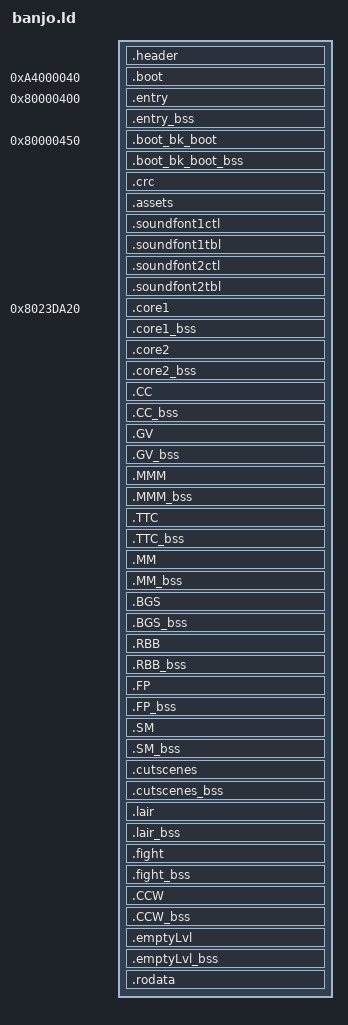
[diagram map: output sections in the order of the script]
SECTIONS
{
    __romPos = 0;
    _gp = 0x0;
    header_ROM_START = __romPos;
    header_VRAM = ADDR(.header);
    .header : AT(header_ROM_START) SUBALIGN(16)
    {
        header_DATA_START = .;
        header_s = .;
        build/us.v10/asm/header.s.o(.data);
        header_DATA_END = .;
        header_DATA_SIZE = ABSOLUTE(header_DATA_END - header_DATA_START);
    }
    __romPos += SIZEOF(.header);
    header_ROM_END = __romPos;
    header_VRAM_END = .;

    boot_ROM_START = __romPos;
    boot_VRAM = ADDR(.boot);
    .boot 0xA4000040 : AT(boot_ROM_START) SUBALIGN(16)
    {
        boot_DATA_START = .;
        ipl3_bin = .;
        build/us.v10/bin/ipl3.bin.o(.data);
        ipl3font_bin = .;
        build/us.v10/bin/ipl3font.bin.o(.data);
        boot_DATA_END = .;
        boot_DATA_SIZE = ABSOLUTE(boot_DATA_END - boot_DATA_START);
    }
    __romPos += SIZEOF(.boot);
    __romPos = ALIGN(__romPos, 16);
    boot_ROM_END = __romPos;
    boot_VRAM_END = .;

    entry_ROM_START = __romPos;
    entry_VRAM = ADDR(.entry);
    .entry 0x80000400 : AT(entry_ROM_START) SUBALIGN(16)
    {
        entry_TEXT_START = .;
        build/us.v10/asm/entry.s.o(.text);
        entry_TEXT_END = .;
        entry_TEXT_SIZE = ABSOLUTE(entry_TEXT_END - entry_TEXT_START);
        entry_DATA_START = .;
        entry_s = .;
        build/us.v10/asm/entry.s.o(.data);
        entry_DATA_END = .;
        entry_DATA_SIZE = ABSOLUTE(entry_DATA_END - entry_DATA_START);
        entry_RODATA_START = .;
        build/us.v10/asm/entry.s.o(.rodata);
        entry_RODATA_END = .;
        entry_RODATA_SIZE = ABSOLUTE(entry_RODATA_END - entry_RODATA_START);
    }
    entry_bss_VRAM = ADDR(.entry_bss);
    .entry_bss (NOLOAD) : SUBALIGN(16)
    {
        entry_BSS_START = .;
        build/us.v10/asm/entry.s.o(.bss);
        entry_BSS_END = .;
        entry_BSS_SIZE = ABSOLUTE(entry_BSS_END - entry_BSS_START);
    }
    __romPos += SIZEOF(.entry);
    __romPos = ALIGN(__romPos, 16);
    entry_ROM_END = __romPos;
    entry_VRAM_END = .;

    boot_bk_boot_ROM_START = __romPos;
    boot_bk_boot_VRAM = ADDR(.boot_bk_boot);
    .boot_bk_boot 0x80000450 : AT(boot_bk_boot_ROM_START) SUBALIGN(16)
    {
        boot_bk_boot_TEXT_START = .;
        build/us.v10/src/done/bk_boot_1050.c.o(.text);
        build/us.v10/src/done/rarezip.c.o(.text);
        build/us.v10/src/done/inflate.c.o(.text);
        build/us.v10/src/done/overlays.c.o(.text);
        build/us.v10/src/done/initialize.c.o(.text);
        build/us.v10/src/done/pirawdma.c.o(.text);
        build/us.v10/src/done/pigetstat.c.o(.text);
        build/us.v10/asm/bzero.s.o(.text);
        build/us.v10/asm/setsr.s.o(.text);
        build/us.v10/asm/getsr.s.o(.text);
        build/us.v10/asm/setfpccsr.s.o(.text);
        build/us.v10/src/done/sirawread.c.o(.text);
        build/us.v10/src/done/sirawwrite.c.o(.text);
        build/us.v10/asm/ultra/exceptasm.s.o(.text);
        build/us.v10/asm/writebackdcache.s.o(.text);
        build/us.v10/asm/invalicache.s.o(.text);
        build/us.v10/asm/maptlbrdb.s.o(.text);
        build/us.v10/src/done/pirawread.c.o(.text);
     
        build/us.v10/asm/ultra/parameters.s.o(.text);
        build/us.v10/src/done/virtualtophysical.c.o(.text);
        build/us.v10/src/done/si.c.o(.text);
        build/us.v10/src/done/thread.c.o(.text);
        build/us.v10/src/done/leointerrupt.c.o(.text);
        build/us.v10/src/done/seteventmesg.c.o(.text);
        build/us.v10/asm/ultra/setintmask.s.o(.text);
        build/us.v10/src/done/destroythread.c.o(.text);
        build/us.v10/asm/probetlb.s.o(.text);
        build/us.v10/src/done/leodiskinit.c.o(.text);
        build/us.v10/src/done/epirawdma.c.o(.text);
        build/us.v10/asm/interrupt.s.o(.text);
        build/us.v10/src/done/pimgr.c.o(.text);
        build/us.v10/src/done/cartrominit.c.o(.text);
        build/us.v10/src/done/createmesgqueue.c.o(.text);
        build/us.v10/src/done/piacs.c.o(.text);
        build/us.v10/src/done/getthreadpri.c.o(.text);
        build/us.v10/src/done/setthreadpri.c.o(.text);
        build/us.v10/src/done/createthread.c.o(.text);
        build/us.v10/src/done/devmgr.c.o(.text);
        build/us.v10/src/done/startthread.c.o(.text);
        build/us.v10/src/done/sendmesg.c.o(.text);
        build/us.v10/src/done/recvmesg.c.o(.text);
        build/us.v10/src/done/resetglobalintmask.c.o(.text);
        build/us.v10/src/done/epirawwrite.c.o(.text);
        build/us.v10/src/done/epirawread.c.o(.text);
        build/us.v10/src/done/setglobalintmask.c.o(.text);
        build/us.v10/src/done/yieldthread.c.o(.text);
        build/us.v10/src/done/kdebugserver.c.o(.text);
        boot_bk_boot_TEXT_END = .;
        boot_bk_boot_TEXT_SIZE = ABSOLUTE(boot_bk_boot_TEXT_END - boot_bk_boot_TEXT_START);
        boot_bk_boot_DATA_START = .;
        done_inflate_c = .;
        build/us.v10/src/done/inflate.c.o(.data);
        done_initialize_c = .;
        build/us.v10/src/done/initialize.c.o(.data);
        ultra_exceptasm_s = .;
        build/us.v10/asm/ultra/exceptasm.s.o(.data);
        done_thread_c = .;
        build/us.v10/src/done/thread.c.o(.data);
        done_pimgr_c = .;
        build/us.v10/src/done/pimgr.c.o(.data);
        done_piacs_c = .;
        build/us.v10/src/done/piacs.c.o(.data);
        boot_bk_boot_DATA_END = .;
        boot_bk_boot_DATA_SIZE = ABSOLUTE(boot_bk_boot_DATA_END - boot_bk_boot_DATA_START);
        boot_bk_boot_RODATA_START = .;
        build/us.v10/asm/ultra/exceptasm.s.o(.rodata);
        build/us.v10/asm/ultra/setintmask.s.o(.rodata);
        build/us.v10/src/done/devmgr.c.o(.rodata);
        boot_bk_boot_RODATA_END = .;
        boot_bk_boot_RODATA_SIZE = ABSOLUTE(boot_bk_boot_RODATA_END - boot_bk_boot_RODATA_START);
    }
    boot_bk_boot_bss_VRAM = ADDR(.boot_bk_boot_bss);
    .boot_bk_boot_bss (NOLOAD) : SUBALIGN(16)
    {
        boot_bk_boot_BSS_START = .;
        build/us.v10/src/done/bk_boot_1050.c.o(.bss);
        build/us.v10/src/done/rarezip.c.o(.bss);
        build/us.v10/src/done/inflate.c.o(.bss);
        build/us.v10/src/done/initialize.c.o(.bss);
        build/us.v10/src/done/kdebugserver.c.o(.bss);
        build/us.v10/src/done/leointerrupt.c.o(.bss);
        build/us.v10/src/done/seteventmesg.c.o(.bss);
        build/us.v10/src/done/leodiskinit.c.o(.bss);
        build/us.v10/src/done/pimgr.c.o(.bss);
        build/us.v10/src/done/cartrominit.c.o(.bss);
        build/us.v10/src/done/piacs.c.o(.bss);
        boot_bk_boot_BSS_END = .;
        boot_bk_boot_BSS_SIZE = ABSOLUTE(boot_bk_boot_BSS_END - boot_bk_boot_BSS_START);
    }
    __romPos += SIZEOF(.boot_bk_boot);
    __romPos = ALIGN(__romPos, 16);
    boot_bk_boot_ROM_END = __romPos;
    boot_bk_boot_VRAM_END = .;

    crc_ROM_START = __romPos;
    crc_VRAM = ADDR(.crc);
    .crc : AT(crc_ROM_START) SUBALIGN(16)
    {
        crc_DATA_START = .;
        crc_bin = .;
        build/us.v10/bin/crc.bin.o(.data);
        crc_DATA_END = .;
        crc_DATA_SIZE = ABSOLUTE(crc_DATA_END - crc_DATA_START);
    }
    __romPos += SIZEOF(.crc);
    __romPos = ALIGN(__romPos, 16);
    crc_ROM_END = __romPos;
    crc_VRAM_END = .;

    assets_ROM_START = __romPos;
    assets_VRAM = ADDR(.assets);
    .assets : AT(assets_ROM_START) SUBALIGN(16)
    {
        assets_DATA_START = .;
        assets_bin = .;
        build/us.v10/bin/assets.bin.o(.data);
        assets_DATA_END = .;
        assets_DATA_SIZE = ABSOLUTE(assets_DATA_END - assets_DATA_START);
    }
    __romPos += SIZEOF(.assets);
    assets_ROM_END = __romPos;
    assets_VRAM_END = .;

    soundfont1ctl_ROM_START = __romPos;
    soundfont1ctl_VRAM = ADDR(.soundfont1ctl);
    .soundfont1ctl : AT(soundfont1ctl_ROM_START) SUBALIGN(16)
    {
        soundfont1ctl_DATA_START = .;
        soundfont1ctl_bin = .;
        build/us.v10/bin/soundfont1ctl.bin.o(.data);
        soundfont1ctl_DATA_END = .;
        soundfont1ctl_DATA_SIZE = ABSOLUTE(soundfont1ctl_DATA_END - soundfont1ctl_DATA_START);
    }
    __romPos += SIZEOF(.soundfont1ctl);
    soundfont1ctl_ROM_END = __romPos;
    soundfont1ctl_VRAM_END = .;

    soundfont1tbl_ROM_START = __romPos;
    soundfont1tbl_VRAM = ADDR(.soundfont1tbl);
    .soundfont1tbl : AT(soundfont1tbl_ROM_START) SUBALIGN(16)
    {
        soundfont1tbl_DATA_START = .;
        soundfont1tbl_bin = .;
        build/us.v10/bin/soundfont1tbl.bin.o(.data);
        soundfont1tbl_DATA_END = .;
        soundfont1tbl_DATA_SIZE = ABSOLUTE(soundfont1tbl_DATA_END - soundfont1tbl_DATA_START);
    }
    __romPos += SIZEOF(.soundfont1tbl);
    soundfont1tbl_ROM_END = __romPos;
    soundfont1tbl_VRAM_END = .;

    soundfont2ctl_ROM_START = __romPos;
    soundfont2ctl_VRAM = ADDR(.soundfont2ctl);
    .soundfont2ctl : AT(soundfont2ctl_ROM_START) SUBALIGN(16)
    {
        soundfont2ctl_DATA_START = .;
        soundfont2ctl_bin = .;
        build/us.v10/bin/soundfont2ctl.bin.o(.data);
        soundfont2ctl_DATA_END = .;
        soundfont2ctl_DATA_SIZE = ABSOLUTE(soundfont2ctl_DATA_END - soundfont2ctl_DATA_START);
    }
    __romPos += SIZEOF(.soundfont2ctl);
    soundfont2ctl_ROM_END = __romPos;
    soundfont2ctl_VRAM_END = .;

    soundfont2tbl_ROM_START = __romPos;
    soundfont2tbl_VRAM = ADDR(.soundfont2tbl);
    .soundfont2tbl : AT(soundfont2tbl_ROM_START) SUBALIGN(16)
    {
        soundfont2tbl_DATA_START = .;
        soundfont2tbl_bin = .;
        build/us.v10/bin/soundfont2tbl.bin.o(.data);
        soundfont2tbl_DATA_END = .;
        soundfont2tbl_DATA_SIZE = ABSOLUTE(soundfont2tbl_DATA_END - soundfont2tbl_DATA_START);
    }
    __romPos += SIZEOF(.soundfont2tbl);
    soundfont2tbl_ROM_END = __romPos;
    soundfont2tbl_VRAM_END = .;

    core1_ROM_START = __romPos;
    core1_VRAM = ADDR(.core1);
    .core1 0x8023DA20 : AT(core1_ROM_START) SUBALIGN(4)
    {
        core1_TEXT_START = .;
        build/us.v10/src/core1/code_0.c.o(.text);
        build/us.v10/src/core1/code_660.c.o(.text);
        build/us.v10/src/core1/inflate.c.o(.text);
        build/us.v10/src/core1/code_1D00.c.o(.text);
        build/us.v10/src/core1/code_2BD0.c.o(.text);
        build/us.v10/src/core1/defragmanager.c.o(.text);
        build/us.v10/src/core1/code_2FA0.c.o(.text);
        build/us.v10/src/core1/code_31C0.c.o(.text);
        build/us.v10/src/core1/code_3250.c.o(.text);
        build/us.v10/src/core1/code_3A70.c.o(.text);
        build/us.v10/src/core1/code_5650.c.o(.text);
        build/us.v10/src/core1/code_7090.c.o(.text);
        build/us.v10/src/core1/code_72B0.c.o(.text);
        build/us.v10/src/core1/code_7F60.c.o(.text);
        build/us.v10/src/core1/code_8C50.c.o(.text);
        build/us.v10/src/core1/code_9D30.c.o(.text);
        build/us.v10/src/core1/code_ABB0.c.o(.text);
        build/us.v10/src/core1/code_CE60.c.o(.text);
        build/us.v10/src/core1/code_E360.c.o(.text);
        build/us.v10/src/core1/code_EAF0.c.o(.text);
        build/us.v10/src/core1/code_10A00.c.o(.text);
        build/us.v10/src/core1/code_11AC0.c.o(.text);
        build/us.v10/src/core1/rumblemanager.c.o(.text);
        build/us.v10/src/core1/code_13640.c.o(.text);
        build/us.v10/src/core1/code_13680.c.o(.text);
        build/us.v10/src/core1/overlaymanager.c.o(.text);
        build/us.v10/src/core1/code_13990.c.o(.text);
        build/us.v10/asm/core1/code_155F0.s.o(.text);
        build/us.v10/src/core1/overlay.c.o(.text);
        build/us.v10/src/core1/code_15770.c.o(.text);
        build/us.v10/src/core1/code_15B30.c.o(.text);
        build/us.v10/src/core1/memory.c.o(.text);
        build/us.v10/src/core1/code_18110.c.o(.text);
        build/us.v10/src/core1/code_18210.c.o(.text);
        build/us.v10/src/core1/code_18310.c.o(.text);
        build/us.v10/src/core1/code_18350.c.o(.text);
        build/us.v10/src/core1/code_1BE90.c.o(.text);
        build/us.v10/src/core1/code_1D590.c.o(.text);
        build/us.v10/asm/core1/code_1D5C0.s.o(.text);
        build/us.v10/src/core1/code_1D5D0.c.o(.text);
        build/us.v10/src/core1/code_1E360.c.o(.text);
        build/us.v10/src/core1/code_1E6E0.c.o(.text);
        build/us.v10/asm/core1/code_1E820.s.o(.text);
        build/us.v10/src/core1/audio/n_sl.c.o(.text);
        build/us.v10/src/core1/audio/n_synthesizer.c.o(.text);
        build/us.v10/src/core1/audio/event.c.o(.text);
        build/us.v10/src/core1/audio/n_synaddplayer.c.o(.text);
        build/us.v10/src/core1/audio/n_synallocvoice.c.o(.text);
        build/us.v10/src/core1/audio/n_synsetvol.c.o(.text);
        build/us.v10/src/core1/audio/n_synstartvoice.c.o(.text);
        build/us.v10/src/core1/audio/n_synsetpan.c.o(.text);
        build/us.v10/src/core1/audio/n_synsetpitch.c.o(.text);
        build/us.v10/src/core1/audio/n_synsetfxmix.c.o(.text);
        build/us.v10/src/core1/audio/n_synstopvoice.c.o(.text);
        build/us.v10/src/core1/audio/n_synfreevoice.c.o(.text);
        build/us.v10/src/core1/audio/n_csplayer.c.o(.text);
        build/us.v10/src/core1/audio/cspsetbank.c.o(.text);
        build/us.v10/src/core1/audio/cspstop.c.o(.text);
        build/us.v10/src/core1/audio/n_csq.c.o(.text);
        build/us.v10/src/core1/audio/cspsetseq.c.o(.text);
        build/us.v10/src/core1/audio/cspplay.c.o(.text);
        build/us.v10/src/core1/audio/cspsetvol.c.o(.text);
        build/us.v10/src/core1/audio/code_219D0.c.o(.text);
        build/us.v10/src/core1/audio/cspsettempo.c.o(.text);
        build/us.v10/src/core1/audio/code_21A80.c.o(.text);
        build/us.v10/src/core1/audio/cspgettempo.c.o(.text);
        build/us.v10/src/core1/audio/code_21AF0.c.o(.text);
        build/us.v10/src/core1/audio/code_21B50.c.o(.text);
        build/us.v10/src/core1/audio/n_syndelete.c.o(.text);
        build/us.v10/src/core1/audio/n_synallocfx.c.o(.text);
        build/us.v10/src/core1/audio/n_reverb.c.o(.text);
        build/us.v10/src/core1/audio/n_auxbus.c.o(.text);
        build/us.v10/src/core1/audio/n_drvrNew.c.o(.text);
        build/us.v10/src/core1/audio/n_save.c.o(.text);
        build/us.v10/src/core1/audio/n_envresample.c.o(.text);
        build/us.v10/src/core1/audio/n_env.c.o(.text);
        build/us.v10/src/core1/audio/n_seqplayer.c.o(.text);
        build/us.v10/src/core1/audio/n_synstartvoiceparam.c.o(.text);
        build/us.v10/src/core1/audio/n_mainbus.c.o(.text);
        build/us.v10/src/core1/audio/n_load.c.o(.text);
        build/us.v10/src/core1/audio/n_adpcm.c.o(.text);
        build/us.v10/src/core1/audio/n_resample.c.o(.text);
        build/us.v10/src/core1/audio/n_seq.c.o(.text);
        build/us.v10/src/core1/audio/n_synsetpriority.c.o(.text);
        build/us.v10/asm/core1/os/invaldcache.s.o(.text);
        build/us.v10/asm/core1/os/writebackdcacheall.s.o(.text);
        build/us.v10/src/core1/os/initialize.c.o(.text);
        build/us.v10/src/core1/os/createthread.c.o(.text);
        build/us.v10/src/core1/gu/sinf.c.o(.text);
        build/us.v10/src/core1/audio/cents2ratio.c.o(.text);
        build/us.v10/src/core1/audio/heapinit.c.o(.text);
        build/us.v10/asm/core1/ultra/parameters.s.o(.text);
        build/us.v10/src/core1/os/createmesgqueue.c.o(.text);
        build/us.v10/src/core1/io/aisetfreq.c.o(.text);
        build/us.v10/src/core1/audio/sl.c.o(.text);
        build/us.v10/src/core1/audio/heapalloc.c.o(.text);
        build/us.v10/src/core1/os/recvmesg.c.o(.text);
        build/us.v10/src/core1/io/aigetlen.c.o(.text);
        build/us.v10/src/core1/os/virtualtophysical.c.o(.text);
        build/us.v10/src/core1/io/aisetnextbuf.c.o(.text);
        build/us.v10/src/core1/os/pidma.c.o(.text);
        build/us.v10/src/core1/os/stopthread.c.o(.text);
        build/us.v10/src/core1/os/startthread.c.o(.text);
        build/us.v10/asm/core1/os/writebackdcache.s.o(.text);
        build/us.v10/asm/core1/invaldcache.s.o(.text);
        build/us.v10/src/core1/io/pimgr.c.o(.text);
        build/us.v10/src/core1/os/destroythread.c.o(.text);
        build/us.v10/src/core1/os/sendmesg.c.o(.text);
        build/us.v10/src/core1/os/settreadpri.c.o(.text);
        build/us.v10/src/core1/gu/mtxutil.c.o(.text);
        build/us.v10/src/core1/gu/sqrtf.c.o(.text);
        build/us.v10/src/core1/gu/cosf.c.o(.text);
        build/us.v10/asm/core1/ultra/setintmask.s.o(.text);
        build/us.v10/src/core1/io/dpsetstat.c.o(.text);
        build/us.v10/src/core1/io/sptask.c.o(.text);
        build/us.v10/src/core1/io/dpgetstat.c.o(.text);
        build/us.v10/src/core1/io/vigetcurrframebuf.c.o(.text);
        build/us.v10/src/core1/os/stoptimer.c.o(.text);
        build/us.v10/src/core1/os/settimer.c.o(.text);
        build/us.v10/src/gcc_fix/gcc_fix.c.o(.text)
        build/us.v10/src/core1/ll.c.o(.text); 
        build/us.v10/src/core1/io/sptaskyielded.c.o(.text);
        build/us.v10/src/core1/io/sptaskyield.c.o(.text);
        build/us.v10/src/core1/io/visetmode.c.o(.text);
        build/us.v10/src/core1/os/seteventmesg.c.o(.text);
        build/us.v10/src/core1/io/vimgr.c.o(.text);
        build/us.v10/src/core1/io/visetspecial.c.o(.text);
        build/us.v10/src/core1/io/viswapbuf.c.o(.text);
        build/us.v10/src/core1/io/visetevent.c.o(.text);
        build/us.v10/src/core1/io/vigetnextframebuf.c.o(.text);
        build/us.v10/src/core1/io/viblack.c.o(.text);
        build/us.v10/src/core1/gu/ortho.c.o(.text);
        build/us.v10/src/core1/gu/translate.c.o(.text);
        build/us.v10/src/core1/gu/rotate.c.o(.text);
        build/us.v10/src/core1/io/contreaddata.c.o(.text);
        build/us.v10/src/core1/io/controller.c.o(.text);
        build/us.v10/src/core1/io/contsetch.c.o(.text);
        build/us.v10/src/core1/audio/bnkf.c.o(.text);
        build/us.v10/src/core1/os/gettime.c.o(.text);
        build/us.v10/src/core1/audio/cseq.c.o(.text);
        build/us.v10/src/core1/io/motor.c.o(.text);
        build/us.v10/src/core1/io/pfsinit.c.o(.text);
        build/us.v10/asm/core1/invalicache.s.o(.text);
        build/us.v10/src/core1/io/conteeplongwrite.c.o(.text);
        build/us.v10/src/core1/io/conteeplongread.c.o(.text);
        build/us.v10/src/core1/io/piread.c.o(.text);
        build/us.v10/src/core1/audio/copy.c.o(.text);
        build/us.v10/src/core1/audio/drvrNew.c.o(.text);
        build/us.v10/src/core1/audio/reverb.c.o(.text);
        build/us.v10/src/core1/syncprintf.c.o(.text);
        build/us.v10/src/core1/audio/seq.c.o(.text);
        build/us.v10/asm/core1/setsr.s.o(.text);
        build/us.v10/asm/core1/getsr.s.o(.text);
        build/us.v10/asm/core1/setfpccsr.s.o(.text);
        build/us.v10/src/core1/io/sirawread.c.o(.text);
        build/us.v10/src/core1/io/sirawwrite.c.o(.text);
        build/us.v10/asm/core1/ultra/exceptasm.s.o(.text);
        build/us.v10/src/core1/io/pirawread.c.o(.text);
        build/us.v10/asm/core1/interrupt.s.o(.text);
        build/us.v10/src/core1/os/thread.c.o(.text);
        build/us.v10/src/core1/audio/synthesizer.c.o(.text);
        build/us.v10/src/core1/audio/syndelete.c.o(.text);
        build/us.v10/asm/core1/probetlb.s.o(.text);
        build/us.v10/src/core1/io/ai.c.o(.text);
        build/us.v10/src/core1/os/jammesg.c.o(.text);
        build/us.v10/src/core1/io/pigetcmdq.c.o(.text);
        build/us.v10/src/core1/io/cartrominit.c.o(.text);
        build/us.v10/src/core1/io/leodiskinit.c.o(.text);
        build/us.v10/src/core1/io/piacs.c.o(.text);
        build/us.v10/src/core1/os/getthreadpri.c.o(.text);
        build/us.v10/src/core1/io/pirawdma.c.o(.text);
        build/us.v10/src/core1/io/epirawdma.c.o(.text);
        build/us.v10/src/core1/io/devmgr.c.o(.text);
        build/us.v10/asm/core1/bcopy.s.o(.text);
        build/us.v10/src/core1/io/spsetstat.c.o(.text);
        build/us.v10/src/core1/io/spsetpc.c.o(.text);
        build/us.v10/src/core1/io/sprawdma.c.o(.text);
        build/us.v10/src/core1/io/sp.c.o(.text);
        build/us.v10/src/core1/io/vi.c.o(.text);
        build/us.v10/src/core1/os/timerintr.c.o(.text);
        build/us.v10/asm/core1/setcompare.s.o(.text);
        build/us.v10/src/core1/io/spgetstat.c.o(.text);
        build/us.v10/src/core1/io/vigetcurrcontext.c.o(.text);
        build/us.v10/src/core1/io/viswapcontext.c.o(.text);
        build/us.v10/asm/core1/getcount.s.o(.text);
        build/us.v10/src/core1/gu/normalize.c.o(.text);
        build/us.v10/src/core1/io/siacs.c.o(.text);
        build/us.v10/src/core1/io/sirawdma.c.o(.text);
        build/us.v10/src/core1/io/pfsisplug.c.o(.text);
        build/us.v10/src/core1/io/crc.c.o(.text);
        build/us.v10/src/core1/io/contramwrite.c.o(.text);
        build/us.v10/src/core1/io/contramread.c.o(.text);
        build/us.v10/src/core1/io/pfsgetstatus.c.o(.text);
        build/us.v10/src/core1/io/contpfs.c.o(.text);
        build/us.v10/src/core1/io/pfschecker.c.o(.text);
        build/us.v10/src/core1/io/conteepwrite.c.o(.text);
        build/us.v10/src/core1/io/conteepread.c.o(.text);
        build/us.v10/src/core1/audio/filter.c.o(.text);
        build/us.v10/src/core1/audio/env.c.o(.text);
        build/us.v10/src/core1/audio/load.c.o(.text);
        build/us.v10/src/core1/audio/resample.c.o(.text);
        build/us.v10/src/core1/audio/auxbus.c.o(.text);
        build/us.v10/src/core1/audio/mainbus.c.o(.text);
        build/us.v10/src/core1/audio/save.c.o(.text);
        build/us.v10/src/core1/io/si.c.o(.text);
        build/us.v10/src/core1/io/leointerrupt.c.o(.text);
        build/us.v10/src/core1/audio/synallocfx.c.o(.text);
        build/us.v10/src/core1/os/resetglobalintmask.c.o(.text);
        build/us.v10/src/core1/io/epirawwrite.c.o(.text);
        build/us.v10/src/core1/io/epirawread.c.o(.text);
        build/us.v10/src/core1/os/setglobalintmask.c.o(.text);
        build/us.v10/src/core1/os/yieldthread.c.o(.text);
        core1_DATA_START = .;
        
        core1_n_aspMain_text_bin = .;
        build/us.v10/bin/core1/n_aspMain_text.bin.o(.data);
        core1_gSPF3DEX_fifo_text_bin = .;
        build/us.v10/bin/core1/gSPF3DEX_fifo_text.bin.o(.data);
        core1_gSPL3DEX_fifo_text_bin = .;
        build/us.v10/bin/core1/gSPL3DEX_fifo_text.bin.o(.data);
        core1_DATA_START_OFFSET = .;
        core1_code_0_c = .;
        build/us.v10/src/core1/code_0.c.o(.data);
        core1_code_660_c = .;
        build/us.v10/src/core1/code_660.c.o(.data);
        core1_code_1D00_c = .;
        build/us.v10/src/core1/code_1D00.c.o(.data);
        core1_data_37E30_bin = .;
        build/us.v10/bin/core1/data_37E30.bin.o(.data);
        core1_code_2FA0_c = .;
        build/us.v10/src/core1/code_2FA0.c.o(.data);
        core1_code_3250_c = .;
        build/us.v10/src/core1/code_3250.c.o(.data);
        core1_code_3A70_c = .;
        build/us.v10/src/core1/code_3A70.c.o(.data);
        core1_code_5650_c = .;
        build/us.v10/src/core1/code_5650.c.o(.data);
        core1_code_7090_c = .;
        build/us.v10/src/core1/code_7090.c.o(.data);
        core1_data_37ED0_bin = .;
        build/us.v10/bin/core1/data_37ED0.bin.o(.data);
        core1_code_7F60_c = .;
        build/us.v10/src/core1/code_7F60.c.o(.data);
        core1_code_8C50_c = .;
        build/us.v10/src/core1/code_8C50.c.o(.data);
        core1_code_9D30_c = .;
        build/us.v10/src/core1/code_9D30.c.o(.data);
        core1_code_ABB0_c = .;
        build/us.v10/src/core1/code_ABB0.c.o(.data);
        core1_code_CE60_c = .;
        build/us.v10/src/core1/code_CE60.c.o(.data);
        core1_code_E360_c = .;
        build/us.v10/src/core1/code_E360.c.o(.data);
        core1_code_EAF0_c = .;
        build/us.v10/src/core1/code_EAF0.c.o(.data);
        core1_code_10A00_c = .;
        build/us.v10/src/core1/code_10A00.c.o(.data);
        core1_code_11AC0_c = .;
        build/us.v10/src/core1/code_11AC0.c.o(.data);
        core1_overlaymanager_c = .;
        build/us.v10/src/core1/overlaymanager.c.o(.data);
        core1_code_13990_c = .;
        build/us.v10/src/core1/code_13990.c.o(.data);
        core1_code_15B30_c = .;
        build/us.v10/src/core1/code_15B30.c.o(.data);
        core1_memory_c = .;
        build/us.v10/src/core1/memory.c.o(.data);
        core1_code_18310_c = .;
        build/us.v10/src/core1/code_18310.c.o(.data);
        core1_code_18350_c = .;
        build/us.v10/src/core1/code_18350.c.o(.data);
        core1_code_1BE90_c = .;
        build/us.v10/src/core1/code_1BE90.c.o(.data);
        core1_code_1D5D0_c = .;
        build/us.v10/src/core1/code_1D5D0.c.o(.data);
        core1_code_1E360_c = .;
        build/us.v10/src/core1/code_1E360.c.o(.data);
        core1_data_1E820_c = .;
        build/us.v10/src/core1/data_1E820.c.o(.data);
        core1_audio_n_sl_c = .;
        build/us.v10/src/core1/audio/n_sl.c.o(.data);
        core1_audio_n_drvrNew_c = .;
        build/us.v10/src/core1/audio/n_drvrNew.c.o(.data);
        core1_audio_n_env_c = .;
        build/us.v10/src/core1/audio/n_env.c.o(.data);
        core1_os_initialize_c = .;
        build/us.v10/src/core1/os/initialize.c.o(.data);
        core1_audio_sl_c = .;
        build/us.v10/src/core1/audio/sl.c.o(.data);
        core1_io_aisetnextbuf_c = .;
        build/us.v10/src/core1/io/aisetnextbuf.c.o(.data);
        core1_io_pimgr_c = .;
        build/us.v10/src/core1/io/pimgr.c.o(.data);
        core1_io_vimgr_c = .;
        build/us.v10/src/core1/io/vimgr.c.o(.data);
        core1_io_controller_c = .;
        build/us.v10/src/core1/io/controller.c.o(.data);
        core1_audio_drvrNew_c = .;
        build/us.v10/src/core1/audio/drvrNew.c.o(.data);
        core1_ultra_exceptasm_s = .;
        build/us.v10/asm/core1/ultra/exceptasm.s.o(.data);
        core1_os_thread_c = .;
        build/us.v10/src/core1/os/thread.c.o(.data);
        core1_io_piacs_c = .;
        build/us.v10/src/core1/io/piacs.c.o(.data);
        core1_io_vi_c = .;
        build/us.v10/src/core1/io/vi.c.o(.data);
        core1_os_timerintr_c = .;
        build/us.v10/src/core1/os/timerintr.c.o(.data);
        core1_io_siacs_c = .;
        build/us.v10/src/core1/io/siacs.c.o(.data);
        core1_audio_env_c = .;
        build/us.v10/src/core1/audio/env.c.o(.data);
        core1_io_vimodepallan1_c = .;
        build/us.v10/src/core1/io/vimodepallan1.c.o(.data);
        core1_io_vimodempallan1_c = .;
        build/us.v10/src/core1/io/vimodempallan1.c.o(.data);
        core1_io_vimodentsclan1_c = .;
        build/us.v10/src/core1/io/vimodentsclan1.c.o(.data);
         build/us.v10/src/core1/gu/rotate.c.o(.data);
        core1_RODATA_START = .;

        build/us.v10/src/core1/io/aisetfreq.c.o(.rodata);
        build/us.v10/src/core1/io/viswapcontext.c.o(.rodata);
        build/us.v10/src/core1/io/devmgr.c.o(.rodata);
        build/us.v10/src/core1/code_1D00.c.o(.rodata);
        build/us.v10/src/core1/code_3250.c.o(.rodata);
        build/us.v10/src/core1/gu/mtxutil.c.o(.rodata);
        build/us.v10/src/core1/code_3A70.c.o(.rodata);
        build/us.v10/src/core1/code_5650.c.o(.rodata);
        build/us.v10/src/core1/code_72B0.c.o(.rodata);
        build/us.v10/src/core1/code_7F60.c.o(.rodata);
        build/us.v10/src/core1/code_9D30.c.o(.rodata);
        build/us.v10/src/core1/code_CE60.c.o(.rodata);
        build/us.v10/src/core1/code_EAF0.c.o(.rodata);
        build/us.v10/src/core1/code_10A00.c.o(.rodata);
        build/us.v10/src/core1/code_11AC0.c.o(.rodata);
        build/us.v10/src/core1/rumblemanager.c.o(.rodata);
        build/us.v10/src/core1/overlaymanager.c.o(.rodata);
        build/us.v10/src/core1/code_13990.c.o(.rodata);
        build/us.v10/src/core1/code_18350.c.o(.rodata);
        build/us.v10/src/core1/code_1BE90.c.o(.rodata);
        build/us.v10/src/core1/code_1D5D0.c.o(.rodata);
        build/us.v10/src/core1/audio/n_synthesizer.c.o(.rodata);
        build/us.v10/src/core1/audio/n_csplayer.c.o(.rodata);
        build/us.v10/src/core1/audio/n_reverb.c.o(.rodata);
        build/us.v10/src/core1/audio/n_drvrNew.c.o(.rodata);
        build/us.v10/src/core1/audio/n_env.c.o(.rodata);
        build/us.v10/src/core1/audio/n_seqplayer.c.o(.rodata);
        build/us.v10/src/core1/audio/n_resample.c.o(.rodata);
        build/us.v10/src/core1/gu/sinf.c.o(.rodata);
        build/us.v10/src/core1/audio/cents2ratio.c.o(.rodata);
        build/us.v10/src/core1/gu/cosf.c.o(.rodata);
        build/us.v10/asm/core1/ultra/setintmask.s.o(.rodata);
        build/us.v10/src/core1/gu/rotate.c.o(.rodata);
        build/us.v10/src/core1/gu/ortho.c.o(.rodata);
        build/us.v10/src/core1/gu/normalize.c.o(.rodata);
        build/us.v10/src/core1/gu/translate.c.o(.rodata);
        build/us.v10/src/core1/audio/cseq.c.o(.rodata);
        build/us.v10/src/core1/audio/drvrNew.c.o(.rodata);
        build/us.v10/src/core1/audio/reverb.c.o(.rodata);
        build/us.v10/src/core1/audio/seq.c.o(.rodata);
        build/us.v10/asm/core1/ultra/exceptasm.s.o(.rodata);
        build/us.v10/src/core1/audio/n_csq.c.o(.rodata);
        build/us.v10/src/core1/code_2FA0.c.o(.rodata);
        build/us.v10/src/core1/code_ABB0.c.o(.rodata);
        build/us.v10/src/core1/code_15B30.c.o(.rodata);
        build/us.v10/src/core1/code_660.c.o(.rodata)
        build/us.v10/src/gcc_fix/gcc_fix.c.o(.rodata)
        build/us.v10/asm/core1/ultra/libm_vals.s.o(.text);
        core1_TEXT_END = .;
        core1_TEXT_SIZE = ABSOLUTE(core1_TEXT_END - core1_TEXT_START);
        build/us.v10/asm/core1/ultra/libm_vals.s.o(.rodata);
        build/us.v10/src/core1/audio/synthesizer.c.o(.rodata);
        build/us.v10/src/core1/io/devmgr.c.o(.rodata);
        build/us.v10/src/core1/audio/env.c.o(.rodata);
        build/us.v10/src/core1/audio/resample.c.o(.rodata);
        core1_RODATA_END = .;
        core1_RODATA_SIZE = ABSOLUTE(core1_RODATA_END - core1_RODATA_START);
        core1_n_aspMain_data_bin = .;
        build/us.v10/bin/core1/n_aspMain_data.bin.o(.data);
        core1_gSPF3DEX_fifo_data_bin = .;
        build/us.v10/bin/core1/gSPF3DEX_fifo_data.bin.o(.data);
        core1_gSPL3DEX_fifo_data_bin = .;
        build/us.v10/bin/core1/gSPL3DEX_fifo_data.bin.o(.data);
        core1_DATA_END = .;
        
        core1_DATA_SIZE = ABSOLUTE(core1_DATA_END - core1_DATA_START);
    }
    core1_bss_VRAM = ADDR(.core1_bss);
    .core1_bss (NOLOAD) : SUBALIGN(4)
    {
        core1_BSS_START = .;
        build/us.v10/src/core1/code_0.c.o(.bss);
        build/us.v10/src/core1/code_660.c.o(.bss);
        build/us.v10/src/core1/inflate.c.o(.bss);
        build/us.v10/src/core1/code_1D00.c.o(.bss);
        build/us.v10/src/core1/code_2BD0.c.o(.bss);
        build/us.v10/src/core1/defragmanager.c.o(.bss);
        build/us.v10/src/core1/code_31C0.c.o(.bss);
        build/us.v10/src/core1/code_5650.c.o(.bss);
        build/us.v10/src/core1/code_7090.c.o(.bss);
        build/us.v10/src/core1/code_72B0.c.o(.bss);
        build/us.v10/src/core1/code_8C50.c.o(.bss);
        build/us.v10/src/core1/code_ABB0.c.o(.bss);
        build/us.v10/src/core1/code_CE60.c.o(.bss);
        build/us.v10/src/core1/code_E360.c.o(.bss);
        build/us.v10/src/core1/code_EAF0.c.o(.bss);
        build/us.v10/src/core1/code_10A00.c.o(.bss);
        build/us.v10/src/core1/code_11AC0.c.o(.bss);
        build/us.v10/src/core1/rumblemanager.c.o(.bss);
        build/us.v10/src/core1/code_13640.c.o(.bss);
        build/us.v10/src/core1/overlaymanager.c.o(.bss);
        build/us.v10/src/core1/code_13990.c.o(.bss);
        build/us.v10/src/core1/code_15770.c.o(.bss);
        build/us.v10/src/core1/code_15B30.c.o(.bss);
        build/us.v10/src/core1/memory.c.o(.bss);
        build/us.v10/src/core1/code_18210.c.o(.bss);
        build/us.v10/src/core1/code_1D5D0.c.o(.bss);
        build/us.v10/src/core1/code_1E360.c.o(.bss);
        build/us.v10/src/core1/os/initialize.c.o(.bss);
        build/us.v10/src/core1/io/pimgr.c.o(.bss);
        build/us.v10/src/core1/io/sptask.c.o(.bss);
        build/us.v10/src/core1/os/seteventmesg.c.o(.bss);
        build/us.v10/src/core1/io/vimgr.c.o(.bss);
        build/us.v10/src/core1/gu/rotate.c.o(.bss);
        build/us.v10/src/core1/io/controller.c.o(.bss);
        build/us.v10/src/core1/io/motor.c.o(.bss);
        build/us.v10/src/core1/io/cartrominit.c.o(.bss);
        build/us.v10/src/core1/io/leodiskinit.c.o(.bss);
        build/us.v10/src/core1/io/piacs.c.o(.bss);
        build/us.v10/src/core1/os/timerintr.c.o(.bss);
        build/us.v10/src/core1/io/siacs.c.o(.bss);
        build/us.v10/src/core1/io/pfsisplug.c.o(.bss);
        build/us.v10/src/core1/io/conteepread.c.o(.bss);
        build/us.v10/src/core1/os/kdebugserver.c.o(.bss);
        build/us.v10/src/core1/io/leointerrupt.c.o(.bss);
        core1_BSS_END = .;
        core1_BSS_SIZE = ABSOLUTE(core1_BSS_END - core1_BSS_START);
    }
    __romPos += SIZEOF(.core1);
    __romPos = ALIGN(__romPos, 16);
    core1_ROM_END = __romPos;
    core1_VRAM_END = .;

    core2_ROM_START = __romPos;
    core2_VRAM = ADDR(.core2);
    .core2 core1_VRAM_END : AT(core2_ROM_START) SUBALIGN(16)
    {
        core2_TEXT_START = .;
        build/us.v10/src/core2/animctrl.c.o(.text);
        build/us.v10/src/core2/anim/sprite.c.o(.text);
        build/us.v10/src/core2/animcache.c.o(.text);
        build/us.v10/src/core2/code_1550.c.o(.text);
        build/us.v10/src/core2/code_1930.c.o(.text);
        build/us.v10/src/core2/code_2240.c.o(.text);
        build/us.v10/src/core2/ba/anim.c.o(.text);
        build/us.v10/src/core2/snackerctl.c.o(.text);
        build/us.v10/src/core2/code_39D0.c.o(.text);
        build/us.v10/src/core2/ba/marker.c.o(.text);
        build/us.v10/src/core2/code_6B30.c.o(.text);
        build/us.v10/src/core2/code_7060.c.o(.text);
        build/us.v10/src/core2/code_8DA0.c.o(.text);
        build/us.v10/src/core2/code_90E0.c.o(.text);
        build/us.v10/src/core2/code_9290.c.o(.text);
        build/us.v10/src/core2/code_9450.c.o(.text);
        build/us.v10/src/core2/code_9900.c.o(.text);
        build/us.v10/src/core2/code_9BD0.c.o(.text);
        build/us.v10/src/core2/code_A600.c.o(.text);
        build/us.v10/src/core2/statetimer.c.o(.text);
        build/us.v10/src/core2/code_A960.c.o(.text);
        build/us.v10/src/core2/ba/model.c.o(.text);
        build/us.v10/src/core2/ba/drone.c.o(.text);
        build/us.v10/src/core2/code_B850.c.o(.text);
        build/us.v10/src/core2/eggshatter.c.o(.text);
        build/us.v10/src/core2/code_BD20.c.o(.text);
        build/us.v10/src/core2/ba/falldamage.c.o(.text);
        build/us.v10/src/core2/code_C3F0.c.o(.text);
        build/us.v10/src/core2/code_C4B0.c.o(.text);
        build/us.v10/src/core2/ba/carry.c.o(.text);
        build/us.v10/src/core2/code_D9B0.c.o(.text);
        build/us.v10/src/core2/code_DF70.c.o(.text);
        build/us.v10/src/core2/code_E410.c.o(.text);
        build/us.v10/src/core2/abilityprogress.c.o(.text);
        build/us.v10/src/core2/code_E910.c.o(.text);
        build/us.v10/src/core2/code_EE40.c.o(.text);
        build/us.v10/src/core2/code_EF50.c.o(.text);
        build/us.v10/src/core2/ba/physics.c.o(.text);
        build/us.v10/src/core2/code_10CD0.c.o(.text);
        build/us.v10/src/core2/pitch.c.o(.text);
        build/us.v10/src/core2/code_11040.c.o(.text);
        build/us.v10/src/core2/climb.c.o(.text);
        build/us.v10/src/core2/code_11460.c.o(.text);
        build/us.v10/src/core2/code_11660.c.o(.text);
        build/us.v10/src/core2/code_117D0.c.o(.text);
        build/us.v10/src/core2/code_11870.c.o(.text);
        build/us.v10/src/core2/roll.c.o(.text);
        build/us.v10/src/core2/yaw.c.o(.text);
        build/us.v10/src/core2/code_12360.c.o(.text);
        build/us.v10/src/core2/code_126C0.c.o(.text);
        build/us.v10/src/core2/code_12F30.c.o(.text);
        build/us.v10/src/core2/bsList.c.o(.text);
        build/us.v10/src/core2/code_13780.c.o(.text);
        build/us.v10/src/core2/bsStoredState.c.o(.text);
        build/us.v10/src/core2/code_13A00.c.o(.text);
        build/us.v10/src/core2/code_13FC0.c.o(.text);
        build/us.v10/src/core2/code_14420.c.o(.text);
        build/us.v10/src/core2/code_15F20.c.o(.text);
        build/us.v10/src/core2/code_16010.c.o(.text);
        build/us.v10/src/core2/code_16C60.c.o(.text);
        build/us.v10/src/core2/code_171F0.c.o(.text);
        build/us.v10/src/core2/bs/ant.c.o(.text);
        build/us.v10/src/core2/bs/bBarge.c.o(.text);
        build/us.v10/src/core2/bs/bbuster.c.o(.text);
        build/us.v10/src/core2/bs/bee.c.o(.text);
        build/us.v10/src/core2/bs/beeFly.c.o(.text);
        build/us.v10/src/core2/bs/beeMain.c.o(.text);
        build/us.v10/src/core2/bs/bEggAss.c.o(.text);
        build/us.v10/src/core2/bs/bEggHead.c.o(.text);
        build/us.v10/src/core2/bs/bFlap.c.o(.text);
        build/us.v10/src/core2/bs/bFlip.c.o(.text);
        build/us.v10/src/core2/bs/bFly.c.o(.text);
        build/us.v10/src/core2/bs/bLongLeg.c.o(.text);
        build/us.v10/src/core2/bs/bPeck.c.o(.text);
        build/us.v10/src/core2/bs/bShock.c.o(.text);
        build/us.v10/src/core2/bs/bSwim.c.o(.text);
        build/us.v10/src/core2/bs/bTrot.c.o(.text);
        build/us.v10/src/core2/bs/bWhirl.c.o(.text);
        build/us.v10/src/core2/bs/carry.c.o(.text);
        build/us.v10/src/core2/bs/claw.c.o(.text);
        build/us.v10/src/core2/bs/climb.c.o(.text);
        build/us.v10/src/core2/bs/croc.c.o(.text);
        build/us.v10/src/core2/bs/crouch.c.o(.text);
        build/us.v10/src/core2/bs/die.c.o(.text);
        build/us.v10/src/core2/bs/drone.c.o(.text);
        build/us.v10/src/core2/bs/droneenter.c.o(.text);
        build/us.v10/src/core2/bs/dronegoto.c.o(.text);
        build/us.v10/src/core2/bs/dronelook.c.o(.text);
        build/us.v10/src/core2/bs/dronevanish.c.o(.text);
        build/us.v10/src/core2/bs/dronexform.c.o(.text);
        build/us.v10/src/core2/bs/jig.c.o(.text);
        build/us.v10/src/core2/bs/jump.c.o(.text);
        build/us.v10/src/core2/bs/ow.c.o(.text);
        build/us.v10/src/core2/bs/pumpkin.c.o(.text);
        build/us.v10/src/core2/bs/rebound.c.o(.text);
        build/us.v10/src/core2/bs/rest.c.o(.text);
        build/us.v10/src/core2/bs/sled.c.o(.text);
        build/us.v10/src/core2/bs/slide.c.o(.text);
        build/us.v10/src/core2/bs/splat.c.o(.text);
        build/us.v10/src/core2/bs/stand.c.o(.text);
        build/us.v10/src/core2/bs/swim.c.o(.text);
        build/us.v10/src/core2/bs/surf.c.o(.text);
        build/us.v10/src/core2/bs/talk.c.o(.text);
        build/us.v10/src/core2/bs/timeout.c.o(.text);
        build/us.v10/src/core2/bs/throw.c.o(.text);
        build/us.v10/src/core2/bs/turn.c.o(.text);
        build/us.v10/src/core2/bs/twirl.c.o(.text);
        build/us.v10/src/core2/bs/walk.c.o(.text);
        build/us.v10/src/core2/bs/walrus.c.o(.text);
        build/us.v10/src/core2/bs/washy.c.o(.text);
        build/us.v10/src/core2/nc/cameranodelist.c.o(.text);
        build/us.v10/src/core2/code_33250.c.o(.text);
        build/us.v10/src/core2/code_33310.c.o(.text);
        build/us.v10/src/core2/code_336F0.c.o(.text);
        build/us.v10/src/core2/code_33AB0.c.o(.text);
        build/us.v10/src/core2/code_33C30.c.o(.text);
        build/us.v10/src/core2/nc/staticCamera.c.o(.text);
        build/us.v10/src/core2/code_33F90.c.o(.text);
        build/us.v10/src/core2/code_34310.c.o(.text);
        build/us.v10/src/core2/code_34790.c.o(.text);
        build/us.v10/src/core2/code_35520.c.o(.text);
        build/us.v10/src/core2/nc/dynamicCamera.c.o(.text);
        build/us.v10/src/core2/code_379B0.c.o(.text);
        build/us.v10/src/core2/nc/randomCamera.c.o(.text);
        build/us.v10/src/core2/code_37E50.c.o(.text);
        build/us.v10/src/core2/nc/dynamicCam10.c.o(.text);
        build/us.v10/src/core2/nc/dynamicCamD.c.o(.text);
        build/us.v10/src/core2/nc/dynamicCam5.c.o(.text);
        build/us.v10/src/core2/nc/dynamicCam11.c.o(.text);
        build/us.v10/src/core2/nc/dynamicCam8.c.o(.text);
        build/us.v10/src/core2/nc/dynamicCam4.c.o(.text);
        build/us.v10/src/core2/nc/dynamicCamC.c.o(.text);
        build/us.v10/src/core2/code_F8EAF0.c.o(.text);
        build/us.v10/src/core2/nc/dynamicCamB.c.o(.text);
        build/us.v10/src/core2/nc/dynamicCam13.c.o(.text);
        build/us.v10/src/core2/nc/dynamicCam9.c.o(.text);
        build/us.v10/src/core2/nc/dynamicCam12.c.o(.text);
        build/us.v10/src/core2/nc/dynamicCam1.c.o(.text);
        build/us.v10/src/core2/nc/dynamicCam3.c.o(.text);
        build/us.v10/src/core2/nc/dynamicCamA.c.o(.text);
        build/us.v10/src/core2/code_3B2C0.c.o(.text);
        build/us.v10/src/core2/nc/dynamicCamF.c.o(.text);
        build/us.v10/src/core2/nc/firstpersoncamera.c.o(.text);
        build/us.v10/src/core2/spawnqueue.c.o(.text);
        build/us.v10/src/core2/ch/gameSelect.c.o(.text);
        build/us.v10/src/core2/code_3EAD0.c.o(.text);
        build/us.v10/src/core2/code_3EC30.c.o(.text);
        build/us.v10/src/core2/ch/bubble.c.o(.text);
        build/us.v10/src/core2/ch/bigbutt.c.o(.text);
        build/us.v10/src/core2/code_400F0.c.o(.text);
        build/us.v10/src/core2/ch/jiggy.c.o(.text);
        build/us.v10/src/core2/ch/jigsawdance.c.o(.text);
        build/us.v10/src/core2/code_41460.c.o(.text);
        build/us.v10/src/core2/code_41F30.c.o(.text);
        build/us.v10/src/core2/code_41FB0.c.o(.text);
        build/us.v10/src/core2/ch/musicnote.c.o(.text);
        build/us.v10/src/core2/code_42CB0.c.o(.text);
        build/us.v10/src/core2/code_43250.c.o(.text);
        build/us.v10/src/core2/ch/trainers.c.o(.text);
        build/us.v10/src/core2/code_43800.c.o(.text);
        build/us.v10/src/core2/code_43A40.c.o(.text);
        build/us.v10/src/core2/mapspecificflags.c.o(.text);
        build/us.v10/src/core2/ch/crab.c.o(.text);
        build/us.v10/src/core2/code_45310.c.o(.text);
        build/us.v10/src/core2/ch/code_468E0.c.o(.text);
        build/us.v10/src/core2/ch/jinjo.c.o(.text);
        build/us.v10/src/core2/ch/beehive.c.o(.text);
        build/us.v10/src/core2/code_47BD0.c.o(.text);
        build/us.v10/src/core2/ch/soundsource.c.o(.text);
        build/us.v10/src/core2/ch/shrapnel.c.o(.text);
        build/us.v10/src/core2/ch/gloop.c.o(.text);
        build/us.v10/src/core2/code_4A6F0.c.o(.text);
        build/us.v10/src/core2/code_4BD70.c.o(.text);
        build/us.v10/src/core2/code_4BE10.c.o(.text);
        build/us.v10/src/core2/code_4C020.c.o(.text);
        build/us.v10/src/core2/ch/wadingboots.c.o(.text);
        build/us.v10/src/core2/ch/badShad.c.o(.text);
        build/us.v10/src/core2/code_50490.c.o(.text);
        build/us.v10/src/core2/ch/climbBase.c.o(.text);
        build/us.v10/src/core2/code_509D0.c.o(.text);
        build/us.v10/src/core2/code_517A0.c.o(.text);
        build/us.v10/src/core2/code_51950.c.o(.text);
        build/us.v10/src/core2/ch/collectible.c.o(.text);
        build/us.v10/src/core2/ch/mole.c.o(.text);
        build/us.v10/src/core2/ch/molehill.c.o(.text);
        build/us.v10/src/core2/code_53A10.c.o(.text);
        build/us.v10/src/core2/code_53C10.c.o(.text);
        build/us.v10/src/core2/code_54D50.c.o(.text);
        build/us.v10/src/core2/code_55180.c.o(.text);
        build/us.v10/src/core2/code_55390.c.o(.text);
        build/us.v10/src/core2/code_556C0.c.o(.text);
        build/us.v10/src/core2/code_55850.c.o(.text);
        build/us.v10/src/core2/ch/overlaycopyright.c.o(.text);
        build/us.v10/src/core2/ch/overlaypressstart.c.o(.text);
        build/us.v10/src/core2/ch/overlaynocontroller.c.o(.text);
        build/us.v10/src/core2/ch/bottlesbonus.c.o(.text);
        build/us.v10/src/core2/code_57C70.c.o(.text);
        build/us.v10/src/core2/code_581D0.c.o(.text);
        build/us.v10/src/core2/ch/bottlesbonuscursor.c.o(.text);
        build/us.v10/src/core2/code_59780.c.o(.text);
        build/us.v10/src/core2/code_599E0.c.o(.text);
        build/us.v10/src/core2/code_59A80.c.o(.text);
        build/us.v10/src/core2/ch/snacker.c.o(.text);
        build/us.v10/src/core2/ch/snowman.c.o(.text);
        build/us.v10/src/core2/ch/snowball.c.o(.text);
        build/us.v10/src/core2/ch/snowmanhat.c.o(.text);
        build/us.v10/src/core2/code_5BEB0.c.o(.text);
        build/us.v10/src/core2/code_5C240.c.o(.text);
        build/us.v10/src/core2/code_5C870.c.o(.text);
        build/us.v10/src/core2/code_5DBC0.c.o(.text);
        build/us.v10/src/core2/code_5FB00.c.o(.text);
        build/us.v10/src/core2/code_5FD80.c.o(.text);
        build/us.v10/src/core2/code_5FD90.c.o(.text);
        build/us.v10/src/core2/code_62FD0.c.o(.text);
        build/us.v10/src/core2/code_630D0.c.o(.text);
        build/us.v10/src/core2/code_63410.c.o(.text);
        build/us.v10/src/core2/code_63690.c.o(.text);
        build/us.v10/src/core2/code_637D0.c.o(.text);
        build/us.v10/src/core2/code_654C0.c.o(.text);
        build/us.v10/src/core2/code_66490.c.o(.text);
        build/us.v10/src/core2/vla.c.o(.text);
        build/us.v10/src/core2/fla.c.o(.text);
        build/us.v10/src/core2/code_66D90.c.o(.text);
        build/us.v10/src/core2/code_66FB0.c.o(.text);
        build/us.v10/src/core2/gc/bound.c.o(.text);
        build/us.v10/src/core2/code_67650.c.o(.text);
        build/us.v10/src/core2/particle.c.o(.text);
        build/us.v10/src/core2/code_69F60.c.o(.text);
        build/us.v10/src/core2/code_6A4B0.c.o(.text);
        build/us.v10/src/core2/code_6AEF0.c.o(.text);
        build/us.v10/src/core2/code_6B030.c.o(.text);
        build/us.v10/src/core2/fx/ripple.c.o(.text);
        build/us.v10/src/core2/fx/sparkle.c.o(.text);
        build/us.v10/src/core2/code_6CD20.c.o(.text);
        build/us.v10/src/core2/code_6CEC0.c.o(.text);
        build/us.v10/src/core2/code_6D030.c.o(.text);
        build/us.v10/src/core2/code_6D270.c.o(.text);
        build/us.v10/src/core2/code_6D490.c.o(.text);
        build/us.v10/src/core2/code_6DA30.c.o(.text);
        build/us.v10/src/core2/code_70C30.c.o(.text);
        build/us.v10/src/core2/code_70F20.c.o(.text);
        build/us.v10/src/core2/code_71820.c.o(.text);
        build/us.v10/src/core2/code_72060.c.o(.text);
        build/us.v10/src/core2/code_72B10.c.o(.text);
        build/us.v10/src/core2/code_73640.c.o(.text);
        build/us.v10/src/core2/code_74090.c.o(.text);
        build/us.v10/src/core2/code_74290.c.o(.text);
        build/us.v10/src/core2/code_74420.c.o(.text);
        build/us.v10/src/core2/code_74910.c.o(.text);
        build/us.v10/src/core2/code_74ED0.c.o(.text);
        build/us.v10/src/core2/code_75480.c.o(.text);
        build/us.v10/src/core2/code_75930.c.o(.text);
        build/us.v10/src/core2/code_75E90.c.o(.text);
        build/us.v10/src/core2/fx/common1score.c.o(.text);
        build/us.v10/src/core2/fx/common2score.c.o(.text);
        build/us.v10/src/core2/fx/honeycarrierscore.c.o(.text);
        build/us.v10/src/core2/code_77E50.c.o(.text);
        build/us.v10/src/core2/fx/jinjoscore.c.o(.text);
        build/us.v10/src/core2/fx/lifescore.c.o(.text);
        build/us.v10/src/core2/fx/common3score.c.o(.text);
        build/us.v10/src/core2/fx/healthscore.c.o(.text);
        build/us.v10/src/core2/fx/airscore.c.o(.text);
        build/us.v10/src/core2/code_7AF80.c.o(.text);
        build/us.v10/src/core2/mapModel.c.o(.text);
        build/us.v10/src/core2/code_83340.c.o(.text);
        build/us.v10/src/core2/gc/section.c.o(.text);
        build/us.v10/src/core2/gc/sky.c.o(.text);
        build/us.v10/src/core2/gc/transition.c.o(.text);
        build/us.v10/src/core2/code_851D0.c.o(.text);
        build/us.v10/src/core2/code_857B0.c.o(.text);
        build/us.v10/src/core2/code_85800.c.o(.text);
        build/us.v10/src/core2/gc/dialog.c.o(.text);
        build/us.v10/src/core2/gc/pauseMenu.c.o(.text);
        build/us.v10/src/core2/code_8DC20.c.o(.text);
        build/us.v10/src/core2/gc/zoombox.c.o(.text);
        build/us.v10/src/core2/code_91E10.c.o(.text);
        build/us.v10/src/core2/code_935F0.c.o(.text);
        build/us.v10/src/core2/gc/parade.c.o(.text);
        build/us.v10/src/core2/code_94620.c.o(.text);
        build/us.v10/src/core2/code_94780.c.o(.text);
        build/us.v10/src/core2/code_94A20.c.o(.text);
        build/us.v10/src/core2/code_956B0.c.o(.text);
        build/us.v10/src/core2/code_98CB0.c.o(.text);
        build/us.v10/src/core2/quizquestionaskedbitfield.c.o(.text);
        build/us.v10/src/core2/code_999A0.c.o(.text);
        build/us.v10/src/core2/jiggyscore.c.o(.text);
        build/us.v10/src/core2/honeycombscore.c.o(.text);
        build/us.v10/src/core2/mumboscore.c.o(.text);
        build/us.v10/src/core2/code_9A740.c.o(.text);
        build/us.v10/src/core2/code_9A9D0.c.o(.text);
        build/us.v10/src/core2/levelspecificflags.c.o(.text);
        build/us.v10/src/core2/code_9B180.c.o(.text);
        build/us.v10/src/core2/code_9B650.c.o(.text);
        build/us.v10/src/core2/code_9B990.c.o(.text);
        build/us.v10/src/core2/code_9C170.c.o(.text);
        build/us.v10/src/core2/code_9D640.c.o(.text);
        build/us.v10/src/core2/code_9D760.c.o(.text);
        build/us.v10/src/core2/timedfuncqueue.c.o(.text);
        build/us.v10/src/core2/code_9E370.c.o(.text);
        build/us.v10/src/core2/code_A4D00.c.o(.text);
        build/us.v10/src/core2/code_A5BC0.c.o(.text);
        build/us.v10/src/core2/code_ABC00.c.o(.text);
        build/us.v10/src/core2/code_AC520.c.o(.text);
        build/us.v10/src/core2/code_AD110.c.o(.text);
        build/us.v10/src/core2/code_AD5B0.c.o(.text);
        build/us.v10/src/core2/code_AE290.c.o(.text);
        build/us.v10/src/core2/skeletalanim.c.o(.text);
        build/us.v10/src/core2/code_AEDA0.c.o(.text);
        build/us.v10/src/core2/modelRender.c.o(.text);
        build/us.v10/src/core2/code_B3580.c.o(.text);
        build/us.v10/src/core2/code_B3A80.c.o(.text);
        build/us.v10/src/core2/code_B5040.c.o(.text);
        build/us.v10/src/core2/code_B5E00.c.o(.text);
        build/us.v10/src/core2/code_B62B0.c.o(.text);
        build/us.v10/src/core2/code_B6640.c.o(.text);
        build/us.v10/src/core2/string.c.o(.text);
        build/us.v10/src/core2/code_B6C60.c.o(.text);
        build/us.v10/src/core2/code_B6CE0.c.o(.text);
        build/us.v10/src/core2/code_B6EA0.c.o(.text);
        build/us.v10/src/core2/code_B7B20.c.o(.text);
        build/us.v10/src/core2/code_B7F40.c.o(.text);
        build/us.v10/src/core2/code_B8020.c.o(.text);
        build/us.v10/src/core2/code_B8070.c.o(.text);
        build/us.v10/src/core2/code_B8080.c.o(.text);
        build/us.v10/src/core2/code_B8860.c.o(.text);
        build/us.v10/src/core2/code_B9090.c.o(.text);
        build/us.v10/src/core2/code_B9770.c.o(.text);
        build/us.v10/src/core2/code_BD100.c.o(.text);
        build/us.v10/src/core2/code_BDCC0.c.o(.text);
        build/us.v10/src/core2/code_BE2C0.c.o(.text);
        build/us.v10/src/core2/code_BEF20.c.o(.text);
        build/us.v10/src/core2/code_C0B80.c.o(.text);
        build/us.v10/src/core2/code_C0CF0.c.o(.text);
        build/us.v10/src/core2/code_C0E60.c.o(.text);
        build/us.v10/src/core2/animtexturecache.c.o(.text);
        build/us.v10/src/core2/code_C2F30.c.o(.text);
        build/us.v10/src/core2/code_C31A0.c.o(.text);
        build/us.v10/src/core2/rand.c.o(.text);
        build/us.v10/src/core2/code_C3A40.c.o(.text);
        build/us.v10/src/core2/file.c.o(.text);
        build/us.v10/src/core2/code_C4320.c.o(.text);
        build/us.v10/src/core2/code_C4F40.c.o(.text);
        build/us.v10/src/core2/code_C5440.c.o(.text);
        build/us.v10/src/core2/code_C5AF0.c.o(.text);
        build/us.v10/src/core2/code_C5CC0.c.o(.text);
        build/us.v10/src/core2/code_C5F00.c.o(.text);
        build/us.v10/src/core2/code_C61C0.c.o(.text);
        build/us.v10/src/core2/code_C62B0.c.o(.text);
        build/us.v10/src/core2/code_C76D0.c.o(.text);
        build/us.v10/src/core2/code_C7CC0.c.o(.text);
        build/us.v10/src/core2/code_C8230.c.o(.text);
        build/us.v10/src/core2/code_C8360.c.o(.text);
        build/us.v10/src/core2/code_C8490.c.o(.text);
        build/us.v10/src/core2/code_C8760.c.o(.text);
        build/us.v10/src/core2/code_C89C0.c.o(.text);
        build/us.v10/src/core2/code_C97F0.c.o(.text);
        build/us.v10/src/core2/code_C9E70.c.o(.text);
        build/us.v10/src/core2/code_C9F00.c.o(.text);
        build/us.v10/src/core2/code_CB050.c.o(.text);
        build/us.v10/src/core2/code_CB610.c.o(.text);
        build/us.v10/src/core2/code_CB8A0.c.o(.text);
        build/us.v10/src/core2/code_CBBF0.c.o(.text);
        build/us.v10/src/core2/code_CBD10.c.o(.text);
        build/us.v10/src/core2/code_CC1E0.c.o(.text);
        build/us.v10/src/core2/code_CD0A0.c.o(.text);
        build/us.v10/src/core2/code_CD3F0.c.o(.text);
        build/us.v10/src/core2/code_CD6E0.c.o(.text);
        build/us.v10/src/core2/code_CECD0.c.o(.text);
        build/us.v10/src/core2/code_CF090.c.o(.text);
        build/us.v10/src/core2/code_CF3E0.c.o(.text);
        build/us.v10/src/core2/code_CF5F0.c.o(.text);
        build/us.v10/src/core2/ch/clankerwhipcrack.c.o(.text);
        build/us.v10/src/core2/ch/code_CFA60.c.o(.text);
        build/us.v10/src/core2/ch/clucker.c.o(.text);
        build/us.v10/src/core2/code_D0CA0.c.o(.text);
        build/us.v10/src/core2/code_D2180.c.o(.text);
        build/us.v10/src/core2/ch/firefx.c.o(.text);
        build/us.v10/src/core2/ch/drips.c.o(.text);
        build/us.v10/src/core2/ch/icecube.c.o(.text);
        build/us.v10/src/core2/ch/ghost.c.o(.text);
        build/us.v10/src/core2/ch/flotsam.c.o(.text);
        build/us.v10/src/core2/code_D5D10.c.o(.text);
        build/us.v10/src/core2/code_D5FD0.c.o(.text);
        build/us.v10/src/core2/code_D6180.c.o(.text);
        build/us.v10/src/core2/code_D6600.c.o(.text);
        build/us.v10/src/core2/ch/termite.c.o(.text);
        build/us.v10/src/core2/ch/gravestone.c.o(.text);
        build/us.v10/src/core2/code_D89E0.c.o(.text);
        build/us.v10/src/core2/ch/whipcrack.c.o(.text);
        build/us.v10/src/core2/code_DA3A0.c.o(.text);
        build/us.v10/src/core2/code_DA760.c.o(.text);
        build/us.v10/src/core2/code_DAAA0.c.o(.text);
        build/us.v10/src/core2/code_DB010.c.o(.text);
        build/us.v10/src/core2/code_DC4B0.c.o(.text);
        core2_TEXT_END = .;
        core2_TEXT_SIZE = ABSOLUTE(core2_TEXT_END - core2_TEXT_START);
        core2_DATA_START = .;
        core2_data_DC600_bin = .;
        build/us.v10/bin/core2/data_DC600.bin.o(.data);
        core2_code_1550_c = .;
        build/us.v10/src/core2/code_1550.c.o(.data);
        core2_ba_anim_c = .;
        build/us.v10/src/core2/ba/anim.c.o(.data);
        core2_snackerctl_c = .;
        build/us.v10/src/core2/snackerctl.c.o(.data);
        core2_ba_marker_c = .;
        build/us.v10/src/core2/ba/marker.c.o(.data);
        core2_code_7060_c = .;
        build/us.v10/src/core2/code_7060.c.o(.data);
        core2_code_90E0_c = .;
        build/us.v10/src/core2/code_90E0.c.o(.data);
        core2_ba_model_c = .;
        build/us.v10/src/core2/ba/model.c.o(.data);
        core2_code_B850_c = .;
        build/us.v10/src/core2/code_B850.c.o(.data);
        core2_eggshatter_c = .;
        build/us.v10/src/core2/eggshatter.c.o(.data);
        core2_ba_falldamage_c = .;
        build/us.v10/src/core2/ba/falldamage.c.o(.data);
        core2_code_E910_c = .;
        build/us.v10/src/core2/code_E910.c.o(.data);
        core2_ba_physics_c = .;
        build/us.v10/src/core2/ba/physics.c.o(.data);
        core2_code_117D0_c = .;
        build/us.v10/src/core2/code_117D0.c.o(.data);
        core2_code_126C0_c = .;
        build/us.v10/src/core2/code_126C0.c.o(.data);
        core2_code_12F30_c = .;
        build/us.v10/src/core2/code_12F30.c.o(.data);
        core2_code_14420_c = .;
        build/us.v10/src/core2/code_14420.c.o(.data);
        core2_bs_ant_c = .;
        build/us.v10/src/core2/bs/ant.c.o(.data);
        core2_bs_bbuster_c = .;
        build/us.v10/src/core2/bs/bbuster.c.o(.data);
        core2_bs_beeFly_c = .;
        build/us.v10/src/core2/bs/beeFly.c.o(.data);
        core2_bs_beeMain_c = .;
        build/us.v10/src/core2/bs/beeMain.c.o(.data);
        core2_bs_bFlap_c = .;
        build/us.v10/src/core2/bs/bFlap.c.o(.data);
        core2_bs_bFlip_c = .;
        build/us.v10/src/core2/bs/bFlip.c.o(.data);
        core2_bs_bLongLeg_c = .;
        build/us.v10/src/core2/bs/bLongLeg.c.o(.data);
        core2_bs_bPeck_c = .;
        build/us.v10/src/core2/bs/bPeck.c.o(.data);
        core2_bs_bShock_c = .;
        build/us.v10/src/core2/bs/bShock.c.o(.data);
        core2_data_DDAF0_bin = .;
        build/us.v10/bin/core2/data_DDAF0.bin.o(.data);
        core2_bs_bTrot_c = .;
        build/us.v10/src/core2/bs/bTrot.c.o(.data);
        core2_bs_bWhirl_c = .;
        build/us.v10/src/core2/bs/bWhirl.c.o(.data);
        core2_bs_carry_c = .;
        build/us.v10/src/core2/bs/carry.c.o(.data);
        core2_bs_croc_c = .;
        build/us.v10/src/core2/bs/croc.c.o(.data);
        core2_bs_drone_c = .;
        build/us.v10/src/core2/bs/drone.c.o(.data);
        core2_bs_dronexform_c = .;
        build/us.v10/src/core2/bs/dronexform.c.o(.data);
        core2_bs_jump_c = .;
        build/us.v10/src/core2/bs/jump.c.o(.data);
        core2_bs_pumpkin_c = .;
        build/us.v10/src/core2/bs/pumpkin.c.o(.data);
        core2_bs_stand_c = .;
        build/us.v10/src/core2/bs/stand.c.o(.data);
        core2_bs_swim_c = .;
        build/us.v10/src/core2/bs/swim.c.o(.data);
        core2_bs_walk_c = .;
        build/us.v10/src/core2/bs/walk.c.o(.data);
        core2_bs_walrus_c = .;
        build/us.v10/src/core2/bs/walrus.c.o(.data);
        core2_code_33F90_c = .;
        build/us.v10/src/core2/code_33F90.c.o(.data);
        core2_code_34310_c = .;
        build/us.v10/src/core2/code_34310.c.o(.data);
        core2_code_34790_c = .;
        build/us.v10/src/core2/code_34790.c.o(.data);
        core2_code_35520_c = .;
        build/us.v10/src/core2/code_35520.c.o(.data);
        core2_nc_dynamicCamera_c = .;
        build/us.v10/src/core2/nc/dynamicCamera.c.o(.data);
        core2_code_37E50_c = .;
        build/us.v10/src/core2/code_37E50.c.o(.data);
        core2_nc_dynamicCamD_c = .;
        build/us.v10/src/core2/nc/dynamicCamD.c.o(.data);
        core2_nc_dynamicCamA_c = .;
        build/us.v10/src/core2/nc/dynamicCamA.c.o(.data);
        core2_spawnqueue_c = .;
        build/us.v10/src/core2/spawnqueue.c.o(.data);
        core2_ch_gameSelect_c = .;
        build/us.v10/src/core2/ch/gameSelect.c.o(.data);
        core2_code_3EAD0_c = .;
        build/us.v10/src/core2/code_3EAD0.c.o(.data);
        core2_code_3EC30_c = .;
        build/us.v10/src/core2/code_3EC30.c.o(.data);
        core2_ch_bubble_c = .;
        build/us.v10/src/core2/ch/bubble.c.o(.data);
        core2_ch_bigbutt_c = .;
        build/us.v10/src/core2/ch/bigbutt.c.o(.data);
        core2_code_400F0_c = .;
        build/us.v10/src/core2/code_400F0.c.o(.data);
        core2_ch_jiggy_c = .;
        build/us.v10/src/core2/ch/jiggy.c.o(.data);
        core2_ch_jigsawdance_c = .;
        build/us.v10/src/core2/ch/jigsawdance.c.o(.data);
        core2_code_41460_c = .;
        build/us.v10/src/core2/code_41460.c.o(.data);
        core2_code_41F30_c = .;
        build/us.v10/src/core2/code_41F30.c.o(.data);
        core2_code_41FB0_c = .;
        build/us.v10/src/core2/code_41FB0.c.o(.data);
        core2_ch_musicnote_c = .;
        build/us.v10/src/core2/ch/musicnote.c.o(.data);
        core2_code_42CB0_c = .;
        build/us.v10/src/core2/code_42CB0.c.o(.data);
        core2_code_43250_c = .;
        build/us.v10/src/core2/code_43250.c.o(.data);
        core2_ch_trainers_c = .;
        build/us.v10/src/core2/ch/trainers.c.o(.data);
        core2_code_43800_c = .;
        build/us.v10/src/core2/code_43800.c.o(.data);
        core2_code_43A40_c = .;
        build/us.v10/src/core2/code_43A40.c.o(.data);
        core2_mapspecificflags_c = .;
        build/us.v10/src/core2/mapspecificflags.c.o(.data);
        core2_ch_crab_c = .;
        build/us.v10/src/core2/ch/crab.c.o(.data);
        core2_code_45310_c = .;
        build/us.v10/src/core2/code_45310.c.o(.data);
        core2_ch_code_468E0_c = .;
        build/us.v10/src/core2/ch/code_468E0.c.o(.data);
        core2_ch_jinjo_c = .;
        build/us.v10/src/core2/ch/jinjo.c.o(.data);
        core2_ch_beehive_c = .;
        build/us.v10/src/core2/ch/beehive.c.o(.data);
        core2_code_47BD0_c = .;
        build/us.v10/src/core2/code_47BD0.c.o(.data);
        core2_ch_soundsource_c = .;
        build/us.v10/src/core2/ch/soundsource.c.o(.data);
        core2_ch_shrapnel_c = .;
        build/us.v10/src/core2/ch/shrapnel.c.o(.data);
        core2_ch_gloop_c = .;
        build/us.v10/src/core2/ch/gloop.c.o(.data);
        core2_code_4A6F0_c = .;
        build/us.v10/src/core2/code_4A6F0.c.o(.data);
        core2_code_4BD70_c = .;
        build/us.v10/src/core2/code_4BD70.c.o(.data);
        core2_code_4BE10_c = .;
        build/us.v10/src/core2/code_4BE10.c.o(.data);
        core2_code_4C020_c = .;
        build/us.v10/src/core2/code_4C020.c.o(.data);
        core2_ch_wadingboots_c = .;
        build/us.v10/src/core2/ch/wadingboots.c.o(.data);
        core2_ch_badShad_c = .;
        build/us.v10/src/core2/ch/badShad.c.o(.data);
        core2_code_50490_c = .;
        build/us.v10/src/core2/code_50490.c.o(.data);
        core2_ch_climbBase_c = .;
        build/us.v10/src/core2/ch/climbBase.c.o(.data);
        core2_code_509D0_c = .;
        build/us.v10/src/core2/code_509D0.c.o(.data);
        core2_code_517A0_c = .;
        build/us.v10/src/core2/code_517A0.c.o(.data);
        core2_code_51950_c = .;
        build/us.v10/src/core2/code_51950.c.o(.data);
        core2_ch_collectible_c = .;
        build/us.v10/src/core2/ch/collectible.c.o(.data);
        core2_ch_mole_c = .;
        build/us.v10/src/core2/ch/mole.c.o(.data);
        core2_ch_molehill_c = .;
        build/us.v10/src/core2/ch/molehill.c.o(.data);
        core2_code_53A10_c = .;
        build/us.v10/src/core2/code_53A10.c.o(.data);
        core2_code_53C10_c = .;
        build/us.v10/src/core2/code_53C10.c.o(.data);
        core2_code_54D50_c = .;
        build/us.v10/src/core2/code_54D50.c.o(.data);
        core2_code_55180_c = .;
        build/us.v10/src/core2/code_55180.c.o(.data);
        core2_code_55390_c = .;
        build/us.v10/src/core2/code_55390.c.o(.data);
        core2_code_556C0_c = .;
        build/us.v10/src/core2/code_556C0.c.o(.data);
        core2_code_55850_c = .;
        build/us.v10/src/core2/code_55850.c.o(.data);
        core2_ch_overlaycopyright_c = .;
        build/us.v10/src/core2/ch/overlaycopyright.c.o(.data);
        core2_ch_overlaypressstart_c = .;
        build/us.v10/src/core2/ch/overlaypressstart.c.o(.data);
        core2_ch_overlaynocontroller_c = .;
        build/us.v10/src/core2/ch/overlaynocontroller.c.o(.data);
        core2_ch_bottlesbonus_c = .;
        build/us.v10/src/core2/ch/bottlesbonus.c.o(.data);
        core2_code_57C70_c = .;
        build/us.v10/src/core2/code_57C70.c.o(.data);
        core2_code_581D0_c = .;
        build/us.v10/src/core2/code_581D0.c.o(.data);
        core2_ch_bottlesbonuscursor_c = .;
        build/us.v10/src/core2/ch/bottlesbonuscursor.c.o(.data);
        core2_code_59780_c = .;
        build/us.v10/src/core2/code_59780.c.o(.data);
        core2_code_59A80_c = .;
        build/us.v10/src/core2/code_59A80.c.o(.data);
        core2_ch_snacker_c = .;
        build/us.v10/src/core2/ch/snacker.c.o(.data);
        core2_ch_snowman_c = .;
        build/us.v10/src/core2/ch/snowman.c.o(.data);
        core2_ch_snowball_c = .;
        build/us.v10/src/core2/ch/snowball.c.o(.data);
        core2_ch_snowmanhat_c = .;
        build/us.v10/src/core2/ch/snowmanhat.c.o(.data);
        core2_code_5C870_c = .;
        build/us.v10/src/core2/code_5C870.c.o(.data);
        core2_code_5DBC0_c = .;
        build/us.v10/src/core2/code_5DBC0.c.o(.data);
        core2_code_66D90_c = .;
        build/us.v10/src/core2/code_66D90.c.o(.data);
        core2_code_66FB0_c = .;
        build/us.v10/src/core2/code_66FB0.c.o(.data);
        core2_gc_bound_c = .;
        build/us.v10/src/core2/gc/bound.c.o(.data);
        core2_code_67650_c = .;
        build/us.v10/src/core2/code_67650.c.o(.data);
        core2_particle_c = .;
        build/us.v10/src/core2/particle.c.o(.data);
        core2_code_6A4B0_c = .;
        build/us.v10/src/core2/code_6A4B0.c.o(.data);
        core2_code_6AEF0_c = .;
        build/us.v10/src/core2/code_6AEF0.c.o(.data);
        core2_code_6B030_c = .;
        build/us.v10/src/core2/code_6B030.c.o(.data);
        core2_fx_ripple_c = .;
        build/us.v10/src/core2/fx/ripple.c.o(.data);
        core2_fx_sparkle_c = .;
        build/us.v10/src/core2/fx/sparkle.c.o(.data);
        core2_code_6CD20_c = .;
        build/us.v10/src/core2/code_6CD20.c.o(.data);
        core2_code_6D030_c = .;
        build/us.v10/src/core2/code_6D030.c.o(.data);
        core2_code_6D270_c = .;
        build/us.v10/src/core2/code_6D270.c.o(.data);
        core2_code_6D490_c = .;
        build/us.v10/src/core2/code_6D490.c.o(.data);
        core2_code_6DA30_c = .;
        build/us.v10/src/core2/code_6DA30.c.o(.data);
        core2_code_72060_c = .;
        build/us.v10/src/core2/code_72060.c.o(.data);
        core2_code_73640_c = .;
        build/us.v10/src/core2/code_73640.c.o(.data);
        core2_code_74090_c = .;
        build/us.v10/src/core2/code_74090.c.o(.data);
        core2_code_74290_c = .;
        build/us.v10/src/core2/code_74290.c.o(.data);
        core2_code_74420_c = .;
        build/us.v10/src/core2/code_74420.c.o(.data);
        core2_code_74910_c = .;
        build/us.v10/src/core2/code_74910.c.o(.data);
        core2_code_74ED0_c = .;
        build/us.v10/src/core2/code_74ED0.c.o(.data);
        core2_code_75480_c = .;
        build/us.v10/src/core2/code_75480.c.o(.data);
        core2_code_75930_c = .;
        build/us.v10/src/core2/code_75930.c.o(.data);
        core2_code_75E90_c = .;
        build/us.v10/src/core2/code_75E90.c.o(.data);
        core2_fx_common2score_c = .;
        build/us.v10/src/core2/fx/common2score.c.o(.data);
        core2_fx_honeycarrierscore_c = .;
        build/us.v10/src/core2/fx/honeycarrierscore.c.o(.data);
        core2_fx_jinjoscore_c = .;
        build/us.v10/src/core2/fx/jinjoscore.c.o(.data);
        core2_fx_lifescore_c = .;
        build/us.v10/src/core2/fx/lifescore.c.o(.data);
        core2_fx_common3score_c = .;
        build/us.v10/src/core2/fx/common3score.c.o(.data);
        core2_fx_healthscore_c = .;
        build/us.v10/src/core2/fx/healthscore.c.o(.data);
        core2_fx_airscore_c = .;
        build/us.v10/src/core2/fx/airscore.c.o(.data);
        core2_code_7AF80_c = .;
        build/us.v10/src/core2/code_7AF80.c.o(.data);
        core2_mapModel_c = .;
        build/us.v10/src/core2/mapModel.c.o(.data);
        core2_code_83340_c = .;
        build/us.v10/src/core2/code_83340.c.o(.data);
        core2_gc_section_c = .;
        build/us.v10/src/core2/gc/section.c.o(.data);
        core2_gc_sky_c = .;
        build/us.v10/src/core2/gc/sky.c.o(.data);
        core2_gc_transition_c = .;
        build/us.v10/src/core2/gc/transition.c.o(.data);
        core2_code_851D0_c = .;
        build/us.v10/src/core2/code_851D0.c.o(.data);
        core2_gc_dialog_c = .;
        build/us.v10/src/core2/gc/dialog.c.o(.data);
        core2_gc_pauseMenu_c = .;
        build/us.v10/src/core2/gc/pauseMenu.c.o(.data);
        core2_code_8DC20_c = .;
        build/us.v10/src/core2/code_8DC20.c.o(.data);
        core2_gc_zoombox_c = .;
        build/us.v10/src/core2/gc/zoombox.c.o(.data);
        core2_code_91E10_c = .;
        build/us.v10/src/core2/code_91E10.c.o(.data);
        core2_code_935F0_c = .;
        build/us.v10/src/core2/code_935F0.c.o(.data);
        core2_gc_parade_c = .;
        build/us.v10/src/core2/gc/parade.c.o(.data);
        core2_code_94A20_c = .;
        build/us.v10/src/core2/code_94A20.c.o(.data);
        core2_code_956B0_c = .;
        build/us.v10/src/core2/code_956B0.c.o(.data);
        core2_code_98CB0_c = .;
        build/us.v10/src/core2/code_98CB0.c.o(.data);
        core2_code_9B180_c = .;
        build/us.v10/src/core2/code_9B180.c.o(.data);
        core2_code_9B650_c = .;
        build/us.v10/src/core2/code_9B650.c.o(.data);
        core2_code_9B990_c = .;
        build/us.v10/src/core2/code_9B990.c.o(.data);
        core2_code_9D640_c = .;
        build/us.v10/src/core2/code_9D640.c.o(.data);
        core2_code_9E370_c = .;
        build/us.v10/src/core2/code_9E370.c.o(.data);
        core2_code_A4D00_c = .;
        build/us.v10/src/core2/code_A4D00.c.o(.data);
        core2_code_A5BC0_c = .;
        build/us.v10/src/core2/code_A5BC0.c.o(.data);
        core2_code_A5BC0_c = .;
        build/us.v10/src/core2/code_A5BC0.c.o(.data);
        core2_code_ABC00_c = .;
        build/us.v10/src/core2/code_ABC00.c.o(.data);
        core2_code_AC520_c = .;
        build/us.v10/src/core2/code_AC520.c.o(.data);
        core2_code_AD110_c = .;
        build/us.v10/src/core2/code_AD110.c.o(.data);
        core2_code_AD5B0_c = .;
        build/us.v10/src/core2/code_AD5B0.c.o(.data);
        core2_code_AEDA0_c = .;
        build/us.v10/src/core2/code_AEDA0.c.o(.data);
        core2_modelRender_c = .;
        build/us.v10/src/core2/modelRender.c.o(.data);
        core2_code_B3A80_c = .;
        build/us.v10/src/core2/code_B3A80.c.o(.data);
        core2_code_B5040_c = .;
        build/us.v10/src/core2/code_B5040.c.o(.data);
        core2_code_B62B0_c = .;
        build/us.v10/src/core2/code_B62B0.c.o(.data);
        core2_code_B6CE0_c = .;
        build/us.v10/src/core2/code_B6CE0.c.o(.data);
        core2_code_B6EA0_c = .;
        build/us.v10/src/core2/code_B6EA0.c.o(.data);
        core2_code_B7F40_c = .;
        build/us.v10/src/core2/code_B7F40.c.o(.data);
        core2_code_B9770_c = .;
        build/us.v10/src/core2/code_B9770.c.o(.data);
        core2_code_BD100_c = .;
        build/us.v10/src/core2/code_BD100.c.o(.data);
        core2_code_BE2C0_c = .;
        build/us.v10/src/core2/code_BE2C0.c.o(.data);
        core2_data_EAF40_bin = .;
        build/us.v10/bin/core2/data_EAF40.bin.o(.data);
        core2_code_C2F30_c = .;
        build/us.v10/src/core2/code_C2F30.c.o(.data);
        core2_code_C4320_c = .;
        build/us.v10/src/core2/code_C4320.c.o(.data);
        core2_code_C4F40_c = .;
        build/us.v10/src/core2/code_C4F40.c.o(.data);
        core2_code_C5440_c = .;
        build/us.v10/src/core2/code_C5440.c.o(.data);
        core2_code_C8760_c = .;
        build/us.v10/src/core2/code_C8760.c.o(.data);
        core2_code_C97F0_c = .;
        build/us.v10/src/core2/code_C97F0.c.o(.data);
        core2_code_C9F00_c = .;
        build/us.v10/src/core2/code_C9F00.c.o(.data);
        core2_code_CBD10_c = .;
        build/us.v10/src/core2/code_CBD10.c.o(.data);
        core2_code_CC1E0_c = .;
        build/us.v10/src/core2/code_CC1E0.c.o(.data);
        core2_code_CD6E0_c = .;
        build/us.v10/src/core2/code_CD6E0.c.o(.data);
        core2_code_CECD0_c = .;
        build/us.v10/src/core2/code_CECD0.c.o(.data);
        core2_code_CF090_c = .;
        build/us.v10/src/core2/code_CF090.c.o(.data);
        core2_code_CF3E0_c = .;
        build/us.v10/src/core2/code_CF3E0.c.o(.data);
        core2_code_CF5F0_c = .;
        build/us.v10/src/core2/code_CF5F0.c.o(.data);
        core2_ch_clankerwhipcrack_c = .;
        build/us.v10/src/core2/ch/clankerwhipcrack.c.o(.data);
        core2_ch_code_CFA60_c = .;
        build/us.v10/src/core2/ch/code_CFA60.c.o(.data);
        core2_ch_clucker_c = .;
        build/us.v10/src/core2/ch/clucker.c.o(.data);
        core2_code_D0CA0_c = .;
        build/us.v10/src/core2/code_D0CA0.c.o(.data);
        core2_code_D2180_c = .;
        build/us.v10/src/core2/code_D2180.c.o(.data);
        core2_ch_firefx_c = .;
        build/us.v10/src/core2/ch/firefx.c.o(.data);
        core2_ch_drips_c = .;
        build/us.v10/src/core2/ch/drips.c.o(.data);
        core2_ch_icecube_c = .;
        build/us.v10/src/core2/ch/icecube.c.o(.data);
        core2_ch_ghost_c = .;
        build/us.v10/src/core2/ch/ghost.c.o(.data);
        core2_ch_flotsam_c = .;
        build/us.v10/src/core2/ch/flotsam.c.o(.data);
        core2_code_D5D10_c = .;
        build/us.v10/src/core2/code_D5D10.c.o(.data);
        core2_code_D5FD0_c = .;
        build/us.v10/src/core2/code_D5FD0.c.o(.data);
        core2_code_D6180_c = .;
        build/us.v10/src/core2/code_D6180.c.o(.data);
        core2_code_D6600_c = .;
        build/us.v10/src/core2/code_D6600.c.o(.data);
        core2_ch_termite_c = .;
        build/us.v10/src/core2/ch/termite.c.o(.data);
        core2_ch_gravestone_c = .;
        build/us.v10/src/core2/ch/gravestone.c.o(.data);
        core2_code_D89E0_c = .;
        build/us.v10/src/core2/code_D89E0.c.o(.data);
        core2_ch_whipcrack_c = .;
        build/us.v10/src/core2/ch/whipcrack.c.o(.data);
        core2_code_DA3A0_c = .;
        build/us.v10/src/core2/code_DA3A0.c.o(.data);
        core2_code_DA760_c = .;
        build/us.v10/src/core2/code_DA760.c.o(.data);
        core2_code_DAAA0_c = .;
        build/us.v10/src/core2/code_DAAA0.c.o(.data);
        core2_code_DB010_c = .;
        build/us.v10/src/core2/code_DB010.c.o(.data);
        core2_code_DC4B0_c = .;
        build/us.v10/src/core2/code_DC4B0.c.o(.data);
        core2_DATA_END = .;
        core2_DATA_SIZE = ABSOLUTE(core2_DATA_END - core2_DATA_START);
        core2_RODATA_START = .;
        build/us.v10/src/core2/animctrl.c.o(.rodata);
        build/us.v10/src/core2/anim/sprite.c.o(.rodata);
        build/us.v10/src/core2/code_1930.c.o(.rodata);
        build/us.v10/src/core2/ba/anim.c.o(.rodata);
        build/us.v10/src/core2/snackerctl.c.o(.rodata);
        build/us.v10/src/core2/code_39D0.c.o(.rodata);
        build/us.v10/src/core2/ba/marker.c.o(.rodata);
        build/us.v10/src/core2/code_6B30.c.o(.rodata);
        build/us.v10/src/core2/code_7060.c.o(.rodata);
        build/us.v10/src/core2/code_9450.c.o(.rodata);
        build/us.v10/src/core2/code_9900.c.o(.rodata);
        build/us.v10/src/core2/code_9BD0.c.o(.rodata);
        build/us.v10/src/core2/ba/model.c.o(.rodata);
        build/us.v10/src/core2/ba/drone.c.o(.rodata);
        build/us.v10/src/core2/code_B850.c.o(.rodata);
        build/us.v10/src/core2/code_BD20.c.o(.rodata);
        build/us.v10/src/core2/ba/falldamage.c.o(.rodata);
        build/us.v10/src/core2/code_C4B0.c.o(.rodata);
        build/us.v10/src/core2/code_D9B0.c.o(.rodata);
        build/us.v10/src/core2/abilityprogress.c.o(.rodata);
        build/us.v10/src/core2/code_EF50.c.o(.rodata);
        build/us.v10/src/core2/ba/physics.c.o(.rodata);
        build/us.v10/src/core2/code_10CD0.c.o(.rodata);
        build/us.v10/src/core2/pitch.c.o(.rodata);
        build/us.v10/src/core2/code_11040.c.o(.rodata);
        build/us.v10/src/core2/climb.c.o(.rodata);
        build/us.v10/src/core2/code_11660.c.o(.rodata);
        build/us.v10/src/core2/code_11870.c.o(.rodata);
        build/us.v10/src/core2/roll.c.o(.rodata);
        build/us.v10/src/core2/yaw.c.o(.rodata);
        build/us.v10/src/core2/code_12360.c.o(.rodata);
        build/us.v10/src/core2/code_126C0.c.o(.rodata);
        build/us.v10/src/core2/code_12F30.c.o(.rodata);
        build/us.v10/src/core2/code_13FC0.c.o(.rodata);
        build/us.v10/src/core2/code_14420.c.o(.rodata);
        build/us.v10/src/core2/code_16010.c.o(.rodata);
        build/us.v10/src/core2/code_16C60.c.o(.rodata);
        build/us.v10/src/core2/bs/ant.c.o(.rodata);
        build/us.v10/src/core2/bs/bBarge.c.o(.rodata);
        build/us.v10/src/core2/bs/bbuster.c.o(.rodata);
        build/us.v10/src/core2/bs/beeFly.c.o(.rodata);
        build/us.v10/src/core2/bs/beeMain.c.o(.rodata);
        build/us.v10/src/core2/bs/bEggAss.c.o(.rodata);
        build/us.v10/src/core2/bs/bEggHead.c.o(.rodata);
        build/us.v10/src/core2/bs/bFlap.c.o(.rodata);
        build/us.v10/src/core2/bs/bFlip.c.o(.rodata);
        build/us.v10/src/core2/bs/bFly.c.o(.rodata);
        build/us.v10/src/core2/bs/bLongLeg.c.o(.rodata);
        build/us.v10/src/core2/bs/bPeck.c.o(.rodata);
        build/us.v10/src/core2/bs/bShock.c.o(.rodata);
        build/us.v10/src/core2/bs/bSwim.c.o(.rodata);
        build/us.v10/src/core2/bs/bTrot.c.o(.rodata);
        build/us.v10/src/core2/bs/bWhirl.c.o(.rodata);
        build/us.v10/src/core2/bs/carry.c.o(.rodata);
        build/us.v10/src/core2/bs/claw.c.o(.rodata);
        build/us.v10/src/core2/bs/climb.c.o(.rodata);
        build/us.v10/src/core2/bs/croc.c.o(.rodata);
        build/us.v10/src/core2/bs/crouch.c.o(.rodata);
        build/us.v10/src/core2/bs/die.c.o(.rodata);
        build/us.v10/src/core2/bs/droneenter.c.o(.rodata);
        build/us.v10/src/core2/bs/dronegoto.c.o(.rodata);
        build/us.v10/src/core2/bs/dronelook.c.o(.rodata);
        build/us.v10/src/core2/bs/dronevanish.c.o(.rodata);
        build/us.v10/src/core2/bs/dronexform.c.o(.rodata);
        build/us.v10/src/core2/bs/jig.c.o(.rodata);
        build/us.v10/src/core2/bs/jump.c.o(.rodata);
        build/us.v10/src/core2/bs/ow.c.o(.rodata);
        build/us.v10/src/core2/bs/pumpkin.c.o(.rodata);
        build/us.v10/src/core2/bs/rebound.c.o(.rodata);
        build/us.v10/src/core2/bs/rest.c.o(.rodata);
        build/us.v10/src/core2/bs/slide.c.o(.rodata);
        build/us.v10/src/core2/bs/stand.c.o(.rodata);
        build/us.v10/src/core2/bs/swim.c.o(.rodata);
        build/us.v10/src/core2/bs/surf.c.o(.rodata);
        build/us.v10/src/core2/bs/talk.c.o(.rodata);
        build/us.v10/src/core2/bs/timeout.c.o(.rodata);
        build/us.v10/src/core2/bs/throw.c.o(.rodata);
        build/us.v10/src/core2/bs/turn.c.o(.rodata);
        build/us.v10/src/core2/bs/twirl.c.o(.rodata);
        build/us.v10/src/core2/bs/walk.c.o(.rodata);
        build/us.v10/src/core2/bs/walrus.c.o(.rodata);
        build/us.v10/src/core2/bs/washy.c.o(.rodata);
        build/us.v10/src/core2/nc/cameranodelist.c.o(.rodata);
        build/us.v10/src/core2/code_33F90.c.o(.rodata);
        build/us.v10/src/core2/code_34310.c.o(.rodata);
        build/us.v10/src/core2/code_34790.c.o(.rodata);
        build/us.v10/src/core2/nc/dynamicCamera.c.o(.rodata);
        build/us.v10/src/core2/code_37E50.c.o(.rodata);
        build/us.v10/src/core2/nc/dynamicCam10.c.o(.rodata);
        build/us.v10/src/core2/nc/dynamicCamD.c.o(.rodata);
        build/us.v10/src/core2/nc/dynamicCam5.c.o(.rodata);
        build/us.v10/src/core2/nc/dynamicCam4.c.o(.rodata);
        build/us.v10/src/core2/nc/dynamicCamC.c.o(.rodata);
        build/us.v10/src/core2/code_F8EAF0.c.o(.rodata);
        build/us.v10/src/core2/nc/dynamicCamB.c.o(.rodata);
        build/us.v10/src/core2/nc/dynamicCam13.c.o(.rodata);
        build/us.v10/src/core2/nc/dynamicCam9.c.o(.rodata);
        build/us.v10/src/core2/nc/dynamicCam12.c.o(.rodata);
        build/us.v10/src/core2/nc/dynamicCam3.c.o(.rodata);
        build/us.v10/src/core2/nc/dynamicCamA.c.o(.rodata);
        build/us.v10/src/core2/spawnqueue.c.o(.rodata);
        build/us.v10/src/core2/ch/gameSelect.c.o(.rodata);
        build/us.v10/src/core2/ch/bubble.c.o(.rodata);
        build/us.v10/src/core2/ch/bigbutt.c.o(.rodata);
        build/us.v10/src/core2/code_400F0.c.o(.rodata);
        build/us.v10/src/core2/ch/jiggy.c.o(.rodata);
        build/us.v10/src/core2/ch/jigsawdance.c.o(.rodata);
        build/us.v10/src/core2/code_41460.c.o(.rodata);
        build/us.v10/src/core2/code_41FB0.c.o(.rodata);
        build/us.v10/src/core2/ch/musicnote.c.o(.rodata);
        build/us.v10/src/core2/code_42CB0.c.o(.rodata);
        build/us.v10/src/core2/ch/trainers.c.o(.rodata);
        build/us.v10/src/core2/code_43800.c.o(.rodata);
        build/us.v10/src/core2/ch/crab.c.o(.rodata);
        build/us.v10/src/core2/code_45310.c.o(.rodata);
        build/us.v10/src/core2/ch/jinjo.c.o(.rodata);
        build/us.v10/src/core2/ch/beehive.c.o(.rodata);
        build/us.v10/src/core2/code_47BD0.c.o(.rodata);
        build/us.v10/src/core2/ch/shrapnel.c.o(.rodata);
        build/us.v10/src/core2/ch/gloop.c.o(.rodata);
        build/us.v10/src/core2/code_4A6F0.c.o(.rodata);
        build/us.v10/src/core2/code_4C020.c.o(.rodata);
        build/us.v10/src/core2/ch/badShad.c.o(.rodata);
        build/us.v10/src/core2/code_50490.c.o(.rodata);
        build/us.v10/src/core2/code_509D0.c.o(.rodata);
        build/us.v10/src/core2/code_517A0.c.o(.rodata);
        build/us.v10/src/core2/code_51950.c.o(.rodata);
        build/us.v10/src/core2/ch/mole.c.o(.rodata);
        build/us.v10/src/core2/code_53C10.c.o(.rodata);
        build/us.v10/src/core2/code_54D50.c.o(.rodata);
        build/us.v10/src/core2/code_55180.c.o(.rodata);
        build/us.v10/src/core2/code_55390.c.o(.rodata);
        build/us.v10/src/core2/ch/overlaypressstart.c.o(.rodata);
        build/us.v10/src/core2/ch/overlaynocontroller.c.o(.rodata);
        build/us.v10/src/core2/ch/bottlesbonus.c.o(.rodata);
        build/us.v10/src/core2/code_57C70.c.o(.rodata);
        build/us.v10/src/core2/code_581D0.c.o(.rodata);
        build/us.v10/src/core2/ch/bottlesbonuscursor.c.o(.rodata);
        build/us.v10/src/core2/code_599E0.c.o(.rodata);
        build/us.v10/src/core2/code_59A80.c.o(.rodata);
        build/us.v10/src/core2/ch/snacker.c.o(.rodata);
        build/us.v10/src/core2/ch/snowman.c.o(.rodata);
        build/us.v10/src/core2/ch/snowball.c.o(.rodata);
        build/us.v10/src/core2/code_5C240.c.o(.rodata);
        build/us.v10/src/core2/code_5C870.c.o(.rodata);
        build/us.v10/src/core2/code_5FD90.c.o(.rodata);
        build/us.v10/src/core2/code_66FB0.c.o(.rodata);
        build/us.v10/src/core2/code_67650.c.o(.rodata);
        build/us.v10/src/core2/particle.c.o(.rodata);
        build/us.v10/src/core2/code_6A4B0.c.o(.rodata);
        build/us.v10/src/core2/code_6B030.c.o(.rodata);
        build/us.v10/src/core2/fx/ripple.c.o(.rodata);
        build/us.v10/src/core2/fx/sparkle.c.o(.rodata);
        build/us.v10/src/core2/code_6CEC0.c.o(.rodata);
        build/us.v10/src/core2/code_6D030.c.o(.rodata);
        build/us.v10/src/core2/code_6D270.c.o(.rodata);
        build/us.v10/src/core2/code_6DA30.c.o(.rodata);
        build/us.v10/src/core2/code_70F20.c.o(.rodata);
        build/us.v10/src/core2/code_71820.c.o(.rodata);
        build/us.v10/src/core2/code_72060.c.o(.rodata);
        build/us.v10/src/core2/code_73640.c.o(.rodata);
        build/us.v10/src/core2/code_74420.c.o(.rodata);
        build/us.v10/src/core2/fx/common2score.c.o(.rodata);
        build/us.v10/src/core2/fx/honeycarrierscore.c.o(.rodata);
        build/us.v10/src/core2/fx/jinjoscore.c.o(.rodata);
        build/us.v10/src/core2/fx/jinjoscore.c.o(.rodata);
        build/us.v10/src/core2/fx/common3score.c.o(.rodata);
        build/us.v10/src/core2/fx/healthscore.c.o(.rodata);
        build/us.v10/src/core2/fx/airscore.c.o(.rodata);
        build/us.v10/src/core2/code_7AF80.c.o(.rodata);
        build/us.v10/src/core2/mapModel.c.o(.rodata);
        build/us.v10/src/core2/code_83340.c.o(.rodata);
        build/us.v10/src/core2/gc/section.c.o(.rodata);
        build/us.v10/src/core2/gc/sky.c.o(.rodata);
        build/us.v10/src/core2/gc/transition.c.o(.rodata);
        build/us.v10/src/core2/code_85800.c.o(.rodata);
        build/us.v10/src/core2/gc/dialog.c.o(.rodata);
        build/us.v10/src/core2/gc/pauseMenu.c.o(.rodata);
        build/us.v10/src/core2/gc/zoombox.c.o(.rodata);
        build/us.v10/src/core2/code_91E10.c.o(.rodata);
        build/us.v10/src/core2/code_935F0.c.o(.rodata);
        build/us.v10/src/core2/gc/parade.c.o(.rodata);
        build/us.v10/src/core2/code_94A20.c.o(.rodata);
        build/us.v10/src/core2/code_956B0.c.o(.rodata);
        build/us.v10/src/core2/code_9A9D0.c.o(.rodata);
        build/us.v10/src/core2/code_9B180.c.o(.rodata);
        build/us.v10/src/core2/code_9C170.c.o(.rodata);
        build/us.v10/src/core2/code_9E370.c.o(.rodata);
        build/us.v10/src/core2/code_A4D00.c.o(.rodata);
        build/us.v10/src/core2/code_A5BC0.c.o(.rodata);
        build/us.v10/src/core2/code_AD110.c.o(.rodata);
        build/us.v10/src/core2/skeletalanim.c.o(.rodata);
        build/us.v10/src/core2/code_AEDA0.c.o(.rodata);
        build/us.v10/src/core2/modelRender.c.o(.rodata);
        build/us.v10/src/core2/code_B3A80.c.o(.rodata);
        build/us.v10/src/core2/string.c.o(.rodata);
        build/us.v10/src/core2/code_B6C60.c.o(.rodata);
        build/us.v10/src/core2/code_B6CE0.c.o(.rodata);
        build/us.v10/src/core2/code_B9090.c.o(.rodata);
        build/us.v10/src/core2/code_B9770.c.o(.rodata);
        build/us.v10/src/core2/code_BD100.c.o(.rodata);
        build/us.v10/src/core2/code_BDCC0.c.o(.rodata);
        build/us.v10/src/core2/code_BE2C0.c.o(.rodata);
        build/us.v10/src/core2/code_BEF20.c.o(.rodata);
        build/us.v10/src/core2/code_C0E60.c.o(.rodata);
        build/us.v10/src/core2/rand.c.o(.rodata);
        build/us.v10/src/core2/code_C3A40.c.o(.rodata);
        build/us.v10/src/core2/code_C4320.c.o(.rodata);
        build/us.v10/src/core2/code_C5AF0.c.o(.rodata);
        build/us.v10/src/core2/code_C5CC0.c.o(.rodata);
        build/us.v10/src/core2/code_C5F00.c.o(.rodata);
        build/us.v10/src/core2/code_C62B0.c.o(.rodata);
        build/us.v10/src/core2/code_C76D0.c.o(.rodata);
        build/us.v10/src/core2/code_C7CC0.c.o(.rodata);
        build/us.v10/src/core2/code_C8230.c.o(.rodata);
        build/us.v10/src/core2/code_C8360.c.o(.rodata);
        build/us.v10/src/core2/code_C8490.c.o(.rodata);
        build/us.v10/src/core2/code_C8760.c.o(.rodata);
        build/us.v10/src/core2/code_C89C0.c.o(.rodata);
        build/us.v10/src/core2/code_C97F0.c.o(.rodata);
        build/us.v10/src/core2/code_C9F00.c.o(.rodata);
        build/us.v10/src/core2/code_CB050.c.o(.rodata);
        build/us.v10/src/core2/code_CB610.c.o(.rodata);
        build/us.v10/src/core2/code_CBD10.c.o(.rodata);
        build/us.v10/src/core2/code_CC1E0.c.o(.rodata);
        build/us.v10/src/core2/code_CD0A0.c.o(.rodata);
        build/us.v10/src/core2/code_CD3F0.c.o(.rodata);
        build/us.v10/src/core2/code_CD6E0.c.o(.rodata);
        build/us.v10/src/core2/code_CECD0.c.o(.rodata);
        build/us.v10/src/core2/code_CF090.c.o(.rodata);
        build/us.v10/src/core2/ch/clankerwhipcrack.c.o(.rodata);
        build/us.v10/src/core2/ch/code_CFA60.c.o(.rodata);
        build/us.v10/src/core2/ch/clucker.c.o(.rodata);
        build/us.v10/src/core2/code_D0CA0.c.o(.rodata);
        build/us.v10/src/core2/code_D2180.c.o(.rodata);
        build/us.v10/src/core2/ch/firefx.c.o(.rodata);
        build/us.v10/src/core2/ch/drips.c.o(.rodata);
        build/us.v10/src/core2/ch/icecube.c.o(.rodata);
        build/us.v10/src/core2/ch/ghost.c.o(.rodata);
        build/us.v10/src/core2/ch/flotsam.c.o(.rodata);
        build/us.v10/src/core2/code_D5D10.c.o(.rodata);
        build/us.v10/src/core2/code_D6180.c.o(.rodata);
        build/us.v10/src/core2/code_D6600.c.o(.rodata);
        build/us.v10/src/core2/ch/termite.c.o(.rodata);
        build/us.v10/src/core2/ch/gravestone.c.o(.rodata);
        build/us.v10/src/core2/code_D89E0.c.o(.rodata);
        build/us.v10/src/core2/code_D89E0.c.o(.rodata);
        build/us.v10/src/core2/ch/whipcrack.c.o(.rodata);
        build/us.v10/src/core2/code_DA3A0.c.o(.rodata);
        build/us.v10/src/core2/code_DA760.c.o(.rodata);
        build/us.v10/src/core2/code_DB010.c.o(.rodata);
        build/us.v10/src/core2/code_2240.c.o(.rodata)
        build/us.v10/src/core2/code_8DA0.c.o(.rodata)
        build/us.v10/src/core2/code_A600.c.o(.rodata)
        build/us.v10/src/core2/code_A960.c.o(.rodata)
        build/us.v10/src/core2/eggshatter.c.o(.rodata)
        build/us.v10/src/core2/code_EE40.c.o(.rodata)
        build/us.v10/src/core2/code_13A00.c.o(.rodata)
        build/us.v10/src/core2/bs/bee.c.o(.rodata)
        build/us.v10/src/core2/bs/sled.c.o(.rodata)
        build/us.v10/src/core2/bs/splat.c.o(.rodata)
        build/us.v10/src/core2/code_33310.c.o(.rodata)
        build/us.v10/src/core2/code_336F0.c.o(.rodata)
        build/us.v10/src/core2/code_33C30.c.o(.rodata)
        build/us.v10/src/core2/code_379B0.c.o(.rodata)
        build/us.v10/src/core2/nc/randomCamera.c.o(.rodata)
        build/us.v10/src/core2/nc/dynamicCam11.c.o(.rodata)
        build/us.v10/src/core2/nc/dynamicCam8.c.o(.rodata)
        build/us.v10/src/core2/nc/dynamicCam1.c.o(.rodata)
        build/us.v10/src/core2/code_3B2C0.c.o(.rodata)
        build/us.v10/src/core2/nc/dynamicCamF.c.o(.rodata)
        build/us.v10/src/core2/nc/firstpersoncamera.c.o(.rodata)
        build/us.v10/src/core2/code_3EAD0.c.o(.rodata)
        build/us.v10/src/core2/code_3EC30.c.o(.rodata)
        build/us.v10/src/core2/code_41F30.c.o(.rodata)
        build/us.v10/src/core2/code_43250.c.o(.rodata)
        build/us.v10/src/core2/code_43A40.c.o(.rodata)
        build/us.v10/src/core2/ch/code_468E0.c.o(.rodata)
        build/us.v10/src/core2/ch/soundsource.c.o(.rodata)
        build/us.v10/src/core2/code_4BE10.c.o(.rodata)
        build/us.v10/src/core2/ch/wadingboots.c.o(.rodata)
        build/us.v10/src/core2/ch/collectible.c.o(.rodata)
        build/us.v10/src/core2/ch/molehill.c.o(.rodata)
        build/us.v10/src/core2/code_53A10.c.o(.rodata)
        build/us.v10/src/core2/code_55850.c.o(.rodata)
        build/us.v10/src/core2/code_59780.c.o(.rodata)
        build/us.v10/src/core2/ch/snowmanhat.c.o(.rodata)
        build/us.v10/src/core2/code_5DBC0.c.o(.rodata)
        build/us.v10/src/core2/code_637D0.c.o(.rodata)
        build/us.v10/src/core2/code_654C0.c.o(.rodata)
        build/us.v10/src/core2/code_66490.c.o(.rodata)
        build/us.v10/src/core2/code_66D90.c.o(.rodata)
        build/us.v10/src/core2/code_69F60.c.o(.rodata)
        build/us.v10/src/core2/code_6AEF0.c.o(.rodata)
        build/us.v10/src/core2/code_6CD20.c.o(.rodata)
        build/us.v10/src/core2/code_6D490.c.o(.rodata)
        build/us.v10/src/core2/code_72B10.c.o(.rodata)
        build/us.v10/src/core2/code_74290.c.o(.rodata)
        build/us.v10/src/core2/code_74910.c.o(.rodata)
        build/us.v10/src/core2/code_74ED0.c.o(.rodata)
        build/us.v10/src/core2/code_75480.c.o(.rodata)
        build/us.v10/src/core2/code_75930.c.o(.rodata)
        build/us.v10/src/core2/code_75E90.c.o(.rodata)
        build/us.v10/src/core2/fx/lifescore.c.o(.rodata)
        build/us.v10/src/core2/code_94780.c.o(.rodata)
        build/us.v10/src/core2/code_999A0.c.o(.rodata)
        build/us.v10/src/core2/timedfuncqueue.c.o(.rodata)
        build/us.v10/src/core2/code_ABC00.c.o(.rodata)
        build/us.v10/src/core2/code_AC520.c.o(.rodata)
        build/us.v10/src/core2/code_B3580.c.o(.rodata)
        build/us.v10/src/core2/code_B8860.c.o(.rodata)
        build/us.v10/src/core2/code_C0B80.c.o(.rodata)
        build/us.v10/src/core2/code_C0CF0.c.o(.rodata)
        build/us.v10/src/core2/code_C61C0.c.o(.rodata)
        build/us.v10/src/core2/code_D5FD0.c.o(.rodata)
        build/us.v10/src/core2/code_DAAA0.c.o(.rodata)
        build/us.v10/src/core2/code_DC4B0.c.o(.rodata)

        core2_RODATA_END = .;
        core2_RODATA_SIZE = ABSOLUTE(core2_RODATA_END - core2_RODATA_START);
    }
    core2_bss_VRAM = ADDR(.core2_bss);
    .core2_bss (NOLOAD) : SUBALIGN(16)
    {
        core2_BSS_START = .;
        build/us.v10/src/core2/anim/sprite.c.o(.bss);
        build/us.v10/src/core2/animcache.c.o(.bss);
        build/us.v10/src/core2/code_1550.c.o(.bss);
        build/us.v10/src/core2/code_1930.c.o(.bss);
        build/us.v10/src/core2/ba/anim.c.o(.bss);
        build/us.v10/src/core2/snackerctl.c.o(.bss);
        build/us.v10/src/core2/code_39D0.c.o(.bss);
        build/us.v10/src/core2/ba/marker.c.o(.bss);
        build/us.v10/src/core2/code_6B30.c.o(.bss);
        build/us.v10/src/core2/code_7060.c.o(.bss);
        build/us.v10/src/core2/code_8DA0.c.o(.bss);
        build/us.v10/src/core2/code_90E0.c.o(.bss);
        build/us.v10/src/core2/code_9290.c.o(.bss);
        build/us.v10/src/core2/code_9450.c.o(.bss);
        build/us.v10/src/core2/code_9900.c.o(.bss);
        build/us.v10/src/core2/code_9BD0.c.o(.bss);
        build/us.v10/src/core2/code_A600.c.o(.bss);
        build/us.v10/src/core2/statetimer.c.o(.bss);
        build/us.v10/src/core2/ba/model.c.o(.bss);
        build/us.v10/src/core2/ba/drone.c.o(.bss);
        build/us.v10/src/core2/eggshatter.c.o(.bss);
        build/us.v10/src/core2/code_BD20.c.o(.bss);
        build/us.v10/src/core2/ba/falldamage.c.o(.bss);
        build/us.v10/src/core2/code_C3F0.c.o(.bss);
        build/us.v10/src/core2/code_C4B0.c.o(.bss);
        build/us.v10/src/core2/ba/carry.c.o(.bss);
        build/us.v10/src/core2/code_D9B0.c.o(.bss);
        build/us.v10/src/core2/code_DF70.c.o(.bss);
        build/us.v10/src/core2/code_E410.c.o(.bss);
        build/us.v10/src/core2/abilityprogress.c.o(.bss);
        build/us.v10/src/core2/code_E910.c.o(.bss);
        build/us.v10/src/core2/code_EE40.c.o(.bss);
        build/us.v10/src/core2/code_EF50.c.o(.bss);
        build/us.v10/src/core2/ba/physics.c.o(.bss);
        build/us.v10/src/core2/code_10CD0.c.o(.bss);
        build/us.v10/src/core2/pitch.c.o(.bss);
        build/us.v10/src/core2/code_11040.c.o(.bss);
        build/us.v10/src/core2/climb.c.o(.bss);
        build/us.v10/src/core2/code_11460.c.o(.bss);
        build/us.v10/src/core2/code_11660.c.o(.bss);
        build/us.v10/src/core2/code_117D0.c.o(.bss);
        build/us.v10/src/core2/code_11870.c.o(.bss);
        build/us.v10/src/core2/roll.c.o(.bss);
        build/us.v10/src/core2/yaw.c.o(.bss);
        build/us.v10/src/core2/code_12360.c.o(.bss);
        build/us.v10/src/core2/code_126C0.c.o(.bss);
        build/us.v10/src/core2/code_12F30.c.o(.bss);
        build/us.v10/src/core2/bsList.c.o(.bss);
        build/us.v10/src/core2/code_13780.c.o(.bss);
        build/us.v10/src/core2/bsStoredState.c.o(.bss);
        build/us.v10/src/core2/code_13A00.c.o(.bss);
        build/us.v10/src/core2/code_13FC0.c.o(.bss);
        build/us.v10/src/core2/code_14420.c.o(.bss);
        build/us.v10/src/core2/code_15F20.c.o(.bss);
        build/us.v10/src/core2/code_16010.c.o(.bss);
        build/us.v10/src/core2/code_16C60.c.o(.bss);
        build/us.v10/src/core2/code_171F0.c.o(.bss);
        build/us.v10/src/core2/bs/ant.c.o(.bss);
        build/us.v10/src/core2/bs/bBarge.c.o(.bss);
        build/us.v10/src/core2/bs/bbuster.c.o(.bss);
        build/us.v10/src/core2/bs/beeFly.c.o(.bss);
        build/us.v10/src/core2/bs/beeMain.c.o(.bss);
        build/us.v10/src/core2/bs/bEggAss.c.o(.bss);
        build/us.v10/src/core2/bs/bEggHead.c.o(.bss);
        build/us.v10/src/core2/bs/bFlap.c.o(.bss);
        build/us.v10/src/core2/bs/bFlip.c.o(.bss);
        build/us.v10/src/core2/bs/bFly.c.o(.bss);
        build/us.v10/src/core2/bs/bLongLeg.c.o(.bss);
        build/us.v10/src/core2/bs/bPeck.c.o(.bss);
        build/us.v10/src/core2/bs/bShock.c.o(.bss);
        build/us.v10/src/core2/bs/bSwim.c.o(.bss);
        build/us.v10/src/core2/bs/bTrot.c.o(.bss);
        build/us.v10/src/core2/bs/bWhirl.c.o(.bss);
        build/us.v10/src/core2/bs/claw.c.o(.bss);
        build/us.v10/src/core2/bs/climb.c.o(.bss);
        build/us.v10/src/core2/bs/croc.c.o(.bss);
        build/us.v10/src/core2/bs/crouch.c.o(.bss);
        build/us.v10/src/core2/bs/die.c.o(.bss);
        build/us.v10/src/core2/bs/droneenter.c.o(.bss);
        build/us.v10/src/core2/bs/dronegoto.c.o(.bss);
        build/us.v10/src/core2/bs/dronevanish.c.o(.bss);
        build/us.v10/src/core2/bs/dronexform.c.o(.bss);
        build/us.v10/src/core2/bs/jig.c.o(.bss);
        build/us.v10/src/core2/bs/jump.c.o(.bss);
        build/us.v10/src/core2/bs/ow.c.o(.bss);
        build/us.v10/src/core2/bs/pumpkin.c.o(.bss);
        build/us.v10/src/core2/bs/rebound.c.o(.bss);
        build/us.v10/src/core2/bs/sled.c.o(.bss);
        build/us.v10/src/core2/bs/slide.c.o(.bss);
        build/us.v10/src/core2/bs/splat.c.o(.bss);
        build/us.v10/src/core2/bs/stand.c.o(.bss);
        build/us.v10/src/core2/bs/swim.c.o(.bss);
        build/us.v10/src/core2/bs/surf.c.o(.bss);
        build/us.v10/src/core2/bs/talk.c.o(.bss);
        build/us.v10/src/core2/bs/throw.c.o(.bss);
        build/us.v10/src/core2/bs/turn.c.o(.bss);
        build/us.v10/src/core2/bs/twirl.c.o(.bss);
        build/us.v10/src/core2/bs/walk.c.o(.bss);
        build/us.v10/src/core2/bs/walrus.c.o(.bss);
        build/us.v10/src/core2/bs/washy.c.o(.bss);
        build/us.v10/src/core2/nc/cameranodelist.c.o(.bss);
        build/us.v10/src/core2/code_33C30.c.o(.bss);
        build/us.v10/src/core2/nc/staticCamera.c.o(.bss);
        build/us.v10/src/core2/code_34310.c.o(.bss);
        build/us.v10/src/core2/code_34790.c.o(.bss);
        build/us.v10/src/core2/code_35520.c.o(.bss);
        build/us.v10/src/core2/nc/dynamicCamera.c.o(.bss);
        build/us.v10/src/core2/code_379B0.c.o(.bss);
        build/us.v10/src/core2/nc/randomCamera.c.o(.bss);
        build/us.v10/src/core2/code_37E50.c.o(.bss);
        build/us.v10/src/core2/nc/dynamicCam10.c.o(.bss);
        build/us.v10/src/core2/nc/dynamicCam5.c.o(.bss);
        build/us.v10/src/core2/nc/dynamicCam11.c.o(.bss);
        build/us.v10/src/core2/nc/dynamicCam8.c.o(.bss);
        build/us.v10/src/core2/nc/dynamicCam4.c.o(.bss);
        build/us.v10/src/core2/nc/dynamicCamC.c.o(.bss);
        build/us.v10/src/core2/code_F8EAF0.c.o(.bss);
        build/us.v10/src/core2/nc/dynamicCamB.c.o(.bss);
        build/us.v10/src/core2/nc/dynamicCam13.c.o(.bss);
        build/us.v10/src/core2/nc/dynamicCam9.c.o(.bss);
        build/us.v10/src/core2/nc/dynamicCam12.c.o(.bss);
        build/us.v10/src/core2/nc/dynamicCam3.c.o(.bss);
        build/us.v10/src/core2/code_3B2C0.c.o(.bss);
        build/us.v10/src/core2/nc/dynamicCamF.c.o(.bss);
        build/us.v10/src/core2/nc/firstpersoncamera.c.o(.bss);
        build/us.v10/src/core2/ch/gameSelect.c.o(.bss);
        build/us.v10/src/core2/code_41460.c.o(.bss);
        build/us.v10/src/core2/code_41FB0.c.o(.bss);
        build/us.v10/src/core2/code_42CB0.c.o(.bss);
        build/us.v10/src/core2/mapspecificflags.c.o(.bss);
        build/us.v10/src/core2/code_47BD0.c.o(.bss);
        build/us.v10/src/core2/code_4A6F0.c.o(.bss);
        build/us.v10/src/core2/code_4C020.c.o(.bss);
        build/us.v10/src/core2/ch/badShad.c.o(.bss);
        build/us.v10/src/core2/ch/climbBase.c.o(.bss);
        build/us.v10/src/core2/code_55390.c.o(.bss);
        build/us.v10/src/core2/code_556C0.c.o(.bss);
        build/us.v10/src/core2/code_55850.c.o(.bss);
        build/us.v10/src/core2/ch/overlaycopyright.c.o(.bss);
        build/us.v10/src/core2/ch/overlaypressstart.c.o(.bss);
        build/us.v10/src/core2/ch/overlaynocontroller.c.o(.bss);
        build/us.v10/src/core2/ch/bottlesbonus.c.o(.bss);
        build/us.v10/src/core2/code_57C70.c.o(.bss);
        build/us.v10/src/core2/code_581D0.c.o(.bss);
        build/us.v10/src/core2/ch/bottlesbonuscursor.c.o(.bss);
        build/us.v10/src/core2/code_59A80.c.o(.bss);
        build/us.v10/src/core2/ch/snacker.c.o(.bss);
        build/us.v10/src/core2/ch/snowball.c.o(.bss);
        build/us.v10/src/core2/code_5BEB0.c.o(.bss);
        build/us.v10/src/core2/code_5C240.c.o(.bss);
        build/us.v10/src/core2/code_5C870.c.o(.bss);
        build/us.v10/src/core2/code_5DBC0.c.o(.bss);
        build/us.v10/src/core2/code_5FD90.c.o(.bss);
        build/us.v10/src/core2/code_637D0.c.o(.bss);
        build/us.v10/src/core2/code_654C0.c.o(.bss);
        build/us.v10/src/core2/code_66D90.c.o(.bss);
        build/us.v10/src/core2/gc/bound.c.o(.bss);
        build/us.v10/src/core2/code_67650.c.o(.bss);
        build/us.v10/src/core2/particle.c.o(.bss);
        build/us.v10/src/core2/code_69F60.c.o(.bss);
        build/us.v10/src/core2/code_6AEF0.c.o(.bss);
        build/us.v10/src/core2/code_6B030.c.o(.bss);
        build/us.v10/src/core2/fx/ripple.c.o(.bss);
        build/us.v10/src/core2/code_6CD20.c.o(.bss);
        build/us.v10/src/core2/code_6CEC0.c.o(.bss);
        build/us.v10/src/core2/code_6D030.c.o(.bss);
        build/us.v10/src/core2/code_6D270.c.o(.bss);
        build/us.v10/src/core2/code_6DA30.c.o(.bss);
        build/us.v10/src/core2/code_6DA30.c.o(.bss);
        build/us.v10/src/core2/code_70C30.c.o(.bss);
        build/us.v10/src/core2/code_72060.c.o(.bss);
        build/us.v10/src/core2/code_72B10.c.o(.bss);
        build/us.v10/src/core2/code_73640.c.o(.bss);
        build/us.v10/src/core2/code_74420.c.o(.bss);
        build/us.v10/src/core2/code_74910.c.o(.bss);
        build/us.v10/src/core2/code_74ED0.c.o(.bss);
        build/us.v10/src/core2/code_75480.c.o(.bss);
        build/us.v10/src/core2/code_75930.c.o(.bss);
        build/us.v10/src/core2/code_75E90.c.o(.bss);
        build/us.v10/src/core2/fx/common1score.c.o(.bss);
        build/us.v10/src/core2/fx/honeycarrierscore.c.o(.bss);
        build/us.v10/src/core2/fx/jinjoscore.c.o(.bss);
        build/us.v10/src/core2/fx/lifescore.c.o(.bss);
        build/us.v10/src/core2/fx/healthscore.c.o(.bss);
        build/us.v10/src/core2/fx/airscore.c.o(.bss);
        build/us.v10/src/core2/code_7AF80.c.o(.bss);
        build/us.v10/src/core2/mapModel.c.o(.bss);
        build/us.v10/src/core2/code_83340.c.o(.bss);
        build/us.v10/src/core2/gc/section.c.o(.bss);
        build/us.v10/src/core2/gc/sky.c.o(.bss);
        build/us.v10/src/core2/gc/transition.c.o(.bss);
        build/us.v10/src/core2/code_851D0.c.o(.bss);
        build/us.v10/src/core2/code_857B0.c.o(.bss);
        build/us.v10/src/core2/code_85800.c.o(.bss);
        build/us.v10/src/core2/gc/dialog.c.o(.bss);
        build/us.v10/src/core2/gc/pauseMenu.c.o(.bss);
        build/us.v10/src/core2/code_8DC20.c.o(.bss);
        build/us.v10/src/core2/gc/zoombox.c.o(.bss);
        build/us.v10/src/core2/code_91E10.c.o(.bss);
        build/us.v10/src/core2/gc/parade.c.o(.bss);
        build/us.v10/src/core2/code_94620.c.o(.bss);
        build/us.v10/src/core2/code_94780.c.o(.bss);
        build/us.v10/src/core2/code_956B0.c.o(.bss);
        build/us.v10/src/core2/code_98CB0.c.o(.bss);
        build/us.v10/src/core2/quizquestionaskedbitfield.c.o(.bss);
        build/us.v10/src/core2/code_999A0.c.o(.bss);
        build/us.v10/src/core2/jiggyscore.c.o(.bss);
        build/us.v10/src/core2/honeycombscore.c.o(.bss);
        build/us.v10/src/core2/mumboscore.c.o(.bss);
        build/us.v10/src/core2/code_9A740.c.o(.bss);
        build/us.v10/src/core2/code_9A9D0.c.o(.bss);
        build/us.v10/src/core2/levelspecificflags.c.o(.bss);
        build/us.v10/src/core2/code_9B180.c.o(.bss);
        build/us.v10/src/core2/code_9B650.c.o(.bss);
        build/us.v10/src/core2/code_9B990.c.o(.bss);
        build/us.v10/src/core2/code_9C170.c.o(.bss);
        build/us.v10/src/core2/timedfuncqueue.c.o(.bss);
        build/us.v10/src/core2/code_9E370.c.o(.bss);
        build/us.v10/src/core2/code_A4D00.c.o(.bss);
        build/us.v10/src/core2/code_A5BC0.c.o(.bss);
        build/us.v10/src/core2/code_ABC00.c.o(.bss);
        build/us.v10/src/core2/code_AC520.c.o(.bss);
        build/us.v10/src/core2/code_AD110.c.o(.bss);
        build/us.v10/src/core2/code_AD5B0.c.o(.bss);
        build/us.v10/src/core2/code_AE290.c.o(.bss);
        build/us.v10/src/core2/code_AEDA0.c.o(.bss);
        build/us.v10/src/core2/modelRender.c.o(.bss);
        build/us.v10/src/core2/code_B3A80.c.o(.bss);
        build/us.v10/src/core2/code_B5040.c.o(.bss);
        build/us.v10/src/core2/code_B5E00.c.o(.bss);
        build/us.v10/src/core2/code_B62B0.c.o(.bss);
        build/us.v10/src/core2/code_B6C60.c.o(.bss);
        build/us.v10/src/core2/code_B6CE0.c.o(.bss);
        build/us.v10/src/core2/code_B6EA0.c.o(.bss);
        build/us.v10/src/core2/code_B8020.c.o(.bss);
        build/us.v10/src/core2/code_B8860.c.o(.bss);
        build/us.v10/src/core2/code_B9770.c.o(.bss);
        build/us.v10/src/core2/code_BD100.c.o(.bss);
        build/us.v10/src/core2/code_BDCC0.c.o(.bss);
        build/us.v10/src/core2/code_BEF20.c.o(.bss);
        build/us.v10/src/core2/code_C0E60.c.o(.bss);
        build/us.v10/src/core2/animtexturecache.c.o(.bss);
        build/us.v10/src/core2/code_C2F30.c.o(.bss);
        build/us.v10/src/core2/rand.c.o(.bss);
        build/us.v10/src/core2/code_C4320.c.o(.bss);
        build/us.v10/src/core2/code_C4F40.c.o(.bss);
        build/us.v10/src/core2/code_C5440.c.o(.bss);
        build/us.v10/src/core2/code_C89C0.c.o(.bss);
        build/us.v10/src/core2/code_C97F0.c.o(.bss);
        build/us.v10/src/core2/code_C9E70.c.o(.bss);
        build/us.v10/src/core2/code_C9F00.c.o(.bss);
        build/us.v10/src/core2/code_CB8A0.c.o(.bss);
        build/us.v10/src/core2/code_CBBF0.c.o(.bss);
        build/us.v10/src/core2/code_CD0A0.c.o(.bss);
        build/us.v10/src/core2/code_CD6E0.c.o(.bss);
        core2_BSS_END = .;
        core2_BSS_SIZE = ABSOLUTE(core2_BSS_END - core2_BSS_START);
    }
    __romPos += SIZEOF(.core2);
    __romPos = ALIGN(__romPos, 16);
    core2_ROM_END = __romPos;
    core2_VRAM_END = .;

    CC_ROM_START = __romPos;
    CC_VRAM = ADDR(.CC);
    .CC core2_VRAM_END : AT(CC_ROM_START) SUBALIGN(16)
    {
        CC_TEXT_START = .;
        build/us.v10/src/CC/code_0.c.o(.text);
        build/us.v10/src/CC/code_530.c.o(.text);
        build/us.v10/src/CC/code_BF0.c.o(.text);
        build/us.v10/src/CC/ch/tooth.c.o(.text);
        build/us.v10/src/CC/code_13C0.c.o(.text);
        build/us.v10/src/CC/code_19B0.c.o(.text);
        build/us.v10/src/CC/code_1B90.c.o(.text);
        build/us.v10/src/CC/code_1F70.c.o(.text);
        build/us.v10/src/CC/ch/sawblade.c.o(.text);
        build/us.v10/src/CC/code_3400.c.o(.text);
        CC_TEXT_END = .;
        CC_TEXT_SIZE = ABSOLUTE(CC_TEXT_END - CC_TEXT_START);
        CC_DATA_START = .;
        CC_code_0_c = .;
        build/us.v10/src/CC/code_0.c.o(.data);
        CC_code_530_c = .;
        build/us.v10/src/CC/code_530.c.o(.data);
        CC_code_BF0_c = .;
        build/us.v10/src/CC/code_BF0.c.o(.data);
        CC_ch_tooth_c = .;
        build/us.v10/src/CC/ch/tooth.c.o(.data);
        CC_crc_c = .;
        build/us.v10/src/CC/crc.c.o(.data);
        CC_code_1B90_c = .;
        build/us.v10/src/CC/code_1B90.c.o(.data);
        CC_code_1F70_c = .;
        build/us.v10/src/CC/code_1F70.c.o(.data);
        CC_ch_sawblade_c = .;
        build/us.v10/src/CC/ch/sawblade.c.o(.data);
        CC_code_3400_c = .;
        build/us.v10/src/CC/code_3400.c.o(.data);
        CC_DATA_END = .;
        CC_DATA_SIZE = ABSOLUTE(CC_DATA_END - CC_DATA_START);
        CC_RODATA_START = .;
        build/us.v10/src/CC/code_0.c.o(.rodata);
        build/us.v10/src/CC/code_530.c.o(.rodata);
        build/us.v10/src/CC/ch/tooth.c.o(.rodata);
        build/us.v10/src/CC/code_1B90.c.o(.rodata);
        build/us.v10/src/CC/code_1F70.c.o(.rodata);
        CC_RODATA_END = .;
        CC_RODATA_SIZE = ABSOLUTE(CC_RODATA_END - CC_RODATA_START);
    }
    CC_bss_VRAM = ADDR(.CC_bss);
    .CC_bss (NOLOAD) : SUBALIGN(16)
    {
        CC_BSS_START = .;
        build/us.v10/src/CC/bss_pad.c.o(.bss);
        build/us.v10/src/CC/code_BF0.c.o(.bss);
        build/us.v10/src/CC/code_1B90.c.o(.bss);
        build/us.v10/src/CC/code_1F70.c.o(.bss);
        CC_BSS_END = .;
        CC_BSS_SIZE = ABSOLUTE(CC_BSS_END - CC_BSS_START);
    }
    __romPos += SIZEOF(.CC);
    __romPos = ALIGN(__romPos, 16);
    CC_ROM_END = __romPos;
    CC_VRAM_END = .;

    GV_ROM_START = __romPos;
    GV_VRAM = ADDR(.GV);
    .GV core2_VRAM_END : AT(GV_ROM_START) SUBALIGN(16)
    {
        GV_TEXT_START = .;
        build/us.v10/src/GV/ch/toots.c.o(.text);
        build/us.v10/src/GV/ch/ancientone.c.o(.text);
        build/us.v10/src/GV/ch/gobi1.c.o(.text);
        build/us.v10/src/GV/ch/gobi2.c.o(.text);
        build/us.v10/src/GV/ch/gobi3.c.o(.text);
        build/us.v10/src/GV/ch/gobirope.c.o(.text);
        build/us.v10/src/GV/ch/gobirock.c.o(.text);
        build/us.v10/src/GV/ch/trunker.c.o(.text);
        build/us.v10/src/GV/code_2EE0.c.o(.text);
        build/us.v10/src/GV/ch/sarcophagus.c.o(.text);
        build/us.v10/src/GV/code_3630.c.o(.text);
        build/us.v10/src/GV/code_3AA0.c.o(.text);
        build/us.v10/src/GV/code_3B10.c.o(.text);
        build/us.v10/src/GV/code_3BB0.c.o(.text);
        build/us.v10/src/GV/code_3D90.c.o(.text);
        build/us.v10/src/GV/code_43B0.c.o(.text);
        build/us.v10/src/GV/code_4740.c.o(.text);
        build/us.v10/src/GV/code_5570.c.o(.text);
        build/us.v10/src/GV/code_61E0.c.o(.text);
        build/us.v10/src/GV/code_6370.c.o(.text);
        build/us.v10/src/GV/code_6F80.c.o(.text);
        build/us.v10/src/GV/code_7060.c.o(.text);
        build/us.v10/src/GV/ch/histup.c.o(.text);
        build/us.v10/src/GV/code_7D50.c.o(.text);
        build/us.v10/src/GV/code_7DB0.c.o(.text);
        build/us.v10/src/GV/code_7FC0.c.o(.text);
        build/us.v10/src/GV/code_7FF0.c.o(.text);
        build/us.v10/src/GV/ch/mazectrl.c.o(.text);
        build/us.v10/src/GV/ch/buriedpyramid.c.o(.text);
        build/us.v10/src/GV/code_9B70.c.o(.text);
        build/us.v10/src/GV/code_9C10.c.o(.text);
        build/us.v10/src/GV/matchinggame.c.o(.text);
        build/us.v10/src/GV/waterctrl.c.o(.text);
        GV_TEXT_END = .;
        GV_TEXT_SIZE = ABSOLUTE(GV_TEXT_END - GV_TEXT_START);
        GV_DATA_START = .;
        GV_ch_toots_c = .;
        build/us.v10/src/GV/ch/toots.c.o(.data);
        GV_ch_ancientone_c = .;
        build/us.v10/src/GV/ch/ancientone.c.o(.data);
        GV_ch_gobi1_c = .;
        build/us.v10/src/GV/ch/gobi1.c.o(.data);
        GV_ch_gobi2_c = .;
        build/us.v10/src/GV/ch/gobi2.c.o(.data);
        GV_ch_gobi3_c = .;
        build/us.v10/src/GV/ch/gobi3.c.o(.data);
        GV_ch_gobirope_c = .;
        build/us.v10/src/GV/ch/gobirope.c.o(.data);
        GV_ch_gobirock_c = .;
        build/us.v10/src/GV/ch/gobirock.c.o(.data);
        GV_ch_trunker_c = .;
        build/us.v10/src/GV/ch/trunker.c.o(.data);
        GV_code_2EE0_c = .;
        build/us.v10/src/GV/code_2EE0.c.o(.data);
        GV_ch_sarcophagus_c = .;
        build/us.v10/src/GV/ch/sarcophagus.c.o(.data);
        GV_code_3630_c = .;
        build/us.v10/src/GV/code_3630.c.o(.data);
        GV_code_3AA0_c = .;
        build/us.v10/src/GV/code_3AA0.c.o(.data);
        GV_code_3B10_c = .;
        build/us.v10/src/GV/code_3B10.c.o(.data);
        GV_code_3BB0_c = .;
        build/us.v10/src/GV/code_3BB0.c.o(.data);
        GV_code_3D90_c = .;
        build/us.v10/src/GV/code_3D90.c.o(.data);
        GV_code_43B0_c = .;
        build/us.v10/src/GV/code_43B0.c.o(.data);
        GV_code_4740_c = .;
        build/us.v10/src/GV/code_4740.c.o(.data);
        GV_code_5570_c = .;
        build/us.v10/src/GV/code_5570.c.o(.data);
        GV_code_61E0_c = .;
        build/us.v10/src/GV/code_61E0.c.o(.data);
        GV_code_6370_c = .;
        build/us.v10/src/GV/code_6370.c.o(.data);
        GV_code_6F80_c = .;
        build/us.v10/src/GV/code_6F80.c.o(.data);
        GV_code_7060_c = .;
        build/us.v10/src/GV/code_7060.c.o(.data);
        GV_ch_histup_c = .;
        build/us.v10/src/GV/ch/histup.c.o(.data);
        GV_code_7DB0_c = .;
        build/us.v10/src/GV/code_7DB0.c.o(.data);
        GV_code_7FC0_c = .;
        build/us.v10/src/GV/code_7FC0.c.o(.data);
        GV_code_7FF0_c = .;
        build/us.v10/src/GV/code_7FF0.c.o(.data);
        GV_ch_mazectrl_c = .;
        build/us.v10/src/GV/ch/mazectrl.c.o(.data);
        GV_ch_buriedpyramid_c = .;
        build/us.v10/src/GV/ch/buriedpyramid.c.o(.data);
        GV_matchinggame_c = .;
        build/us.v10/src/GV/matchinggame.c.o(.data);
        GV_DATA_END = .;
        GV_DATA_SIZE = ABSOLUTE(GV_DATA_END - GV_DATA_START);
        GV_RODATA_START = .;
        build/us.v10/src/GV/ch/ancientone.c.o(.rodata);
        build/us.v10/src/GV/ch/gobi1.c.o(.rodata);
        build/us.v10/src/GV/ch/gobi2.c.o(.rodata);
        build/us.v10/src/GV/ch/gobi3.c.o(.rodata);
        build/us.v10/src/GV/ch/gobirock.c.o(.rodata);
        build/us.v10/src/GV/ch/sarcophagus.c.o(.rodata);
        build/us.v10/src/GV/code_3BB0.c.o(.rodata);
        build/us.v10/src/GV/code_3D90.c.o(.rodata);
        build/us.v10/src/GV/code_43B0.c.o(.rodata);
        build/us.v10/src/GV/code_4740.c.o(.rodata);
        build/us.v10/src/GV/code_5570.c.o(.rodata);
        build/us.v10/src/GV/code_6370.c.o(.rodata);
        build/us.v10/src/GV/code_7060.c.o(.rodata);
        build/us.v10/src/GV/ch/histup.c.o(.rodata);
        build/us.v10/src/GV/code_7FF0.c.o(.rodata);
        build/us.v10/src/GV/ch/mazectrl.c.o(.rodata);
        build/us.v10/src/GV/ch/buriedpyramid.c.o(.rodata);
        build/us.v10/src/GV/matchinggame.c.o(.rodata);
        build/us.v10/src/GV/waterctrl.c.o(.rodata);
        GV_RODATA_END = .;
        GV_RODATA_SIZE = ABSOLUTE(GV_RODATA_END - GV_RODATA_START);
    }
    GV_bss_VRAM = ADDR(.GV_bss);
    .GV_bss (NOLOAD) : SUBALIGN(16)
    {
        GV_BSS_START = .;
        build/us.v10/src/GV/bss_pad.c.o(.bss);
        build/us.v10/src/GV/ch/toots.c.o(.bss);
        build/us.v10/src/GV/ch/gobi1.c.o(.bss);
        build/us.v10/src/GV/ch/gobi2.c.o(.bss);
        build/us.v10/src/GV/ch/gobirock.c.o(.bss);
        build/us.v10/src/GV/code_4740.c.o(.bss);
        build/us.v10/src/GV/code_5570.c.o(.bss);
        build/us.v10/src/GV/code_61E0.c.o(.bss);
        build/us.v10/src/GV/code_6F80.c.o(.bss);
        build/us.v10/src/GV/code_7D50.c.o(.bss);
        build/us.v10/src/GV/code_7FF0.c.o(.bss);
        build/us.v10/src/GV/code_9C10.c.o(.bss);
        build/us.v10/src/GV/matchinggame.c.o(.bss);
        build/us.v10/src/GV/waterctrl.c.o(.bss);
        GV_BSS_END = .;
        GV_BSS_SIZE = ABSOLUTE(GV_BSS_END - GV_BSS_START);
    }
    __romPos += SIZEOF(.GV);
    __romPos = ALIGN(__romPos, 16);
    GV_ROM_END = __romPos;
    GV_VRAM_END = .;

    MMM_ROM_START = __romPos;
    MMM_VRAM = ADDR(.MMM);
    .MMM core2_VRAM_END : AT(MMM_ROM_START) SUBALIGN(16)
    {
        MMM_TEXT_START = .;
        build/us.v10/src/MMM/ch/loggo.c.o(.text);
        build/us.v10/src/MMM/ch/napper.c.o(.text);
        build/us.v10/src/MMM/code_DC0.c.o(.text);
        build/us.v10/src/MMM/ch/motzhand.c.o(.text);
        build/us.v10/src/MMM/code_16B0.c.o(.text);
        build/us.v10/src/MMM/code_2040.c.o(.text);
        build/us.v10/src/MMM/code_2F60.c.o(.text);
        build/us.v10/src/MMM/code_3120.c.o(.text);
        build/us.v10/src/MMM/code_3420.c.o(.text);
        build/us.v10/src/MMM/crc.c.o(.text);
        build/us.v10/src/MMM/code_3D50.c.o(.text);
        build/us.v10/src/MMM/code_47D0.c.o(.text);
        build/us.v10/src/MMM/code_5000.c.o(.text);
        MMM_TEXT_END = .;
        MMM_TEXT_SIZE = ABSOLUTE(MMM_TEXT_END - MMM_TEXT_START);
        MMM_DATA_START = .;
        MMM_ch_loggo_c = .;
        build/us.v10/src/MMM/ch/loggo.c.o(.data);
        MMM_ch_napper_c = .;
        build/us.v10/src/MMM/ch/napper.c.o(.data);
        MMM_code_DC0_c = .;
        build/us.v10/src/MMM/code_DC0.c.o(.data);
        MMM_ch_motzhand_c = .;
        build/us.v10/src/MMM/ch/motzhand.c.o(.data);
        MMM_code_16B0_c = .;
        build/us.v10/src/MMM/code_16B0.c.o(.data);
        MMM_code_2040_c = .;
        build/us.v10/src/MMM/code_2040.c.o(.data);
        MMM_code_2F60_c = .;
        build/us.v10/src/MMM/code_2F60.c.o(.data);
        MMM_code_3420_c = .;
        build/us.v10/src/MMM/code_3420.c.o(.data);
        MMM_code_3D50_c = .;
        build/us.v10/src/MMM/code_3D50.c.o(.data);
        MMM_crc_c = .;
        build/us.v10/src/MMM/crc.c.o(.data);
        MMM_code_5000_c = .;
        build/us.v10/src/MMM/code_5000.c.o(.data);
        MMM_DATA_END = .;
        MMM_DATA_SIZE = ABSOLUTE(MMM_DATA_END - MMM_DATA_START);
        MMM_RODATA_START = .;
        build/us.v10/src/MMM/ch/loggo.c.o(.rodata);
        build/us.v10/src/MMM/ch/napper.c.o(.rodata);
        build/us.v10/src/MMM/ch/motzhand.c.o(.rodata);
        build/us.v10/src/MMM/code_16B0.c.o(.rodata);
        build/us.v10/src/MMM/code_2040.c.o(.rodata);
        build/us.v10/src/MMM/code_3120.c.o(.rodata);
        build/us.v10/src/MMM/code_3420.c.o(.rodata);
        build/us.v10/src/MMM/code_3D50.c.o(.rodata);
        build/us.v10/src/MMM/code_47D0.c.o(.rodata);
        build/us.v10/src/MMM/code_5000.c.o(.rodata);
        MMM_RODATA_END = .;
        MMM_RODATA_SIZE = ABSOLUTE(MMM_RODATA_END - MMM_RODATA_START);
    }
    MMM_bss_VRAM = ADDR(.MMM_bss);
    .MMM_bss (NOLOAD) : SUBALIGN(16)
    {
        MMM_BSS_START = .;
        build/us.v10/src/MMM/bss_pad.c.o(.bss);
        build/us.v10/src/MMM/code_2040.c.o(.bss);
        build/us.v10/src/MMM/code_3120.c.o(.bss);
        build/us.v10/src/MMM/code_3420.c.o(.bss);
        build/us.v10/src/MMM/code_3D50.c.o(.bss);
        MMM_BSS_END = .;
        MMM_BSS_SIZE = ABSOLUTE(MMM_BSS_END - MMM_BSS_START);
    }
    __romPos += SIZEOF(.MMM);
    __romPos = ALIGN(__romPos, 16);
    MMM_ROM_END = __romPos;
    MMM_VRAM_END = .;

    TTC_ROM_START = __romPos;
    TTC_VRAM = ADDR(.TTC);
    .TTC core2_VRAM_END : AT(TTC_ROM_START) SUBALIGN(16)
    {
        TTC_TEXT_START = .;
        build/us.v10/src/TTC/ch/clam.c.o(.text);
        build/us.v10/src/TTC/ch/blubber.c.o(.text);
        build/us.v10/src/TTC/ch/nipper.c.o(.text);
        build/us.v10/src/TTC/code_26D0.c.o(.text);
        build/us.v10/src/TTC/ch/leaky.c.o(.text);
        build/us.v10/src/TTC/code_3040.c.o(.text);
        build/us.v10/src/TTC/ch/lockup.c.o(.text);
        build/us.v10/src/TTC/ch/treasurehunt.c.o(.text);
        build/us.v10/src/TTC/code_3E30.c.o(.text);
        build/us.v10/src/TTC/ch/treasure.c.o(.text);
        TTC_TEXT_END = .;
        TTC_TEXT_SIZE = ABSOLUTE(TTC_TEXT_END - TTC_TEXT_START);
        TTC_DATA_START = .;
        TTC_ch_clam_c = .;
        build/us.v10/src/TTC/ch/clam.c.o(.data);
        TTC_ch_blubber_c = .;
        build/us.v10/src/TTC/ch/blubber.c.o(.data);
        TTC_ch_nipper_c = .;
        build/us.v10/src/TTC/ch/nipper.c.o(.data);
        TTC_code_26D0_c = .;
        build/us.v10/src/TTC/code_26D0.c.o(.data);
        TTC_ch_leaky_c = .;
        build/us.v10/src/TTC/ch/leaky.c.o(.data);
        TTC_code_3040_c = .;
        build/us.v10/src/TTC/code_3040.c.o(.data);
        TTC_ch_lockup_c = .;
        build/us.v10/src/TTC/ch/lockup.c.o(.data);
        TTC_ch_treasurehunt_c = .;
        build/us.v10/src/TTC/ch/treasurehunt.c.o(.data);
        TTC_code_3E30_c = .;
        build/us.v10/src/TTC/code_3E30.c.o(.data);
        TTC_ch_treasure_c = .;
        build/us.v10/src/TTC/ch/treasure.c.o(.data);
        TTC_DATA_END = .;
        TTC_DATA_SIZE = ABSOLUTE(TTC_DATA_END - TTC_DATA_START);
        TTC_RODATA_START = .;
        build/us.v10/src/TTC/ch/clam.c.o(.rodata);
        build/us.v10/src/TTC/ch/blubber.c.o(.rodata);
        build/us.v10/src/TTC/ch/nipper.c.o(.rodata);
        build/us.v10/src/TTC/code_26D0.c.o(.rodata);
        build/us.v10/src/TTC/ch/leaky.c.o(.rodata);
        build/us.v10/src/TTC/ch/lockup.c.o(.rodata);
        build/us.v10/src/TTC/ch/treasurehunt.c.o(.rodata);
        build/us.v10/src/TTC/code_3E30.c.o(.rodata);
        build/us.v10/src/TTC/ch/treasure.c.o(.rodata);
        TTC_RODATA_END = .;
        TTC_RODATA_SIZE = ABSOLUTE(TTC_RODATA_END - TTC_RODATA_START);
    }
    TTC_bss_VRAM = ADDR(.TTC_bss);
    .TTC_bss (NOLOAD) : SUBALIGN(16)
    {
        TTC_BSS_START = .;
        build/us.v10/src/TTC/code_3040.c.o(.bss);
        build/us.v10/src/TTC/ch/treasurehunt.c.o(.bss);
        build/us.v10/src/TTC/code_3E30.c.o(.bss);
        TTC_BSS_END = .;
        TTC_BSS_SIZE = ABSOLUTE(TTC_BSS_END - TTC_BSS_START);
    }
    __romPos += SIZEOF(.TTC);
    __romPos = ALIGN(__romPos, 16);
    TTC_ROM_END = __romPos;
    TTC_VRAM_END = .;

    MM_ROM_START = __romPos;
    MM_VRAM = ADDR(.MM);
    .MM core2_VRAM_END : AT(MM_ROM_START) SUBALIGN(16)
    {
        MM_TEXT_START = .;
        build/us.v10/src/MM/ch/orangepad.c.o(.text);
        build/us.v10/src/MM/ch/hut.c.o(.text);
        build/us.v10/src/MM/ch/chimpystump.c.o(.text);
        build/us.v10/src/MM/ch/conga.c.o(.text);
        build/us.v10/src/MM/crc.c.o(.text);
        build/us.v10/src/MM/ch/orange.c.o(.text);
        build/us.v10/src/MM/ch/lmonkey.c.o(.text);
        build/us.v10/src/MM/code_24C0.c.o(.text);
        build/us.v10/src/MM/ch/grublin.c.o(.text);
        build/us.v10/src/MM/ch/jujuhitbox.c.o(.text);
        build/us.v10/src/MM/ch/juju.c.o(.text);
        MM_TEXT_END = .;
        MM_TEXT_SIZE = ABSOLUTE(MM_TEXT_END - MM_TEXT_START);
        MM_DATA_START = .;
        MM_ch_orangepad_c = .;
        build/us.v10/src/MM/ch/orangepad.c.o(.data);
        MM_ch_hut_c = .;
        build/us.v10/src/MM/ch/hut.c.o(.data);
        MM_ch_chimpystump_c = .;
        build/us.v10/src/MM/ch/chimpystump.c.o(.data);
        MM_ch_conga_c = .;
        build/us.v10/src/MM/ch/conga.c.o(.data);
        MM_crc_c = .;
        build/us.v10/src/MM/crc.c.o(.data);
        MM_ch_orange_c = .;
        build/us.v10/src/MM/ch/orange.c.o(.data);
        MM_ch_lmonkey_c = .;
        build/us.v10/src/MM/ch/lmonkey.c.o(.data);
        MM_ch_grublin_c = .;
        build/us.v10/src/MM/ch/grublin.c.o(.data);
        MM_ch_jujuhitbox_c = .;
        build/us.v10/src/MM/ch/jujuhitbox.c.o(.data);
        MM_ch_juju_c = .;
        build/us.v10/src/MM/ch/juju.c.o(.data);
        MM_DATA_END = .;
        MM_DATA_SIZE = ABSOLUTE(MM_DATA_END - MM_DATA_START);
        MM_RODATA_START = .;
        build/us.v10/src/MM/ch/orangepad.c.o(.rodata);
        build/us.v10/src/MM/ch/hut.c.o(.rodata);
        build/us.v10/src/MM/ch/conga.c.o(.rodata);
        build/us.v10/src/MM/ch/orange.c.o(.rodata);
        build/us.v10/src/MM/ch/lmonkey.c.o(.rodata);
        build/us.v10/src/MM/ch/grublin.c.o(.rodata);
        build/us.v10/src/MM/ch/jujuhitbox.c.o(.rodata);
        build/us.v10/src/MM/ch/juju.c.o(.rodata);
        MM_RODATA_END = .;
        MM_RODATA_SIZE = ABSOLUTE(MM_RODATA_END - MM_RODATA_START);
    }
    MM_bss_VRAM = ADDR(.MM_bss);
    .MM_bss (NOLOAD) : SUBALIGN(16)
    {
        MM_BSS_START = .;
        build/us.v10/src/MM/ch/hut.c.o(.bss);
        build/us.v10/src/MM/ch/juju.c.o(.bss);
        MM_BSS_END = .;
        MM_BSS_SIZE = ABSOLUTE(MM_BSS_END - MM_BSS_START);
    }
    __romPos += SIZEOF(.MM);
    __romPos = ALIGN(__romPos, 16);
    MM_ROM_END = __romPos;
    MM_VRAM_END = .;

    BGS_ROM_START = __romPos;
    BGS_VRAM = ADDR(.BGS);
    .BGS core2_VRAM_END : AT(BGS_ROM_START) SUBALIGN(16)
    {
        BGS_TEXT_START = .;
        build/us.v10/src/BGS/ch/flibbit.c.o(.text);
        build/us.v10/src/BGS/ch/pinkegg.c.o(.text);
        build/us.v10/src/BGS/ch/croctus.c.o(.text);
        build/us.v10/src/BGS/ch/code_2270.c.o(.text);
        build/us.v10/src/BGS/code_3030.c.o(.text);
        build/us.v10/src/BGS/code_3420.c.o(.text);
        build/us.v10/src/BGS/ch/yumblie.c.o(.text);
        build/us.v10/src/BGS/ch/mrvile.c.o(.text);
        build/us.v10/src/BGS/ch/frogminigame.c.o(.text);
        build/us.v10/src/BGS/ch/yellowflibbit.c.o(.text);
        build/us.v10/src/BGS/ch/mudhut.c.o(.text);
        build/us.v10/src/BGS/ch/code_8A60.c.o(.text);
        build/us.v10/src/BGS/code_8DF0.c.o(.text);
        build/us.v10/src/BGS/ch/tanktup.c.o(.text);
        build/us.v10/src/BGS/code_9750.c.o(.text);
        build/us.v10/src/BGS/ch/bigalligator.c.o(.text);
        build/us.v10/src/BGS/ch/leafboat.c.o(.text);
        BGS_TEXT_END = .;
        BGS_TEXT_SIZE = ABSOLUTE(BGS_TEXT_END - BGS_TEXT_START);
        BGS_DATA_START = .;
        BGS_ch_flibbit_c = .;
        build/us.v10/src/BGS/ch/flibbit.c.o(.data);
        BGS_ch_pinkegg_c = .;
        build/us.v10/src/BGS/ch/pinkegg.c.o(.data);
        BGS_ch_croctus_c = .;
        build/us.v10/src/BGS/ch/croctus.c.o(.data);
        BGS_ch_code_2270_c = .;
        build/us.v10/src/BGS/ch/code_2270.c.o(.data);
        BGS_code_3030_c = .;
        build/us.v10/src/BGS/code_3030.c.o(.data);
        BGS_code_3420_c = .;
        build/us.v10/src/BGS/code_3420.c.o(.data);
        BGS_ch_yumblie_c = .;
        build/us.v10/src/BGS/ch/yumblie.c.o(.data);
        BGS_ch_mrvile_c = .;
        build/us.v10/src/BGS/ch/mrvile.c.o(.data);
        BGS_ch_frogminigame_c = .;
        build/us.v10/src/BGS/ch/frogminigame.c.o(.data);
        BGS_ch_yellowflibbit_c = .;
        build/us.v10/src/BGS/ch/yellowflibbit.c.o(.data);
        BGS_crc_c = .;
        build/us.v10/src/BGS/crc.c.o(.data);
        BGS_ch_mudhut_c = .;
        build/us.v10/src/BGS/ch/mudhut.c.o(.data);
        BGS_ch_code_8A60_c = .;
        build/us.v10/src/BGS/ch/code_8A60.c.o(.data);
        BGS_ch_tanktup_c = .;
        build/us.v10/src/BGS/ch/tanktup.c.o(.data);
        BGS_code_9750_c = .;
        build/us.v10/src/BGS/code_9750.c.o(.data);
        BGS_ch_bigalligator_c = .;
        build/us.v10/src/BGS/ch/bigalligator.c.o(.data);
        BGS_ch_leafboat_c = .;
        build/us.v10/src/BGS/ch/leafboat.c.o(.data);
        BGS_DATA_END = .;
        BGS_DATA_SIZE = ABSOLUTE(BGS_DATA_END - BGS_DATA_START);
        BGS_RODATA_START = .;
        build/us.v10/src/BGS/ch/flibbit.c.o(.rodata);
        build/us.v10/src/BGS/ch/croctus.c.o(.rodata);
        build/us.v10/src/BGS/ch/code_2270.c.o(.rodata);
        build/us.v10/src/BGS/code_3030.c.o(.rodata);
        build/us.v10/src/BGS/code_3420.c.o(.rodata);
        build/us.v10/src/BGS/ch/yumblie.c.o(.rodata);
        build/us.v10/src/BGS/ch/mrvile.c.o(.rodata);
        build/us.v10/src/BGS/ch/frogminigame.c.o(.rodata);
        build/us.v10/src/BGS/ch/yellowflibbit.c.o(.rodata);
        build/us.v10/src/BGS/ch/mudhut.c.o(.rodata);
        build/us.v10/src/BGS/ch/code_8A60.c.o(.rodata);
        build/us.v10/src/BGS/ch/tanktup.c.o(.rodata);
        build/us.v10/src/BGS/code_9750.c.o(.rodata);
        build/us.v10/src/BGS/ch/leafboat.c.o(.rodata);
        BGS_RODATA_END = .;
        BGS_RODATA_SIZE = ABSOLUTE(BGS_RODATA_END - BGS_RODATA_START);
    }
    BGS_bss_VRAM = ADDR(.BGS_bss);
    .BGS_bss (NOLOAD) : SUBALIGN(16)
    {
        BGS_BSS_START = .;
        build/us.v10/src/BGS/bss_pad.c.o(.bss);
        build/us.v10/src/BGS/ch/frogminigame.c.o(.bss);
        BGS_BSS_END = .;
        BGS_BSS_SIZE = ABSOLUTE(BGS_BSS_END - BGS_BSS_START);
    }
    __romPos += SIZEOF(.BGS);
    __romPos = ALIGN(__romPos, 16);
    BGS_ROM_END = __romPos;
    BGS_VRAM_END = .;

    RBB_ROM_START = __romPos;
    RBB_VRAM = ADDR(.RBB);
    .RBB core2_VRAM_END : AT(RBB_ROM_START) SUBALIGN(16)
    {
        RBB_TEXT_START = .;
        build/us.v10/src/RBB/ch/eggtoll1.c.o(.text);
        build/us.v10/src/RBB/code_640.c.o(.text);
        build/us.v10/src/RBB/code_CA0.c.o(.text);
        build/us.v10/src/RBB/code_1570.c.o(.text);
        build/us.v10/src/RBB/ch/grimlet.c.o(.text);
        build/us.v10/src/RBB/ch/cog.c.o(.text);
        build/us.v10/src/RBB/ch/axle.c.o(.text);
        build/us.v10/src/RBB/ch/enginefan.c.o(.text);
        build/us.v10/src/RBB/ch/enginefanswitch.c.o(.text);
        build/us.v10/src/RBB/ch/propellor.c.o(.text);
        build/us.v10/src/RBB/ch/propellorswitch.c.o(.text);
        build/us.v10/src/RBB/ch/engineparts.c.o(.text);
        build/us.v10/src/RBB/ch/whistleswitch.c.o(.text);
        build/us.v10/src/RBB/ch/whistle.c.o(.text);
        build/us.v10/src/RBB/ch/whistlectrl.c.o(.text);
        build/us.v10/src/RBB/ch/anchorswitch.c.o(.text);
        build/us.v10/src/RBB/ch/dolphin.c.o(.text);
        build/us.v10/src/RBB/ch/anchor.c.o(.text);
        build/us.v10/src/RBB/ch/anchorctrl.c.o(.text);
        build/us.v10/src/RBB/ch/rarewareflag.c.o(.text);
        build/us.v10/src/RBB/ch/bossboombox.c.o(.text);
        build/us.v10/src/RBB/ch/bossboomboxctrl.c.o(.text);
        build/us.v10/src/RBB/ch/bellbuoy.c.o(.text);
        build/us.v10/src/RBB/ch/rowboat.c.o(.text);
        build/us.v10/src/RBB/ch/boombox.c.o(.text);
        build/us.v10/src/RBB/code_9670.c.o(.text);
        build/us.v10/src/RBB/code_9840.c.o(.text);
        build/us.v10/src/RBB/propellorctrl.c.o(.text);
        RBB_TEXT_END = .;
        RBB_TEXT_SIZE = ABSOLUTE(RBB_TEXT_END - RBB_TEXT_START);
        RBB_DATA_START = .;
        RBB_ch_eggtoll1_c = .;
        build/us.v10/src/RBB/ch/eggtoll1.c.o(.data);
        RBB_code_640_c = .;
        build/us.v10/src/RBB/code_640.c.o(.data);
        RBB_code_CA0_c = .;
        build/us.v10/src/RBB/code_CA0.c.o(.data);
        RBB_code_1570_c = .;
        build/us.v10/src/RBB/code_1570.c.o(.data);
        RBB_ch_grimlet_c = .;
        build/us.v10/src/RBB/ch/grimlet.c.o(.data);
        RBB_ch_cog_c = .;
        build/us.v10/src/RBB/ch/cog.c.o(.data);
        RBB_ch_axle_c = .;
        build/us.v10/src/RBB/ch/axle.c.o(.data);
        RBB_ch_enginefan_c = .;
        build/us.v10/src/RBB/ch/enginefan.c.o(.data);
        RBB_ch_enginefanswitch_c = .;
        build/us.v10/src/RBB/ch/enginefanswitch.c.o(.data);
        RBB_ch_propellor_c = .;
        build/us.v10/src/RBB/ch/propellor.c.o(.data);
        RBB_ch_propellorswitch_c = .;
        build/us.v10/src/RBB/ch/propellorswitch.c.o(.data);
        RBB_ch_engineparts_c = .;
        build/us.v10/src/RBB/ch/engineparts.c.o(.data);
        RBB_ch_whistleswitch_c = .;
        build/us.v10/src/RBB/ch/whistleswitch.c.o(.data);
        RBB_ch_whistle_c = .;
        build/us.v10/src/RBB/ch/whistle.c.o(.data);
        RBB_ch_whistlectrl_c = .;
        build/us.v10/src/RBB/ch/whistlectrl.c.o(.data);
        RBB_ch_anchorswitch_c = .;
        build/us.v10/src/RBB/ch/anchorswitch.c.o(.data);
        RBB_ch_dolphin_c = .;
        build/us.v10/src/RBB/ch/dolphin.c.o(.data);
        RBB_ch_anchor_c = .;
        build/us.v10/src/RBB/ch/anchor.c.o(.data);
        RBB_ch_anchorctrl_c = .;
        build/us.v10/src/RBB/ch/anchorctrl.c.o(.data);
        RBB_ch_rarewareflag_c = .;
        build/us.v10/src/RBB/ch/rarewareflag.c.o(.data);
        RBB_ch_bossboombox_c = .;
        build/us.v10/src/RBB/ch/bossboombox.c.o(.data);
        RBB_ch_bossboomboxctrl_c = .;
        build/us.v10/src/RBB/ch/bossboomboxctrl.c.o(.data);
        RBB_ch_bellbuoy_c = .;
        build/us.v10/src/RBB/ch/bellbuoy.c.o(.data);
        RBB_ch_rowboat_c = .;
        build/us.v10/src/RBB/ch/rowboat.c.o(.data);
        RBB_ch_boombox_c = .;
        build/us.v10/src/RBB/ch/boombox.c.o(.data);
        RBB_code_9670_c = .;
        build/us.v10/src/RBB/code_9670.c.o(.data);
        RBB_code_9840_c = .;
        build/us.v10/src/RBB/code_9840.c.o(.data);
        RBB_DATA_END = .;
        RBB_DATA_SIZE = ABSOLUTE(RBB_DATA_END - RBB_DATA_START);
        RBB_RODATA_START = .;
        build/us.v10/src/RBB/code_640.c.o(.rodata);
        build/us.v10/src/RBB/code_CA0.c.o(.rodata);
        build/us.v10/src/RBB/code_1570.c.o(.rodata);
        build/us.v10/src/RBB/ch/grimlet.c.o(.rodata);
        build/us.v10/src/RBB/ch/axle.c.o(.rodata);
        build/us.v10/src/RBB/ch/enginefanswitch.c.o(.rodata);
        build/us.v10/src/RBB/ch/propellor.c.o(.rodata);
        build/us.v10/src/RBB/ch/propellorswitch.c.o(.rodata);
        build/us.v10/src/RBB/ch/whistle.c.o(.rodata);
        build/us.v10/src/RBB/ch/whistlectrl.c.o(.rodata);
        build/us.v10/src/RBB/ch/dolphin.c.o(.rodata);
        build/us.v10/src/RBB/ch/anchor.c.o(.rodata);
        build/us.v10/src/RBB/ch/anchorctrl.c.o(.rodata);
        build/us.v10/src/RBB/ch/bossboombox.c.o(.rodata);
        build/us.v10/src/RBB/ch/bellbuoy.c.o(.rodata);
        build/us.v10/src/RBB/ch/rowboat.c.o(.rodata);
        build/us.v10/src/RBB/ch/boombox.c.o(.rodata);
        build/us.v10/src/RBB/code_9670.c.o(.rodata);
        RBB_RODATA_END = .;
        RBB_RODATA_SIZE = ABSOLUTE(RBB_RODATA_END - RBB_RODATA_START);
    }
    RBB_bss_VRAM = ADDR(.RBB_bss);
    .RBB_bss (NOLOAD) : SUBALIGN(16)
    {
        RBB_BSS_START = .;
        build/us.v10/src/RBB/bss_pad.c.o(.bss);
        build/us.v10/src/RBB/ch/bossboombox.c.o(.bss);
        build/us.v10/src/RBB/ch/boombox.c.o(.bss);
        build/us.v10/src/RBB/ch/boombox.c.o(.bss);
        build/us.v10/src/RBB/code_9670.c.o(.bss);
        build/us.v10/src/RBB/propellorctrl.c.o(.bss);
        RBB_BSS_END = .;
        RBB_BSS_SIZE = ABSOLUTE(RBB_BSS_END - RBB_BSS_START);
    }
    __romPos += SIZEOF(.RBB);
    __romPos = ALIGN(__romPos, 16);
    RBB_ROM_END = __romPos;
    RBB_VRAM_END = .;

    FP_ROM_START = __romPos;
    FP_VRAM = ADDR(.FP);
    .FP core2_VRAM_END : AT(FP_ROM_START) SUBALIGN(16)
    {
        FP_TEXT_START = .;
        build/us.v10/src/FP/ch/scarfsled.c.o(.text);
        build/us.v10/src/FP/ch/racesled.c.o(.text);
        build/us.v10/src/FP/ch/snowmanbutton.c.o(.text);
        build/us.v10/src/FP/ch/xmastree.c.o(.text);
        build/us.v10/src/FP/ch/boggy1.c.o(.text);
        build/us.v10/src/FP/code_19E0.c.o(.text);
        build/us.v10/src/FP/code_1FF0.c.o(.text);
        build/us.v10/src/FP/ch/boggy2.c.o(.text);
        build/us.v10/src/FP/ch/bearcub.c.o(.text);
        build/us.v10/src/FP/sirslushgame.c.o(.text);
        build/us.v10/src/FP/snowmanbuttongame.c.o(.text);
        build/us.v10/src/FP/racectrl.c.o(.text);
        build/us.v10/src/FP/ch/twinkly.c.o(.text);
        build/us.v10/src/FP/ch/twinklybox.c.o(.text);
        build/us.v10/src/FP/ch/twinklymuncher.c.o(.text);
        build/us.v10/src/FP/ch/xmastreeswitch.c.o(.text);
        build/us.v10/src/FP/ch/xmastreestar.c.o(.text);
        build/us.v10/src/FP/ch/present.c.o(.text);
        build/us.v10/src/FP/ch/wozza.c.o(.text);
        build/us.v10/src/FP/ch/wozzasjig.c.o(.text);
        build/us.v10/src/FP/ch/boggy3.c.o(.text);
        build/us.v10/src/FP/code_A1C0.c.o(.text);
        build/us.v10/src/FP/ch/cavewozza.c.o(.text);
        build/us.v10/src/FP/ch/xmastreeice.c.o(.text);
        build/us.v10/src/FP/ch/xmastreeeggtoll.c.o(.text);
        build/us.v10/src/FP/code_ABD0.c.o(.text);
        build/us.v10/src/FP/code_B4D0.c.o(.text);
        FP_TEXT_END = .;
        FP_TEXT_SIZE = ABSOLUTE(FP_TEXT_END - FP_TEXT_START);
        FP_DATA_START = .;
        FP_ch_scarfsled_c = .;
        build/us.v10/src/FP/ch/scarfsled.c.o(.data);
        FP_ch_racesled_c = .;
        build/us.v10/src/FP/ch/racesled.c.o(.data);
        FP_ch_snowmanbutton_c = .;
        build/us.v10/src/FP/ch/snowmanbutton.c.o(.data);
        FP_ch_xmastree_c = .;
        build/us.v10/src/FP/ch/xmastree.c.o(.data);
        FP_ch_boggy1_c = .;
        build/us.v10/src/FP/ch/boggy1.c.o(.data);
        FP_code_19E0_c = .;
        build/us.v10/src/FP/code_19E0.c.o(.data);
        FP_code_1FF0_c = .;
        build/us.v10/src/FP/code_1FF0.c.o(.data);
        FP_ch_boggy2_c = .;
        build/us.v10/src/FP/ch/boggy2.c.o(.data);
        FP_ch_bearcub_c = .;
        build/us.v10/src/FP/ch/bearcub.c.o(.data);
        FP_sirslushgame_c = .;
        build/us.v10/src/FP/sirslushgame.c.o(.data);
        FP_snowmanbuttongame_c = .;
        build/us.v10/src/FP/snowmanbuttongame.c.o(.data);
        FP_racectrl_c = .;
        build/us.v10/src/FP/racectrl.c.o(.data);
        FP_ch_twinkly_c = .;
        build/us.v10/src/FP/ch/twinkly.c.o(.data);
        FP_ch_twinklybox_c = .;
        build/us.v10/src/FP/ch/twinklybox.c.o(.data);
        FP_ch_twinklymuncher_c = .;
        build/us.v10/src/FP/ch/twinklymuncher.c.o(.data);
        FP_ch_xmastreeswitch_c = .;
        build/us.v10/src/FP/ch/xmastreeswitch.c.o(.data);
        FP_ch_xmastreestar_c = .;
        build/us.v10/src/FP/ch/xmastreestar.c.o(.data);
        FP_ch_present_c = .;
        build/us.v10/src/FP/ch/present.c.o(.data);
        FP_ch_wozza_c = .;
        build/us.v10/src/FP/ch/wozza.c.o(.data);
        FP_ch_wozzasjig_c = .;
        build/us.v10/src/FP/ch/wozzasjig.c.o(.data);
        FP_ch_boggy3_c = .;
        build/us.v10/src/FP/ch/boggy3.c.o(.data);
        FP_code_A1C0_c = .;
        build/us.v10/src/FP/code_A1C0.c.o(.data);
        FP_ch_cavewozza_c = .;
        build/us.v10/src/FP/ch/cavewozza.c.o(.data);
        FP_ch_xmastreeice_c = .;
        build/us.v10/src/FP/ch/xmastreeice.c.o(.data);
        FP_ch_xmastreeeggtoll_c = .;
        build/us.v10/src/FP/ch/xmastreeeggtoll.c.o(.data);
        FP_code_ABD0_c = .;
        build/us.v10/src/FP/code_ABD0.c.o(.data);
        FP_DATA_END = .;
        FP_DATA_SIZE = ABSOLUTE(FP_DATA_END - FP_DATA_START);
        FP_RODATA_START = .;
        build/us.v10/src/FP/ch/scarfsled.c.o(.rodata);
        build/us.v10/src/FP/ch/xmastree.c.o(.rodata);
        build/us.v10/src/FP/ch/boggy1.c.o(.rodata);
        build/us.v10/src/FP/code_19E0.c.o(.rodata);
        build/us.v10/src/FP/code_1FF0.c.o(.rodata);
        build/us.v10/src/FP/ch/boggy2.c.o(.rodata);
        build/us.v10/src/FP/ch/bearcub.c.o(.rodata);
        build/us.v10/src/FP/racectrl.c.o(.rodata);
        build/us.v10/src/FP/ch/twinkly.c.o(.rodata);
        build/us.v10/src/FP/ch/twinklybox.c.o(.rodata);
        build/us.v10/src/FP/ch/twinklymuncher.c.o(.rodata);
        build/us.v10/src/FP/ch/xmastreestar.c.o(.rodata);
        build/us.v10/src/FP/ch/wozza.c.o(.rodata);
        build/us.v10/src/FP/ch/wozzasjig.c.o(.rodata);
        build/us.v10/src/FP/ch/xmastreeice.c.o(.rodata);
        build/us.v10/src/FP/ch/xmastreeeggtoll.c.o(.rodata);
        FP_RODATA_END = .;
        FP_RODATA_SIZE = ABSOLUTE(FP_RODATA_END - FP_RODATA_START);
    }
    FP_bss_VRAM = ADDR(.FP_bss);
    .FP_bss (NOLOAD) : SUBALIGN(16)
    {
        FP_BSS_START = .;
        build/us.v10/src/FP/bss_pad.c.o(.bss);
        build/us.v10/src/FP/ch/boggy2.c.o(.bss);
        build/us.v10/src/FP/sirslushgame.c.o(.bss);
        build/us.v10/src/FP/snowmanbuttongame.c.o(.bss);
        build/us.v10/src/FP/racectrl.c.o(.bss);
        build/us.v10/src/FP/ch/xmastreestar.c.o(.bss);
        build/us.v10/src/FP/code_B4D0.c.o(.bss);
        FP_BSS_END = .;
        FP_BSS_SIZE = ABSOLUTE(FP_BSS_END - FP_BSS_START);
    }
    __romPos += SIZEOF(.FP);
    __romPos = ALIGN(__romPos, 16);
    FP_ROM_END = __romPos;
    FP_VRAM_END = .;

    SM_ROM_START = __romPos;
    SM_VRAM = ADDR(.SM);
    .SM core2_VRAM_END : AT(SM_ROM_START) SUBALIGN(16)
    {
        SM_TEXT_START = .;
        build/us.v10/src/SM/code_0.c.o(.text);
        build/us.v10/src/SM/code_F0.c.o(.text);
        build/us.v10/src/SM/code_5B0.c.o(.text);
        build/us.v10/src/SM/code_BF0.c.o(.text);
        build/us.v10/src/SM/ch/attacktutorial.c.o(.text);
        build/us.v10/src/SM/ch/vegetables.c.o(.text);
        build/us.v10/src/SM/code_2900.c.o(.text);
        build/us.v10/src/SM/code_2990.c.o(.text);
        build/us.v10/src/SM/code_3FC0.c.o(.text);
        build/us.v10/src/SM/code_4070.c.o(.text);
        build/us.v10/src/SM/code_44D0.c.o(.text);
        build/us.v10/src/SM/code_46C0.c.o(.text);
        SM_TEXT_END = .;
        SM_TEXT_SIZE = ABSOLUTE(SM_TEXT_END - SM_TEXT_START);
        SM_DATA_START = .;
        SM_code_0_c = .;
        build/us.v10/src/SM/code_0.c.o(.data);
        SM_code_F0_c = .;
        build/us.v10/src/SM/code_F0.c.o(.data);
        SM_code_5B0_c = .;
        build/us.v10/src/SM/code_5B0.c.o(.data);
        SM_code_BF0_c = .;
        build/us.v10/src/SM/code_BF0.c.o(.data);
        SM_ch_attacktutorial_c = .;
        build/us.v10/src/SM/ch/attacktutorial.c.o(.data);
        SM_ch_vegetables_c = .;
        build/us.v10/src/SM/ch/vegetables.c.o(.data);
        SM_code_2990_c = .;
        build/us.v10/src/SM/code_2990.c.o(.data);
        SM_code_3FC0_c = .;
        build/us.v10/src/SM/code_3FC0.c.o(.data);
        SM_code_4070_c = .;
        build/us.v10/src/SM/code_4070.c.o(.data);
        SM_code_44D0_c = .;
        build/us.v10/src/SM/code_44D0.c.o(.data);
        SM_DATA_END = .;
        SM_DATA_SIZE = ABSOLUTE(SM_DATA_END - SM_DATA_START);
        SM_RODATA_START = .;
        build/us.v10/src/SM/code_5B0.c.o(.rodata);
        build/us.v10/src/SM/ch/attacktutorial.c.o(.rodata);
        build/us.v10/src/SM/ch/vegetables.c.o(.rodata);
        build/us.v10/src/SM/code_2990.c.o(.rodata);
        build/us.v10/src/SM/code_44D0.c.o(.rodata);
        SM_RODATA_END = .;
        SM_RODATA_SIZE = ABSOLUTE(SM_RODATA_END - SM_RODATA_START);
    }
    SM_bss_VRAM = ADDR(.SM_bss);
    .SM_bss (NOLOAD) : SUBALIGN(16)
    {
        SM_BSS_START = .;
        build/us.v10/src/SM/code_F0.c.o(.bss);
        SM_BSS_END = .;
        SM_BSS_SIZE = ABSOLUTE(SM_BSS_END - SM_BSS_START);
    }
    __romPos += SIZEOF(.SM);
    __romPos = ALIGN(__romPos, 16);
    SM_ROM_END = __romPos;
    SM_VRAM_END = .;

    cutscenes_ROM_START = __romPos;
    cutscenes_VRAM = ADDR(.cutscenes);
    .cutscenes core2_VRAM_END : AT(cutscenes_ROM_START) SUBALIGN(16)
    {
        cutscenes_TEXT_START = .;
        build/us.v10/src/cutscenes/code_0.c.o(.text);
        build/us.v10/src/cutscenes/code_60F0.c.o(.text);
        build/us.v10/src/cutscenes/code_6730.c.o(.text);
        build/us.v10/src/cutscenes/code_69F0.c.o(.text);
        build/us.v10/src/cutscenes/code_6C90.c.o(.text);
        cutscenes_TEXT_END = .;
        cutscenes_TEXT_SIZE = ABSOLUTE(cutscenes_TEXT_END - cutscenes_TEXT_START);
        cutscenes_DATA_START = .;
        cutscenes_code_0_c = .;
        build/us.v10/src/cutscenes/code_0.c.o(.data);
        cutscenes_code_60F0_c = .;
        build/us.v10/src/cutscenes/code_60F0.c.o(.data);
        cutscenes_code_6730_c = .;
        build/us.v10/src/cutscenes/code_6730.c.o(.data);
        cutscenes_code_69F0_c = .;
        build/us.v10/src/cutscenes/code_69F0.c.o(.data);
        cutscenes_code_6C90_c = .;
        build/us.v10/src/cutscenes/code_6C90.c.o(.data);
        cutscenes_DATA_END = .;
        cutscenes_DATA_SIZE = ABSOLUTE(cutscenes_DATA_END - cutscenes_DATA_START);
        cutscenes_RODATA_START = .;
        build/us.v10/src/cutscenes/code_0.c.o(.rodata);
        build/us.v10/src/cutscenes/code_6730.c.o(.rodata);
        build/us.v10/src/cutscenes/code_69F0.c.o(.rodata);
        build/us.v10/src/cutscenes/code_6C90.c.o(.rodata);
        cutscenes_RODATA_END = .;
        cutscenes_RODATA_SIZE = ABSOLUTE(cutscenes_RODATA_END - cutscenes_RODATA_START);
    }
    cutscenes_bss_VRAM = ADDR(.cutscenes_bss);
    .cutscenes_bss (NOLOAD) : SUBALIGN(16)
    {
        cutscenes_BSS_START = .;
        build/us.v10/src/cutscenes/bss_pad.c.o(.bss);
        cutscenes_BSS_END = .;
        cutscenes_BSS_SIZE = ABSOLUTE(cutscenes_BSS_END - cutscenes_BSS_START);
    }
    __romPos += SIZEOF(.cutscenes);
    __romPos = ALIGN(__romPos, 16);
    cutscenes_ROM_END = __romPos;
    cutscenes_VRAM_END = .;

    lair_ROM_START = __romPos;
    lair_VRAM = ADDR(.lair);
    .lair core2_VRAM_END : AT(lair_ROM_START) SUBALIGN(16)
    {
        lair_TEXT_START = .;
        build/us.v10/src/lair/code_0.c.o(.text);
        build/us.v10/src/lair/ch/cauldron.c.o(.text);
        build/us.v10/src/lair/ch/brentilda.c.o(.text);
        build/us.v10/src/lair/code_5ED0.c.o(.text);
        build/us.v10/src/lair/code_86F0.c.o(.text);
        build/us.v10/src/lair/code_9C40.c.o(.text);
        build/us.v10/src/lair/code_A170.c.o(.text);
        build/us.v10/src/lair/code_A430.c.o(.text);
        build/us.v10/src/lair/code_A4A0.c.o(.text);
        build/us.v10/src/lair/code_A810.c.o(.text);
        build/us.v10/src/lair/code_AD70.c.o(.text);
        build/us.v10/src/lair/code_BBD0.c.o(.text);
        build/us.v10/src/lair/code_C1C0.c.o(.text);
        build/us.v10/src/lair/code_C6C0.c.o(.text);
        lair_TEXT_END = .;
        lair_TEXT_SIZE = ABSOLUTE(lair_TEXT_END - lair_TEXT_START);
        lair_DATA_START = .;
        lair_code_0_c = .;
        build/us.v10/src/lair/code_0.c.o(.data);
        lair_ch_cauldron_c = .;
        build/us.v10/src/lair/ch/cauldron.c.o(.data);
        lair_ch_brentilda_c = .;
        build/us.v10/src/lair/ch/brentilda.c.o(.data);
        lair_code_5ED0_c = .;
        build/us.v10/src/lair/code_5ED0.c.o(.data);
        lair_code_86F0_c = .;
        build/us.v10/src/lair/code_86F0.c.o(.data);
        lair_code_9C40_c = .;
        build/us.v10/src/lair/code_9C40.c.o(.data);
        lair_code_A170_c = .;
        build/us.v10/src/lair/code_A170.c.o(.data);
        lair_code_A430_c = .;
        build/us.v10/src/lair/code_A430.c.o(.data);
        lair_code_A4A0_c = .;
        build/us.v10/src/lair/code_A4A0.c.o(.data);
        lair_code_A810_c = .;
        build/us.v10/src/lair/code_A810.c.o(.data);
        lair_code_AD70_c = .;
        build/us.v10/src/lair/code_AD70.c.o(.data);
        lair_code_BBD0_c = .;
        build/us.v10/src/lair/code_BBD0.c.o(.data);
        lair_code_C1C0_c = .;
        build/us.v10/src/lair/code_C1C0.c.o(.data);
        lair_code_C6C0_c = .;
        build/us.v10/src/lair/code_C6C0.c.o(.data);
        lair_DATA_END = .;
        lair_DATA_SIZE = ABSOLUTE(lair_DATA_END - lair_DATA_START);
        lair_RODATA_START = .;
        build/us.v10/src/lair/code_0.c.o(.rodata);
        build/us.v10/src/lair/ch/cauldron.c.o(.rodata);
        build/us.v10/src/lair/ch/brentilda.c.o(.rodata);
        build/us.v10/src/lair/code_5ED0.c.o(.rodata);
        build/us.v10/src/lair/code_86F0.c.o(.rodata);
        build/us.v10/src/lair/code_9C40.c.o(.rodata);
        build/us.v10/src/lair/code_A4A0.c.o(.rodata);
        build/us.v10/src/lair/code_A810.c.o(.rodata);
        build/us.v10/src/lair/code_AD70.c.o(.rodata);
        build/us.v10/src/lair/code_BBD0.c.o(.rodata);
        build/us.v10/src/lair/code_C1C0.c.o(.rodata);
        build/us.v10/src/lair/code_C6C0.c.o(.rodata);
        lair_RODATA_END = .;
        lair_RODATA_SIZE = ABSOLUTE(lair_RODATA_END - lair_RODATA_START);
    }
    lair_bss_VRAM = ADDR(.lair_bss);
    .lair_bss (NOLOAD) : SUBALIGN(16)
    {
        lair_BSS_START = .;
        build/us.v10/src/lair/bss_pad.c.o(.bss);
        build/us.v10/src/lair/code_0.c.o(.bss);
        build/us.v10/src/lair/code_A810.c.o(.bss);
        lair_BSS_END = .;
        lair_BSS_SIZE = ABSOLUTE(lair_BSS_END - lair_BSS_START);
    }
    __romPos += SIZEOF(.lair);
    __romPos = ALIGN(__romPos, 16);
    lair_ROM_END = __romPos;
    lair_VRAM_END = .;

    fight_ROM_START = __romPos;
    fight_VRAM = ADDR(.fight);
    .fight core2_VRAM_END : AT(fight_ROM_START) SUBALIGN(16)
    {
        fight_TEXT_START = .;
        build/us.v10/src/fight/code_0.c.o(.text);
        build/us.v10/src/fight/chfinalboss.c.o(.text);
        build/us.v10/src/fight/chbossjinjo.c.o(.text);
        build/us.v10/src/fight/chbossjinjobase.c.o(.text);
        build/us.v10/src/fight/chstonejinjo.c.o(.text);
        build/us.v10/src/fight/chjinjonatorbase.c.o(.text);
        build/us.v10/src/fight/chspellbarrier.c.o(.text);
        build/us.v10/src/fight/chspellfireball.c.o(.text);
        build/us.v10/src/fight/chgreenblast.c.o(.text);
        build/us.v10/src/fight/chjinjonator.c.o(.text);
        build/us.v10/src/fight/chbossshadow.c.o(.text);
        fight_TEXT_END = .;
        fight_TEXT_SIZE = ABSOLUTE(fight_TEXT_END - fight_TEXT_START);
        fight_DATA_START = .;
        fight_chfinalboss_c = .;
        build/us.v10/src/fight/chfinalboss.c.o(.data);
        fight_chbossjinjo_c = .;
        build/us.v10/src/fight/chbossjinjo.c.o(.data);
        fight_chbossjinjobase_c = .;
        build/us.v10/src/fight/chbossjinjobase.c.o(.data);
        fight_chstonejinjo_c = .;
        build/us.v10/src/fight/chstonejinjo.c.o(.data);
        fight_chjinjonatorbase_c = .;
        build/us.v10/src/fight/chjinjonatorbase.c.o(.data);
        fight_chspellbarrier_c = .;
        build/us.v10/src/fight/chspellbarrier.c.o(.data);
        fight_chspellfireball_c = .;
        build/us.v10/src/fight/chspellfireball.c.o(.data);
        fight_chgreenblast_c = .;
        build/us.v10/src/fight/chgreenblast.c.o(.data);
        fight_chjinjonator_c = .;
        build/us.v10/src/fight/chjinjonator.c.o(.data);
        fight_chbossshadow_c = .;
        build/us.v10/src/fight/chbossshadow.c.o(.data);
        fight_DATA_END = .;
        fight_DATA_SIZE = ABSOLUTE(fight_DATA_END - fight_DATA_START);
        fight_RODATA_START = .;
        build/us.v10/src/fight/chfinalboss.c.o(.rodata);
        build/us.v10/src/fight/chbossjinjo.c.o(.rodata);
        build/us.v10/src/fight/chbossjinjobase.c.o(.rodata);
        build/us.v10/src/fight/chstonejinjo.c.o(.rodata);
        build/us.v10/src/fight/chjinjonatorbase.c.o(.rodata);
        build/us.v10/src/fight/chspellbarrier.c.o(.rodata);
        build/us.v10/src/fight/chspellfireball.c.o(.rodata);
        build/us.v10/src/fight/chgreenblast.c.o(.rodata);
        build/us.v10/src/fight/chjinjonator.c.o(.rodata);
        build/us.v10/src/fight/chbossshadow.c.o(.rodata);
        fight_RODATA_END = .;
        fight_RODATA_SIZE = ABSOLUTE(fight_RODATA_END - fight_RODATA_START);
    }
    fight_bss_VRAM = ADDR(.fight_bss);
    .fight_bss (NOLOAD) : SUBALIGN(16)
    {
        fight_BSS_START = .;
        build/us.v10/src/fight/code_0.c.o(.bss);
        build/us.v10/src/fight/chfinalboss.c.o(.bss);
        build/us.v10/src/fight/chspellfireball.c.o(.bss);
        build/us.v10/src/fight/chjinjonator.c.o(.bss);
        fight_BSS_END = .;
        fight_BSS_SIZE = ABSOLUTE(fight_BSS_END - fight_BSS_START);
    }
    __romPos += SIZEOF(.fight);
    __romPos = ALIGN(__romPos, 16);
    fight_ROM_END = __romPos;
    fight_VRAM_END = .;

    CCW_ROM_START = __romPos;
    CCW_VRAM = ADDR(.CCW);
    .CCW core2_VRAM_END : AT(CCW_ROM_START) SUBALIGN(16)
    {
        CCW_TEXT_START = .;
        build/us.v10/src/CCW/code_0.c.o(.text);
        build/us.v10/src/CCW/code_160.c.o(.text);
        build/us.v10/src/CCW/code_950.c.o(.text);
        build/us.v10/src/CCW/code_14B0.c.o(.text);
        build/us.v10/src/CCW/code_1B20.c.o(.text);
        build/us.v10/src/CCW/code_21A0.c.o(.text);
        build/us.v10/src/CCW/code_2270.c.o(.text);
        build/us.v10/src/CCW/code_2B00.c.o(.text);
        build/us.v10/src/CCW/code_3050.c.o(.text);
        build/us.v10/src/CCW/code_3310.c.o(.text);
        build/us.v10/src/CCW/code_3DA0.c.o(.text);
        build/us.v10/src/CCW/code_4530.c.o(.text);
        build/us.v10/src/CCW/code_4960.c.o(.text);
        build/us.v10/src/CCW/code_4D00.c.o(.text);
        build/us.v10/src/CCW/code_50D0.c.o(.text);
        build/us.v10/src/CCW/code_5540.c.o(.text);
        build/us.v10/src/CCW/code_5BF0.c.o(.text);
        build/us.v10/src/CCW/code_61E0.c.o(.text);
        build/us.v10/src/CCW/code_6620.c.o(.text);
        build/us.v10/src/CCW/code_6AC0.c.o(.text);
        build/us.v10/src/CCW/code_6EC0.c.o(.text);
        build/us.v10/src/CCW/code_7120.c.o(.text);
        build/us.v10/src/CCW/code_7570.c.o(.text);
        build/us.v10/src/CCW/code_76C0.c.o(.text);
        build/us.v10/src/CCW/code_7BC0.c.o(.text);
        build/us.v10/src/CCW/code_7BF0.c.o(.text);
        build/us.v10/src/CCW/ch/grublinhood.c.o(.text);
        build/us.v10/src/CCW/ch/vacationtexttrigger.c.o(.text);
        CCW_TEXT_END = .;
        CCW_TEXT_SIZE = ABSOLUTE(CCW_TEXT_END - CCW_TEXT_START);
        CCW_DATA_START = .;
        CCW_code_0_c = .;
        build/us.v10/src/CCW/code_0.c.o(.data);
        CCW_code_160_c = .;
        build/us.v10/src/CCW/code_160.c.o(.data);
        CCW_code_950_c = .;
        build/us.v10/src/CCW/code_950.c.o(.data);
        CCW_code_14B0_c = .;
        build/us.v10/src/CCW/code_14B0.c.o(.data);
        CCW_code_1B20_c = .;
        build/us.v10/src/CCW/code_1B20.c.o(.data);
        CCW_code_21A0_c = .;
        build/us.v10/src/CCW/code_21A0.c.o(.data);
        CCW_code_2270_c = .;
        build/us.v10/src/CCW/code_2270.c.o(.data);
        CCW_code_2B00_c = .;
        build/us.v10/src/CCW/code_2B00.c.o(.data);
        CCW_code_3050_c = .;
        build/us.v10/src/CCW/code_3050.c.o(.data);
        CCW_code_3310_c = .;
        build/us.v10/src/CCW/code_3310.c.o(.data);
        CCW_code_3DA0_c = .;
        build/us.v10/src/CCW/code_3DA0.c.o(.data);
        CCW_code_4530_c = .;
        build/us.v10/src/CCW/code_4530.c.o(.data);
        CCW_code_4960_c = .;
        build/us.v10/src/CCW/code_4960.c.o(.data);
        CCW_code_4D00_c = .;
        build/us.v10/src/CCW/code_4D00.c.o(.data);
        CCW_code_50D0_c = .;
        build/us.v10/src/CCW/code_50D0.c.o(.data);
        CCW_code_5540_c = .;
        build/us.v10/src/CCW/code_5540.c.o(.data);
        CCW_code_5BF0_c = .;
        build/us.v10/src/CCW/code_5BF0.c.o(.data);
        CCW_code_61E0_c = .;
        build/us.v10/src/CCW/code_61E0.c.o(.data);
        CCW_code_6620_c = .;
        build/us.v10/src/CCW/code_6620.c.o(.data);
        CCW_code_6AC0_c = .;
        build/us.v10/src/CCW/code_6AC0.c.o(.data);
        CCW_code_6EC0_c = .;
        build/us.v10/src/CCW/code_6EC0.c.o(.data);
        CCW_code_7120_c = .;
        build/us.v10/src/CCW/code_7120.c.o(.data);
        CCW_code_7570_c = .;
        build/us.v10/src/CCW/code_7570.c.o(.data);
        CCW_code_76C0_c = .;
        build/us.v10/src/CCW/code_76C0.c.o(.data);
        CCW_code_7BC0_c = .;
        build/us.v10/src/CCW/code_7BC0.c.o(.data);
        CCW_code_7BF0_c = .;
        build/us.v10/src/CCW/code_7BF0.c.o(.data);
        CCW_ch_grublinhood_c = .;
        build/us.v10/src/CCW/ch/grublinhood.c.o(.data);
        CCW_ch_vacationtexttrigger_c = .;
        build/us.v10/src/CCW/ch/vacationtexttrigger.c.o(.data);
        CCW_DATA_END = .;
        CCW_DATA_SIZE = ABSOLUTE(CCW_DATA_END - CCW_DATA_START);
        CCW_RODATA_START = .;
        build/us.v10/src/CCW/code_160.c.o(.rodata);
        build/us.v10/src/CCW/code_950.c.o(.rodata);
        build/us.v10/src/CCW/code_1B20.c.o(.rodata);
        build/us.v10/src/CCW/code_2270.c.o(.rodata);
        build/us.v10/src/CCW/code_2B00.c.o(.rodata);
        build/us.v10/src/CCW/code_3310.c.o(.rodata);
        build/us.v10/src/CCW/code_3DA0.c.o(.rodata);
        build/us.v10/src/CCW/code_4530.c.o(.rodata);
        build/us.v10/src/CCW/code_4960.c.o(.rodata);
        build/us.v10/src/CCW/code_4D00.c.o(.rodata);
        build/us.v10/src/CCW/code_50D0.c.o(.rodata);
        build/us.v10/src/CCW/code_5540.c.o(.rodata);
        build/us.v10/src/CCW/code_5BF0.c.o(.rodata);
        build/us.v10/src/CCW/code_61E0.c.o(.rodata);
        build/us.v10/src/CCW/code_6620.c.o(.rodata);
        build/us.v10/src/CCW/code_6AC0.c.o(.rodata);
        build/us.v10/src/CCW/code_76C0.c.o(.rodata);
        build/us.v10/src/CCW/code_7BF0.c.o(.rodata);
        build/us.v10/src/CCW/ch/grublinhood.c.o(.rodata);
        CCW_RODATA_END = .;
        CCW_RODATA_SIZE = ABSOLUTE(CCW_RODATA_END - CCW_RODATA_START);
    }
    CCW_bss_VRAM = ADDR(.CCW_bss);
    .CCW_bss (NOLOAD) : SUBALIGN(16)
    {
        CCW_BSS_START = .;
        build/us.v10/src/CCW/bss_pad.c.o(.bss);
        build/us.v10/src/CCW/code_3310.c.o(.bss);
        CCW_BSS_END = .;
        CCW_BSS_SIZE = ABSOLUTE(CCW_BSS_END - CCW_BSS_START);
    }
    __romPos += SIZEOF(.CCW);
    __romPos = ALIGN(__romPos, 16);
    CCW_ROM_END = __romPos;
    CCW_VRAM_END = .;

    emptyLvl_ROM_START = __romPos;
    emptyLvl_VRAM = ADDR(.emptyLvl);
    .emptyLvl core2_VRAM_END : AT(emptyLvl_ROM_START) SUBALIGN(16)
    {
        emptyLvl_TEXT_START = .;
        build/us.v10/src/emptyLvl/code_0.c.o(.text);
        emptyLvl_TEXT_END = .;
        emptyLvl_TEXT_SIZE = ABSOLUTE(emptyLvl_TEXT_END - emptyLvl_TEXT_START);
        emptyLvl_DATA_START = .;
        emptyLvl_code_0_c = .;
        build/us.v10/src/emptyLvl/code_0.c.o(.data);
        emptyLvl_DATA_END = .;
        emptyLvl_DATA_SIZE = ABSOLUTE(emptyLvl_DATA_END - emptyLvl_DATA_START);
        emptyLvl_RODATA_START = .;
        build/us.v10/src/emptyLvl/code_0.c.o(.rodata);
        emptyLvl_RODATA_END = .;
        emptyLvl_RODATA_SIZE = ABSOLUTE(emptyLvl_RODATA_END - emptyLvl_RODATA_START);
    }
    emptyLvl_bss_VRAM = ADDR(.emptyLvl_bss);
    .emptyLvl_bss (NOLOAD) : SUBALIGN(16)
    {
        emptyLvl_BSS_START = .;
        build/us.v10/src/emptyLvl/code_0.c.o(.bss);
        emptyLvl_BSS_END = .;
        emptyLvl_BSS_SIZE = ABSOLUTE(emptyLvl_BSS_END - emptyLvl_BSS_START);
    }
    __romPos += SIZEOF(.emptyLvl);
    __romPos = ALIGN(__romPos, 16);
    emptyLvl_ROM_END = __romPos;
    emptyLvl_VRAM_END = .;

.rodata : {
    *(.rodata)
    *(.rodata.*)
}
    /DISCARD/ :
    {
        *(*);
    }

}
